VERSION "HNNBNNNYNNNNNNNNNNNNNNNNNNNNNNNNNNNNNNNNNN/4/%%%/4/'%**4NNN///"

NS_ :

BS_:

BU_: BAP_Tester BCM Gateway_Max TSGGen3_BFS TSGGen3_FS TSGGen3_HBFS TSGGen3_HFS WLC_01_CFD

BO_ 1427 BCM_Kessy_01: 8 BCM
 SG_ KY_IDGeber_1_Status : 0|3@1+ (1.0,0.0) [0.0|7] ""  Gateway_Max
 SG_ KY_IDGeber_2_Status : 3|3@1+ (1.0,0.0) [0.0|7] ""  Gateway_Max
 SG_ KY_Softtouch : 6|1@1+ (1.0,0.0) [0.0|1] ""  Gateway_Max
 SG_ KY_HD_Verriegelung_Autorisiert : 7|1@1+ (1.0,0.0) [0.0|1] ""  Gateway_Max
 SG_ KY_IDGeber_3_Status : 8|3@1+ (1.0,0.0) [0.0|7] ""  Gateway_Max
 SG_ KY_IDGeber_4_Status : 11|3@1+ (1.0,0.0) [0.0|7] ""  Gateway_Max
 SG_ ZV_Anf_Abschaltung_Zuendung : 14|1@1+ (1.0,0.0) [0.0|1] ""  Gateway_Max
 SG_ KY_FFB_in_LF_Reichw : 15|1@1+ (1.0,0.0) [0.0|1] ""  Gateway_Max
 SG_ KY_IDGeber_1_Bat : 16|2@1+ (1.0,0.0) [0.0|3] ""  Gateway_Max
 SG_ KY_IDGeber_2_Bat : 18|2@1+ (1.0,0.0) [0.0|3] ""  Gateway_Max
 SG_ KY_IDGeber_3_Bat : 20|2@1+ (1.0,0.0) [0.0|3] ""  Gateway_Max
 SG_ KY_IDGeber_4_Bat : 22|2@1+ (1.0,0.0) [0.0|3] ""  Gateway_Max
 SG_ KY_RSSI_Wert : 24|16@1+ (1.0,0.0) [0.0|65535] ""  Gateway_Max
 SG_ KY_Nr_IDGeber_Autofkt : 40|4@1+ (1.0,0.0) [0.0|15] ""  Gateway_Max
 SG_ KY_KessyEntryExit_Akt : 44|1@1+ (1.0,0.0) [0.0|1] ""  Gateway_Max
 SG_ KY_Autofunktion_Aktiv : 45|1@1+ (1.0,0.0) [0.0|1] ""  Gateway_Max
 SG_ KY_Anf_Reichwbegr : 46|1@1+ (1.0,0.0) [0.0|1] ""  Gateway_Max
 SG_ KY_Anf_Reichwbegr_Gesamt : 47|1@1+ (1.0,0.0) [0.0|1] ""  Gateway_Max
 SG_ KY_Bedienstelle : 48|6@1+ (1.0,0.0) [0.0|63] ""  Gateway_Max
 SG_ KY_Verriegeln : 54|1@1+ (1.0,0.0) [0.0|1] ""  Gateway_Max
 SG_ KY_Entriegeln : 55|1@1+ (1.0,0.0) [0.0|1] ""  Gateway_Max
 SG_ KY_ZV_CMD : 56|4@1+ (1.0,0.0) [0.0|15] ""  Gateway_Max
 SG_ KY_Schluesselnr : 60|4@1+ (1.0,0.0) [0.0|15] ""  Gateway_Max

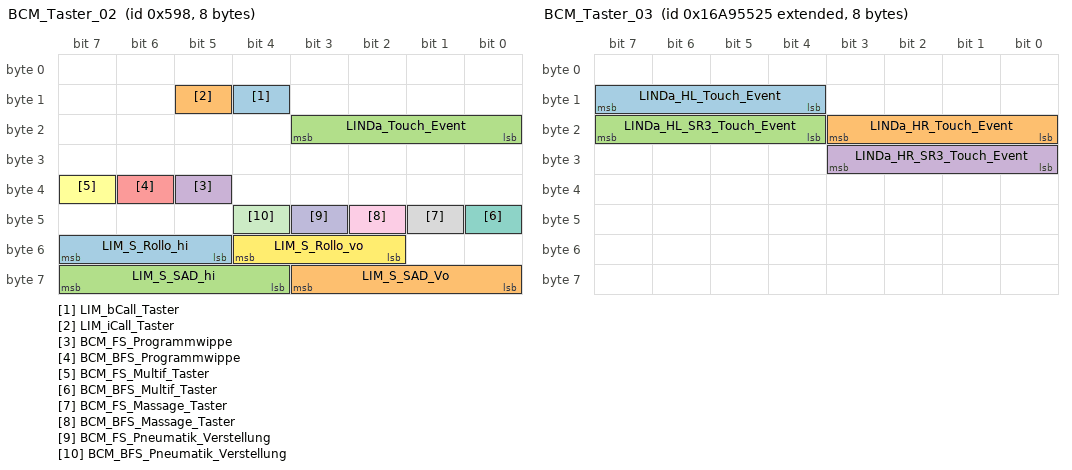
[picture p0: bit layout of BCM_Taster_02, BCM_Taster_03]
BO_ 1432 BCM_Taster_02: 8 BCM
 SG_ LIM_bCall_Taster : 12|1@1+ (1.0,0.0) [0.0|1] ""  Gateway_Max
 SG_ LIM_iCall_Taster : 13|1@1+ (1.0,0.0) [0.0|1] ""  Gateway_Max
 SG_ LINDa_Touch_Event : 16|4@1+ (1.0,0.0) [0.0|15] ""  Gateway_Max
 SG_ BCM_FS_Programmwippe : 37|1@1+ (1.0,0.0) [0.0|1] ""  Gateway_Max
 SG_ BCM_BFS_Programmwippe : 38|1@1+ (1.0,0.0) [0.0|1] ""  Gateway_Max
 SG_ BCM_FS_Multif_Taster : 39|1@1+ (1.0,0.0) [0.0|1] ""  Gateway_Max
 SG_ BCM_BFS_Multif_Taster : 40|1@1+ (1.0,0.0) [0.0|1] ""  Gateway_Max
 SG_ BCM_FS_Massage_Taster : 41|1@1+ (1.0,0.0) [0.0|1] ""  Gateway_Max
 SG_ BCM_BFS_Massage_Taster : 42|1@1+ (1.0,0.0) [0.0|1] ""  Gateway_Max
 SG_ BCM_FS_Pneumatik_Verstellung : 43|1@1+ (1.0,0.0) [0.0|1] ""  Gateway_Max
 SG_ BCM_BFS_Pneumatik_Verstellung : 44|1@1+ (1.0,0.0) [0.0|1] ""  Gateway_Max
 SG_ LIM_S_Rollo_vo : 50|3@1+ (1.0,0.0) [0.0|7] ""  Gateway_Max
 SG_ LIM_S_Rollo_hi : 53|3@1+ (1.0,0.0) [0.0|7] ""  Gateway_Max
 SG_ LIM_S_SAD_Vo : 56|4@1+ (1.0,0.0) [0.0|15] ""  Gateway_Max
 SG_ LIM_S_SAD_hi : 60|4@1+ (1.0,0.0) [0.0|15] ""  Gateway_Max

BO_ 2527679781 BCM_Taster_03: 8 BCM
 SG_ LINDa_HL_Touch_Event : 12|4@1+ (1.0,0.0) [0.0|15] ""  Gateway_Max
 SG_ LINDa_HR_Touch_Event : 16|4@1+ (1.0,0.0) [0.0|15] ""  Gateway_Max
 SG_ LINDa_HL_SR3_Touch_Event : 20|4@1+ (1.0,0.0) [0.0|15] ""  Gateway_Max
 SG_ LINDa_HR_SR3_Touch_Event : 24|4@1+ (1.0,0.0) [0.0|15] ""  Gateway_Max

BO_ 2463978855 BCM_ZDML_02: 8 BCM
 SG_ DML_HMI_FCN_CROSSINGLI_REQUEST : 12|1@1+ (1.0,0.0) [0.0|1] ""  Gateway_Max
 SG_ DML_HMI_FCN_HAZARDWARN_REQUEST : 13|1@1+ (1.0,0.0) [0.0|1] ""  Gateway_Max
 SG_ DML_HMI_FCN_LANELIGHT_REQUEST : 14|1@1+ (1.0,0.0) [0.0|1] ""  Gateway_Max
 SG_ DML_HMI_FCN_LANLEAVELI_REQUEST : 15|1@1+ (1.0,0.0) [0.0|1] ""  Gateway_Max
 SG_ DML_HMI_FCN_MALI_REQUEST : 16|1@1+ (1.0,0.0) [0.0|1] ""  Gateway_Max
 SG_ DML_HMI_FCN_ORLI_REQUEST : 17|1@1+ (1.0,0.0) [0.0|1] ""  Gateway_Max
 SG_ DML_HMI_FCN_RESALLEYHI_REQUEST : 18|1@1+ (1.0,0.0) [0.0|1] ""  Gateway_Max
 SG_ DML_HMI_FCN_ROADWORKLI_REQUEST : 19|1@1+ (1.0,0.0) [0.0|1] ""  Gateway_Max
 SG_ DML_HMI_FCN_SAFETYZONE_REQUEST : 20|1@1+ (1.0,0.0) [0.0|1] ""  Gateway_Max
 SG_ DML_HMI_FCN_TURNLIGHPR_REQUEST : 21|1@1+ (1.0,0.0) [0.0|1] ""  Gateway_Max
 SG_ DML_ConstructionZone_Enabled : 22|1@1+ (1.0,0.0) [0.0|1] ""  Gateway_Max
 SG_ DML_CrossingAssist_Enabled : 23|1@1+ (1.0,0.0) [0.0|1] ""  Gateway_Max
 SG_ DML_GhostDriverWarn_Enabled : 24|1@1+ (1.0,0.0) [0.0|1] ""  Gateway_Max
 SG_ DML_GlarefreeHB_Enabled : 25|1@1+ (1.0,0.0) [0.0|1] ""  Gateway_Max
 SG_ DML_HazardWarning_Enabled : 26|1@1+ (1.0,0.0) [0.0|1] ""  Gateway_Max
 SG_ DML_Indicator_Enabled : 27|1@1+ (1.0,0.0) [0.0|1] ""  Gateway_Max
 SG_ DML_IntelligentHB_Enabled : 28|1@1+ (1.0,0.0) [0.0|1] ""  Gateway_Max
 SG_ DML_LaneDepartureWarn_Enabled : 29|1@1+ (1.0,0.0) [0.0|1] ""  Gateway_Max
 SG_ DML_LaneLight_Enabled : 30|1@1+ (1.0,0.0) [0.0|1] ""  Gateway_Max
 SG_ DML_MarkingLight_Enabled : 31|1@1+ (1.0,0.0) [0.0|1] ""  Gateway_Max
 SG_ DML_OrientationLight_Enabled : 32|1@1+ (1.0,0.0) [0.0|1] ""  Gateway_Max
 SG_ DML_RescueLaneNotice_Enabled : 33|1@1+ (1.0,0.0) [0.0|1] ""  Gateway_Max
 SG_ DML_SafetyZone_Enabled : 34|1@1+ (1.0,0.0) [0.0|1] ""  Gateway_Max
 SG_ DML_SaftyDistance_Enabled : 35|1@1+ (1.0,0.0) [0.0|1] ""  Gateway_Max
 SG_ DML_SideAssist_Enabled : 36|1@1+ (1.0,0.0) [0.0|1] ""  Gateway_Max

BO_ 1635 BEM_02: 8 Gateway_Max
 SG_ NVEM_Abschaltstufe : 0|2@1+ (1.0,0.0) [0.0|3] ""  BCM,TSGGen3_BFS,TSGGen3_FS,TSGGen3_HBFS,TSGGen3_HFS,WLC_01_CFD
 SG_ BEM_STH_Zielzeit : 3|4@1+ (5,0) [0|60] "Unit_Minut"  BCM
 SG_ BEM_MMI_Vorwarnung : 7|1@1+ (1.0,0.0) [0.0|1] ""  BCM
 SG_ BEM_HL_Kontingentierung : 8|6@1+ (50,-1000) [-1000|1000] "Unit_Watt"  BCM
 SG_ NVEM_Freigabe_ZusBatt_Laden : 14|1@1+ (1.0,0.0) [0.0|1] ""  BCM
 SG_ NVEM_Anf_SD_schalten : 15|1@1+ (1.0,0.0) [0.0|1] ""  BCM
 SG_ BEM_Generatordiagnose : 16|2@1+ (1.0,0.0) [0.0|3] ""  BCM
 SG_ BEM_Red_Innengeblaese : 18|2@1+ (1.0,0.0) [0.0|3] ""  BCM
 SG_ BEM_STH_Einschaltverbot : 20|1@1+ (1.0,0.0) [0.0|1] ""  BCM
 SG_ BEM_HL_Regelung_Status : 21|3@1+ (1.0,0.0) [0.0|7] ""  BCM
 SG_ BEM_Ladezustand : 24|4@1+ (10,0) [0|100] "Unit_PerCent"  BCM
 SG_ BEM_Batteriediagnose : 28|3@1+ (1.0,0.0) [0.0|7] ""  BCM
 SG_ MIB_Stromsparmodus : 31|1@1+ (1.0,0.0) [0.0|1] ""  BCM
 SG_ BEM_DFM : 32|5@1+ (3.225,0.025) [0.025|100.000] ""  BCM
 SG_ BEM_REK_aktiv : 37|1@1+ (1.0,0.0) [0.0|1] ""  BCM
 SG_ BEM_EMLIN_ungueltig : 38|1@1+ (1.0,0.0) [0.0|1] ""  BCM
 SG_ BEM_Batt_Ab : 39|1@1+ (1.0,0.0) [0.0|1] ""  BCM
 SG_ BEM_UBDM : 40|8@1+ (0.05,5) [5.05|17.70] "Unit_Volt"  BCM
 SG_ BEM_UGenSoll : 48|6@1+ (0.1,10.6) [10.6|16.0] "Unit_Volt"  BCM
 SG_ BEM_Anf_KL15_schalten : 54|2@1+ (1.0,0.0) [0.0|3] ""  BCM
 SG_ NVEM_Batterie_Service : 56|2@1+ (1.0,0.0) [0.0|3] ""  BCM
 SG_ NVEM_Freigabe_OnlineUpdate : 58|1@1+ (1.0,0.0) [0.0|1] ""  BCM,TSGGen3_BFS,TSGGen3_FS,TSGGen3_HBFS,TSGGen3_HFS,WLC_01_CFD
 SG_ NVEM_Freigabe_ORU4 : 59|2@1+ (1.0,0.0) [0.0|3] ""  BCM
 SG_ NVEM_Verbraucherabsch_Anz : 61|1@1+ (1.0,0.0) [0.0|1] ""  BCM

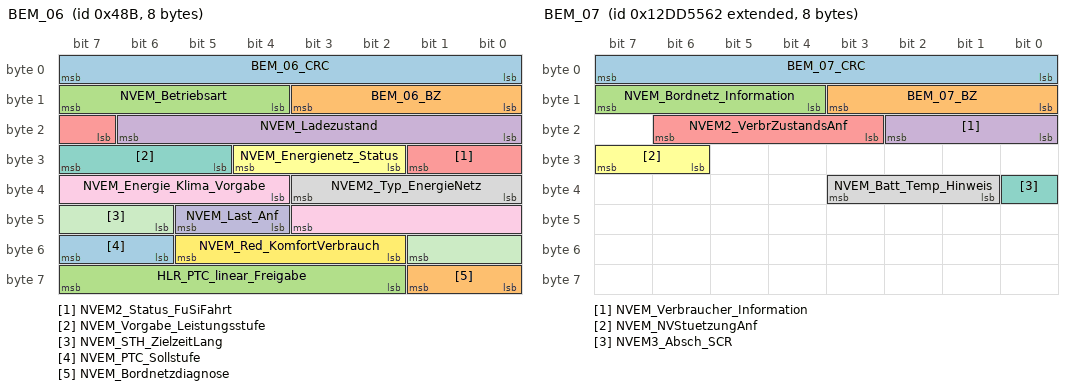
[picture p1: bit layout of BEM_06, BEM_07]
BO_ 1163 BEM_06: 8 Gateway_Max
 SG_ BEM_06_CRC : 0|8@1+ (1,0) [0|255] ""  Vector__XXX
 SG_ BEM_06_BZ : 8|4@1+ (1,0) [0|15] ""  Vector__XXX
 SG_ NVEM_Betriebsart : 12|4@1+ (1.0,0.0) [0.0|15] ""  Vector__XXX
 SG_ NVEM_Ladezustand : 16|7@1+ (1,0) [0|100] "Unit_PerCent"  Vector__XXX
 SG_ NVEM2_Status_FuSiFahrt : 23|3@1+ (1.0,0.0) [0.0|7] ""  Vector__XXX
 SG_ NVEM_Energienetz_Status : 26|3@1+ (1.0,0.0) [0.0|7] ""  Vector__XXX
 SG_ NVEM_Vorgabe_Leistungsstufe : 29|3@1+ (1.0,0.0) [0.0|7] ""  Vector__XXX
 SG_ NVEM2_Typ_EnergieNetz : 32|4@1+ (1.0,0.0) [0.0|15] ""  Vector__XXX
 SG_ NVEM_Energie_Klima_Vorgabe : 36|8@1+ (10,0) [0|2530] "Unit_WattHour"  Vector__XXX
 SG_ NVEM_Last_Anf : 44|2@1+ (1.0,0.0) [0.0|3] ""  TSGGen3_BFS,TSGGen3_FS,TSGGen3_HBFS,TSGGen3_HFS
 SG_ NVEM_STH_ZielzeitLang : 46|4@1+ (10,0) [0|120] "Unit_Minut"  Vector__XXX
 SG_ NVEM_Red_KomfortVerbrauch : 50|4@1+ (1.0,0.0) [0.0|15] ""  Vector__XXX
 SG_ NVEM_PTC_Sollstufe : 54|2@1+ (1.0,0.0) [0.0|3] ""  Vector__XXX
 SG_ NVEM_Bordnetzdiagnose : 56|2@1+ (1.0,0.0) [0.0|3] ""  Vector__XXX
 SG_ HLR_PTC_linear_Freigabe : 58|6@1+ (50,0) [0|3100] "Unit_Watt"  Vector__XXX

BO_ 2463978850 BEM_07: 8 Gateway_Max
 SG_ BEM_07_CRC : 0|8@1+ (1,0) [0|255] ""  Vector__XXX
 SG_ BEM_07_BZ : 8|4@1+ (1,0) [0|15] ""  Vector__XXX
 SG_ NVEM_Bordnetz_Information : 12|4@1+ (1.0,0.0) [0.0|15] ""  Vector__XXX
 SG_ NVEM_Verbraucher_Information : 16|3@1+ (1.0,0.0) [0.0|7] ""  Vector__XXX
 SG_ NVEM2_VerbrZustandsAnf : 19|4@1+ (1.0,0.0) [0.0|15] ""  TSGGen3_BFS,TSGGen3_FS
 SG_ NVEM_NVStuetzungAnf : 30|2@1+ (1.0,0.0) [0.0|3] ""  Vector__XXX
 SG_ NVEM3_Absch_SCR : 32|1@1+ (1.0,0.0) [0.0|1] ""  Vector__XXX
 SG_ NVEM_Batt_Temp_Hinweis : 33|3@1+ (1.0,0.0) [0.0|7] ""  Vector__XXX

BO_ 870 Blinkmodi_02: 8 BCM
 SG_ Blinkmodi_02_CRC : 0|8@1+ (1,0) [0|255] ""  Gateway_Max,TSGGen3_BFS,TSGGen3_FS
 SG_ Blinkmodi_02_BZ : 8|4@1+ (1,0) [0|15] ""  Gateway_Max,TSGGen3_BFS,TSGGen3_FS
 SG_ BM_ZV_auf : 12|1@1+ (1.0,0.0) [0.0|1] ""  Gateway_Max
 SG_ BM_ZV_zu : 13|1@1+ (1.0,0.0) [0.0|1] ""  Gateway_Max
 SG_ BM_DWA_ein : 14|1@1+ (1.0,0.0) [0.0|1] ""  Gateway_Max
 SG_ BM_DWA_Alarm : 15|1@1+ (1.0,0.0) [0.0|1] ""  Gateway_Max
 SG_ BM_Crash : 16|1@1+ (1.0,0.0) [0.0|1] ""  Gateway_Max
 SG_ BM_Panik : 17|1@1+ (1.0,0.0) [0.0|1] ""  Gateway_Max
 SG_ BM_Not_Bremsung : 18|1@1+ (1.0,0.0) [0.0|1] ""  Gateway_Max
 SG_ BM_GDO : 19|1@1+ (1.0,0.0) [0.0|1] ""  Gateway_Max
 SG_ BM_Warnblinken : 20|1@1+ (1.0,0.0) [0.0|1] ""  Gateway_Max
 SG_ BM_Taxi_Notalarm : 21|1@1+ (1.0,0.0) [0.0|1] ""  Gateway_Max
 SG_ BM_Telematik : 22|1@1+ (1.0,0.0) [0.0|1] ""  Gateway_Max
 SG_ BM_links : 23|1@1+ (1.0,0.0) [0.0|1] ""  Gateway_Max
 SG_ BM_rechts : 24|1@1+ (1.0,0.0) [0.0|1] ""  Gateway_Max
 SG_ Blinken_li_Fzg_Takt : 25|1@1+ (1.0,0.0) [0.0|1] ""  Gateway_Max,TSGGen3_BFS,TSGGen3_FS
 SG_ Blinken_re_Fzg_Takt : 26|1@1+ (1.0,0.0) [0.0|1] ""  Gateway_Max,TSGGen3_BFS,TSGGen3_FS
 SG_ Blinken_li_Kombi_Takt : 27|1@1+ (1.0,0.0) [0.0|1] ""  Gateway_Max
 SG_ Blinken_re_Kombi_Takt : 28|1@1+ (1.0,0.0) [0.0|1] ""  Gateway_Max
 SG_ BM_NBA_n_codiert_n_aktiv : 29|1@1+ (1.0,0.0) [0.0|1] ""  Gateway_Max
 SG_ BM_NBA_Status : 30|2@1+ (1.0,0.0) [0.0|3] ""  Gateway_Max
 SG_ BM_WBT_Beleuchtung : 32|1@1+ (1.0,0.0) [0.0|1] ""  Gateway_Max
 SG_ BM_HD_Oeffnung_angelernt : 33|1@1+ (1.0,0.0) [0.0|1] ""  Gateway_Max
 SG_ BM_Autobahn : 34|1@1+ (1.0,0.0) [0.0|1] ""  Gateway_Max
 SG_ BM_Rollenmodus_Blinken : 35|1@1+ (1.0,0.0) [0.0|1] ""  Gateway_Max
 SG_ BM_Recas : 36|1@1+ (1.0,0.0) [0.0|1] ""  Gateway_Max
 SG_ BM_Wischblinken : 37|1@1+ (1.0,0.0) [0.0|1] ""  Gateway_Max
 SG_ BM_Telematik_Abbruchgrund : 38|6@1+ (1.0,0.0) [0.0|63] ""  Gateway_Max
 SG_ BM_PiloPa : 44|1@1+ (1.0,0.0) [0.0|1] ""  Gateway_Max
 SG_ SAL_TA_Blinken_Status : 45|3@1+ (1.0,0.0) [0.0|7] ""  Gateway_Max
 SG_ BM_WBA_Warnblinken : 48|1@1+ (1.0,0.0) [0.0|1] ""  Gateway_Max
 SG_ SAL_RHP_Blinken_Status : 49|3@1+ (1.0,0.0) [0.0|7] ""  Gateway_Max
 SG_ SAL_RHP_Warnblinken : 52|1@1+ (1.0,0.0) [0.0|1] ""  Gateway_Max

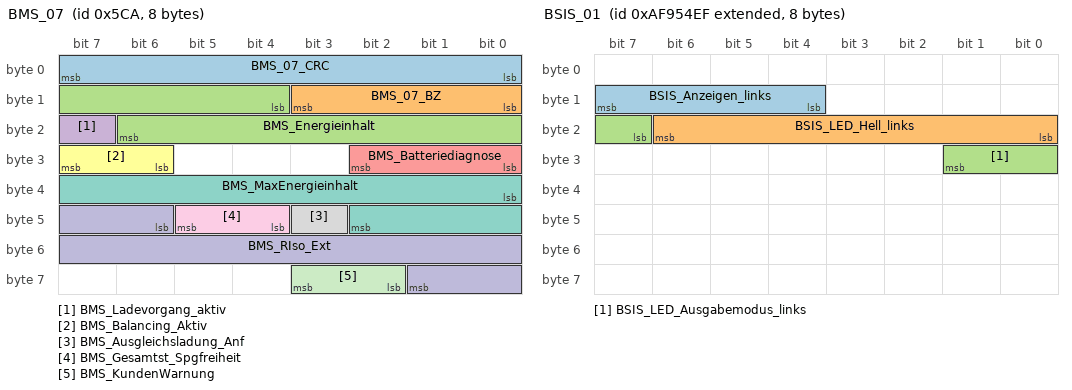
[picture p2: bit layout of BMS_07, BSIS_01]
BO_ 1482 BMS_07: 8 Gateway_Max
 SG_ BMS_07_CRC : 0|8@1+ (1,0) [0|255] ""  Vector__XXX
 SG_ BMS_07_BZ : 8|4@1+ (1,0) [0|15] ""  Vector__XXX
 SG_ BMS_Energieinhalt : 12|11@1+ (50,0) [0|102250] "Unit_WattHour"  Vector__XXX
 SG_ BMS_Ladevorgang_aktiv : 23|1@1+ (1.0,0.0) [0.0|1] ""  Vector__XXX
 SG_ BMS_Batteriediagnose : 24|3@1+ (1.0,0.0) [0.0|7] ""  Vector__XXX
 SG_ BMS_Balancing_Aktiv : 30|2@1+ (1.0,0.0) [0.0|3] ""  Vector__XXX
 SG_ BMS_MaxEnergieinhalt : 32|11@1+ (50,0) [0|102250] "Unit_WattHour"  Vector__XXX
 SG_ BMS_Ausgleichsladung_Anf : 43|1@1+ (1.0,0.0) [0.0|1] ""  Vector__XXX
 SG_ BMS_Gesamtst_Spgfreiheit : 44|2@1+ (1.0,0.0) [0.0|3] ""  Vector__XXX
 SG_ BMS_RIso_Ext : 46|12@1+ (5,0) [0|20465] "Unit_KiloOhm"  Vector__XXX
 SG_ BMS_KundenWarnung : 58|2@1+ (1.0,0.0) [0.0|3] ""  BCM

BO_ 2331596015 BSIS_01: 8 Gateway_Max
 SG_ BSIS_Anzeigen_links : 12|4@1+ (1.0,0.0) [0.0|15] ""  Vector__XXX
 SG_ BSIS_LED_Hell_links : 16|7@1+ (1,0) [0|100] "Unit_PerCent"  TSGGen3_BFS,TSGGen3_FS
 SG_ BSIS_LED_Ausgabemodus_links : 23|3@1+ (1.0,0.0) [0.0|7] ""  TSGGen3_BFS,TSGGen3_FS

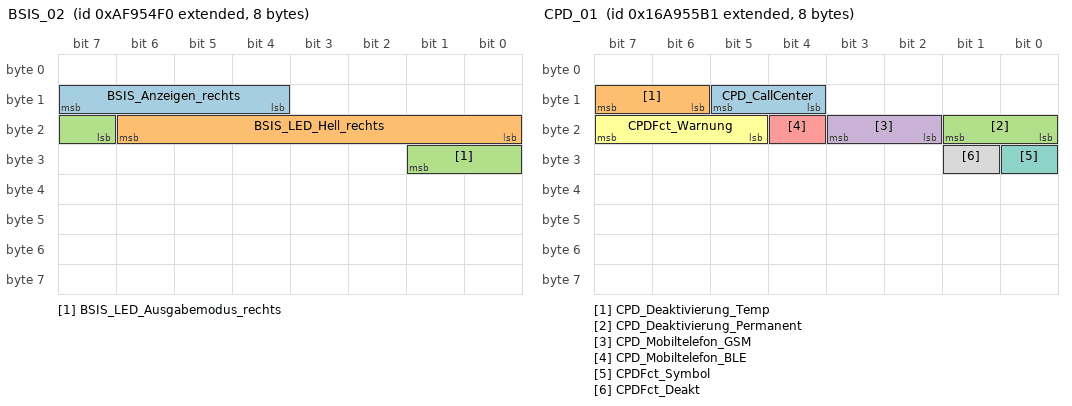
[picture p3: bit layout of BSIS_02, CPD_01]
BO_ 2331596016 BSIS_02: 8 Gateway_Max
 SG_ BSIS_Anzeigen_rechts : 12|4@1+ (1.0,0.0) [0.0|15] ""  Vector__XXX
 SG_ BSIS_LED_Hell_rechts : 16|7@1+ (1,0) [0|100] "Unit_PerCent"  TSGGen3_BFS,TSGGen3_FS
 SG_ BSIS_LED_Ausgabemodus_rechts : 23|3@1+ (1.0,0.0) [0.0|7] ""  TSGGen3_BFS,TSGGen3_FS

BO_ 2463978792 CentralLocking_01: 24 BCM
 SG_ CentralLocking_01_CRC : 0|8@1+ (1,0) [0|255] ""  Gateway_Max
 SG_ CentralLocking_01_BZ : 8|4@1+ (1,0) [0|15] ""  Gateway_Max,TSGGen3_BFS,TSGGen3_FS,TSGGen3_HBFS,TSGGen3_HFS
 SG_ ZV_auto_Ansteuerung : 23|1@1+ (1.0,0.0) [0.0|1] ""  Gateway_Max,TSGGen3_BFS,TSGGen3_FS,TSGGen3_HBFS,TSGGen3_HFS
 SG_ ZV_Bedienstelle_auf : 24|4@1+ (1.0,0.0) [0.0|15] ""  Gateway_Max,TSGGen3_BFS,TSGGen3_FS,TSGGen3_HBFS,TSGGen3_HFS
 SG_ ZV_Bedienstelle_zu : 28|4@1+ (1.0,0.0) [0.0|15] ""  Gateway_Max,TSGGen3_BFS,TSGGen3_FS,TSGGen3_HBFS,TSGGen3_HFS
 SG_ ZV_BT_entriegeln : 32|1@1+ (1.0,0.0) [0.0|1] ""  Gateway_Max,TSGGen3_BFS
 SG_ ZV_BT_verriegeln : 34|1@1+ (1.0,0.0) [0.0|1] ""  Gateway_Max,TSGGen3_BFS
 SG_ ZV_Crashfall_erkannt : 35|1@1+ (1.0,0.0) [0.0|1] ""  Gateway_Max,TSGGen3_BFS,TSGGen3_FS,TSGGen3_HBFS,TSGGen3_HFS
 SG_ ZV_FT_entriegeln : 45|1@1+ (1.0,0.0) [0.0|1] ""  Gateway_Max,TSGGen3_FS
 SG_ ZV_FT_verriegeln : 47|1@1+ (1.0,0.0) [0.0|1] ""  Gateway_Max,TSGGen3_FS
 SG_ ZV_HBFS_entriegeln : 48|1@1+ (1.0,0.0) [0.0|1] ""  Gateway_Max,TSGGen3_HBFS
 SG_ ZV_HBFS_verriegeln : 50|1@1+ (1.0,0.0) [0.0|1] ""  Gateway_Max,TSGGen3_HBFS
 SG_ ZV_HFS_entriegeln : 51|1@1+ (1.0,0.0) [0.0|1] ""  Gateway_Max,TSGGen3_HFS
 SG_ ZV_HFS_verriegeln : 53|1@1+ (1.0,0.0) [0.0|1] ""  Gateway_Max,TSGGen3_HFS
 SG_ ZV_LED_Steuerung : 58|1@1+ (1.0,0.0) [0.0|1] ""  Gateway_Max,TSGGen3_FS
 SG_ ZV_LED_Uebernahme : 59|1@1+ (1.0,0.0) [0.0|1] ""  Gateway_Max,TSGGen3_FS
 SG_ ZV_gesafet_extern_ist_02 : 60|2@1+ (1.0,0.0) [0.0|3] ""  Gateway_Max,TSGGen3_BFS,TSGGen3_FS,TSGGen3_HBFS,TSGGen3_HFS
 SG_ ZV_Schluessel_Zugang : 63|4@1+ (1.0,0.0) [0.0|15] ""  Gateway_Max,TSGGen3_BFS,TSGGen3_FS,TSGGen3_HBFS,TSGGen3_HFS
 SG_ ZV_Signatur : 67|11@1+ (1,0) [0|2047] ""  Gateway_Max,TSGGen3_BFS,TSGGen3_FS,TSGGen3_HBFS,TSGGen3_HFS
 SG_ ZV_Spg_Anklappen : 78|1@1+ (1.0,0.0) [0.0|1] ""  Gateway_Max,TSGGen3_BFS,TSGGen3_FS
 SG_ ZV_verriegelt_extern_soll_03 : 83|2@1+ (1.0,0.0) [0.0|3] ""  Gateway_Max,TSGGen3_BFS,TSGGen3_FS,TSGGen3_HBFS,TSGGen3_HFS
 SG_ ZV_zentral_entsafen : 86|1@1+ (1.0,0.0) [0.0|1] ""  Gateway_Max,TSGGen3_BFS,TSGGen3_FS,TSGGen3_HBFS,TSGGen3_HFS
 SG_ ZV_zentral_safen : 87|1@1+ (1.0,0.0) [0.0|1] ""  Gateway_Max,TSGGen3_BFS,TSGGen3_FS,TSGGen3_HBFS,TSGGen3_HFS
 SG_ ZV_zu_Zeitl_Nachverr : 90|1@1+ (1.0,0.0) [0.0|1] ""  Gateway_Max,TSGGen3_BFS,TSGGen3_FS,TSGGen3_HBFS,TSGGen3_HFS
 SG_ ZV_TAG_BT_verfahren : 91|2@1+ (1.0,0.0) [0.0|3] ""  Gateway_Max,TSGGen3_BFS
 SG_ ZV_TAG_HBFS_verfahren : 93|2@1+ (1.0,0.0) [0.0|3] ""  Gateway_Max,TSGGen3_HBFS
 SG_ ZV_TAG_FT_verfahren : 95|2@1+ (1.0,0.0) [0.0|3] ""  Gateway_Max,TSGGen3_FS
 SG_ ZV_TAG_HFS_verfahren : 97|2@1+ (1.0,0.0) [0.0|3] ""  Gateway_Max,TSGGen3_HFS
 SG_ IRUE_Taster_Fkts_LED : 99|1@1+ (1.0,0.0) [0.0|1] ""  Gateway_Max,TSGGen3_FS
 SG_ DWA_aktiv : 105|1@1+ (1.0,0.0) [0.0|1] ""  Gateway_Max
 SG_ ZV_verriegelt_intern_soll_02 : 112|2@1+ (1.0,0.0) [0.0|3] ""  Gateway_Max,TSGGen3_BFS,TSGGen3_FS,TSGGen3_HBFS,TSGGen3_HFS
 SG_ ZV_Status_eTAG_ist : 114|2@1+ (1.0,0.0) [0.0|3] ""  Gateway_Max,TSGGen3_BFS,TSGGen3_FS,TSGGen3_HBFS,TSGGen3_HFS
 SG_ ZV_Status_eTAG_soll : 116|2@1+ (1.0,0.0) [0.0|3] ""  Gateway_Max,TSGGen3_BFS,TSGGen3_FS,TSGGen3_HBFS,TSGGen3_HFS
 SG_ ZV_verriegelt_extern_ist_02 : 118|2@1+ (1.0,0.0) [0.0|3] ""  Gateway_Max,TSGGen3_BFS,TSGGen3_FS,TSGGen3_HBFS,TSGGen3_HFS
 SG_ ZV_gesafet_extern_soll_02 : 123|2@1+ (1.0,0.0) [0.0|3] ""  Gateway_Max,TSGGen3_BFS,TSGGen3_FS,TSGGen3_HBFS,TSGGen3_HFS
 SG_ ZV_verriegelt_intern_ist_02 : 125|2@1+ (1.0,0.0) [0.0|3] ""  Gateway_Max,TSGGen3_BFS,TSGGen3_FS,TSGGen3_HBFS,TSGGen3_HFS
 SG_ ZV_Frontschloss_Vorraste : 146|2@1+ (1.0,0.0) [0.0|3] ""  Gateway_Max
 SG_ SOK_CentralLocking_01_Signatur : 160|32@1+ (1,0) [0|4294967295] ""  Gateway_Max,TSGGen3_BFS,TSGGen3_FS,TSGGen3_HBFS,TSGGen3_HFS

BO_ 902 Charisma_03: 8 Gateway_Max
 SG_ CHA_Charisma_Taste2_LED : 0|2@1+ (1.0,0.0) [0.0|3] ""  Vector__XXX
 SG_ CHA_ReqPrgDispSetup : 2|4@1+ (1.0,0.0) [0.0|15] ""  Vector__XXX
 SG_ CHA_Current_Mode_FPA : 6|6@1+ (1.0,0.0) [0.0|63] ""  Vector__XXX
 SG_ CHA_Eco_Charisma_LED : 12|2@1+ (1.0,0.0) [0.0|3] ""  Vector__XXX
 SG_ CHA_Fahrer_Umschaltung : 14|1@1+ (1.0,0.0) [0.0|1] ""  BCM
 SG_ CHA_EV_LED : 15|1@1+ (1.0,0.0) [0.0|1] ""  Vector__XXX
 SG_ CHA_Ziel_FahrPr_AMB : 16|4@1+ (1.0,0.0) [0.0|15] ""  BCM
 SG_ CHA_Ziel_FahrPr_IVB : 20|4@1+ (1.0,0.0) [0.0|15] ""  Vector__XXX
 SG_ CHA_Kombi_Texte : 24|4@1+ (1.0,0.0) [0.0|15] ""  Vector__XXX
 SG_ CHA_Ziel_FahrPr_KL : 28|4@1+ (1.0,0.0) [0.0|15] ""  TSGGen3_FS
 SG_ CHA_Ziel_FahrPr_HSP : 32|4@1+ (1.0,0.0) [0.0|15] ""  Vector__XXX
 SG_ CHA_StCurProfDft : 36|2@1+ (1.0,0.0) [0.0|3] ""  Vector__XXX
 SG_ CHA_Ziel_FahrPr_RWB : 40|4@1+ (1.0,0.0) [0.0|15] ""  Vector__XXX
 SG_ CHA_Ziel_FahrPr_03_01 : 44|4@1+ (1.0,0.0) [0.0|15] ""  Vector__XXX
 SG_ CHA_Ziel_FahrPr_03_02 : 48|4@1+ (1.0,0.0) [0.0|15] ""  Vector__XXX
 SG_ CHA_Current_Mode : 52|4@1+ (1.0,0.0) [0.0|15] ""  Vector__XXX
 SG_ CHA_Charge_LED : 57|1@1+ (1.0,0.0) [0.0|1] ""  Vector__XXX
 SG_ CHA_Offroad_LED : 58|2@1+ (1.0,0.0) [0.0|3] ""  Vector__XXX
 SG_ CHA_Kombi_Texte_02 : 60|4@1+ (1.0,0.0) [0.0|15] ""  Vector__XXX

BO_ 2463978646 Charisma_11: 24 Gateway_Max
 SG_ CHA_Ziel_FahrPr_AGA : 0|4@1+ (1.0,0.0) [0.0|15] ""  Vector__XXX
 SG_ CHA_Ziel_FahrPr_ESP : 4|4@1+ (1.0,0.0) [0.0|15] ""  Vector__XXX
 SG_ CHA_Ziel_FahrPr_Freilauf : 8|4@1+ (1.0,0.0) [0.0|15] ""  Vector__XXX
 SG_ CHA_Fahrer_Umschaltung : 14|1@1+ (1.0,0.0) [0.0|1] ""  Vector__XXX
 SG_ CHA_Fahrer_Umschaltung_BMA : 15|1@1+ (1.0,0.0) [0.0|1] ""  Vector__XXX
 SG_ CHA_Ziel_FahrPr_MO : 16|4@1+ (1.0,0.0) [0.0|15] ""  Vector__XXX
 SG_ CHA_Ziel_FahrPr_GE : 20|4@1+ (1.0,0.0) [0.0|15] ""  Vector__XXX
 SG_ CHA_Ziel_FahrPr_ALR : 24|4@1+ (1.0,0.0) [0.0|15] ""  Vector__XXX
 SG_ CHA_Ziel_FahrPr_MO_BZS : 28|4@1+ (1.0,0.0) [0.0|15] ""  Vector__XXX
 SG_ CHA_Ziel_FahrPr_DR : 32|4@1+ (1.0,0.0) [0.0|15] ""  Vector__XXX
 SG_ CHA_Ziel_FahrPr_VAQ : 36|4@1+ (1.0,0.0) [0.0|15] ""  Vector__XXX
 SG_ CHA_Ziel_FahrPr_AFS : 40|4@1+ (1.0,0.0) [0.0|15] ""  BCM
 SG_ CHA_Ziel_FahrPr_PreCrash : 44|4@1+ (1.0,0.0) [0.0|15] ""  Vector__XXX
 SG_ CHA_Ziel_FahrPr_EPS : 48|4@1+ (1.0,0.0) [0.0|15] ""  Vector__XXX
 SG_ CHA_Ziel_FahrPr_ACC : 52|4@1+ (1.0,0.0) [0.0|15] ""  Vector__XXX
 SG_ CHA_Ziel_FahrPr_SAK : 56|4@1+ (1.0,0.0) [0.0|15] ""  Vector__XXX
 SG_ CHA_Ziel_FahrPr_MO_StSt : 60|4@1+ (1.0,0.0) [0.0|15] ""  Vector__XXX
 SG_ CHA_Ziel_FahrPr_EBKV : 64|4@1+ (1.0,0.0) [0.0|15] ""  Vector__XXX
 SG_ CHA_Ziel_FahrPr_IL : 68|4@1+ (1.0,0.0) [0.0|15] ""  Vector__XXX
 SG_ CHA_Current_Mode : 72|4@1+ (1.0,0.0) [0.0|15] ""  Vector__XXX
 SG_ CHA_Ziel_FahrPr_QS : 80|4@1+ (1.0,0.0) [0.0|15] ""  Vector__XXX
 SG_ CHA_Ziel_FahrPr_SCU : 84|4@1+ (1.0,0.0) [0.0|15] ""  Vector__XXX
 SG_ CHA_Ziel_FahrPr_HAL : 88|4@1+ (1.0,0.0) [0.0|15] ""  Vector__XXX
 SG_ CHA_Ziel_FahrPr_NR : 92|4@1+ (1.0,0.0) [0.0|15] ""  Vector__XXX
 SG_ CHA_Ziel_FahrPr_AV : 96|4@1+ (1.0,0.0) [0.0|15] ""  Vector__XXX
 SG_ CHA_Ziel_FahrPr_MXB : 100|4@1+ (1.0,0.0) [0.0|15] ""  Vector__XXX
 SG_ CHA_Ziel_FahrPr_AFR : 104|4@1+ (1.0,0.0) [0.0|15] ""  Vector__XXX
 SG_ CHA_Ziel_FahrPr_HDC : 108|4@1+ (1.0,0.0) [0.0|15] ""  Vector__XXX
 SG_ CHA_Ziel_FahrPr_EAR : 112|4@1+ (1.0,0.0) [0.0|15] ""  Vector__XXX
 SG_ CHA_Ziel_FahrPr_AEB : 116|4@1+ (1.0,0.0) [0.0|15] ""  Vector__XXX
 SG_ CHA_Ziel_FahrPr_FCWO : 120|4@1+ (1.0,0.0) [0.0|15] ""  Vector__XXX
 SG_ CHA_Ziel_FahrPr_FCWP : 124|4@1+ (1.0,0.0) [0.0|15] ""  Vector__XXX
 SG_ CHA_Ziel_FahrPr_eSound : 136|4@1+ (1.0,0.0) [0.0|15] ""  Vector__XXX
 SG_ CHA_Ziel_FahrPr_RHP : 140|4@1+ (1.0,0.0) [0.0|15] ""  Vector__XXX
 SG_ CHA_Ziel_FahrPr_ToS_laengs : 144|4@1+ (1.0,0.0) [0.0|15] ""  Vector__XXX
 SG_ CHA_Ziel_FahrPr_ToS_quer : 148|4@1+ (1.0,0.0) [0.0|15] ""  Vector__XXX
 SG_ CHA_Ziel_FahrPr_mFDR : 152|4@1+ (1.0,0.0) [0.0|15] ""  Vector__XXX
 SG_ CHA_Ziel_FahrPr_Reku_ZwGas : 156|4@1+ (1.0,0.0) [0.0|15] ""  Vector__XXX
 SG_ CHA_Ziel_FahrPr_MO_Freilauf : 160|4@1+ (1.0,0.0) [0.0|15] ""  Vector__XXX
 SG_ CHA_Ziel_FahrPr_BMS : 164|4@1+ (1.0,0.0) [0.0|15] ""  Vector__XXX
 SG_ CHA_Ziel_FahrPr_PDC : 172|4@1+ (1.0,0.0) [0.0|15] ""  Vector__XXX
 SG_ CHA_Ziel_FahrPr_HHC : 176|4@1+ (1.0,0.0) [0.0|15] ""  Vector__XXX
 SG_ CHA_Ziel_FahrPr_EDS : 180|4@1+ (1.0,0.0) [0.0|15] ""  Vector__XXX
 SG_ CHA_Ziel_FahrPr_PACC : 184|4@1+ (1.0,0.0) [0.0|15] ""  Vector__XXX
 SG_ CHA_Ziel_FahrPr_AGK : 188|4@1+ (1.0,0.0) [0.0|15] ""  Vector__XXX

BO_ 2527679921 CPD_01: 8 BCM
 SG_ CPD_CallCenter : 12|2@1+ (1.0,0.0) [0.0|3] ""  Gateway_Max
 SG_ CPD_Deaktivierung_Temp : 14|2@1+ (1.0,0.0) [0.0|3] ""  Gateway_Max
 SG_ CPD_Deaktivierung_Permanent : 16|2@1+ (1.0,0.0) [0.0|3] ""  Gateway_Max
 SG_ CPD_Mobiltelefon_GSM : 18|2@1+ (1.0,0.0) [0.0|3] ""  Gateway_Max
 SG_ CPD_Mobiltelefon_BLE : 20|1@1+ (1.0,0.0) [0.0|1] ""  Gateway_Max
 SG_ CPDFct_Warnung : 21|3@1+ (1.0,0.0) [0.0|7] ""  Gateway_Max
 SG_ CPDFct_Symbol : 24|1@1+ (1.0,0.0) [0.0|1] ""  Gateway_Max
 SG_ CPDFct_Deakt : 25|1@1+ (1.0,0.0) [0.0|1] ""  Gateway_Max

BO_ 2331595987 CPD_02: 12 Gateway_Max
 SG_ CPD_Sensierung_Status : 12|3@1+ (1.0,0.0) [0.0|7] ""  BCM
 SG_ CPD_Warnstufe : 15|3@1+ (1.0,0.0) [0.0|7] ""  BCM

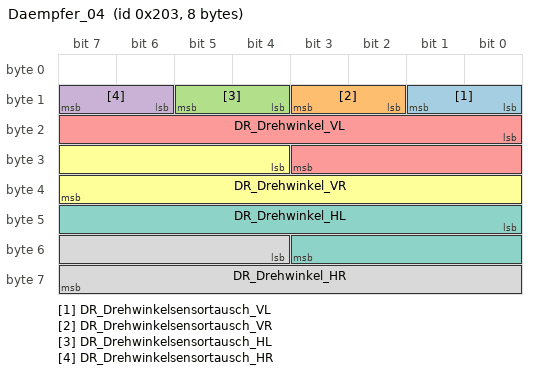
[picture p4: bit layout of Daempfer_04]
BO_ 515 Daempfer_04: 8 Gateway_Max
 SG_ DR_Drehwinkelsensortausch_VL : 8|2@1+ (1,0) [1|3] ""  BCM
 SG_ DR_Drehwinkelsensortausch_VR : 10|2@1+ (1,0) [1|3] ""  BCM
 SG_ DR_Drehwinkelsensortausch_HL : 12|2@1+ (1,0) [1|3] ""  BCM
 SG_ DR_Drehwinkelsensortausch_HR : 14|2@1+ (1,0) [1|3] ""  BCM
 SG_ DR_Drehwinkel_VL : 16|12@1+ (0.088,0) [0.000|359.920] ""  BCM
 SG_ DR_Drehwinkel_VR : 28|12@1+ (0.088,0) [0.000|359.920] ""  BCM
 SG_ DR_Drehwinkel_HL : 40|12@1+ (0.088,0) [0.000|359.920] ""  BCM
 SG_ DR_Drehwinkel_HR : 52|12@1+ (0.088,0) [0.000|359.920] ""  BCM

BO_ 2583738904 DDA_AuthTime_Req: 8 BCM
 SG_ DDA_AuthTime_Req_Data : 0|64@1+ (1.0,0.0) [0.0|18446744073709551615] ""  Gateway_Max

BO_ 2583869976 DDA_AuthTime_Resp: 8 Gateway_Max
 SG_ DDA_AuthTime_Resp_Data : 0|64@1+ (1.0,0.0) [0.0|18446744073709551615] ""  BCM

BO_ 2617103104 DEV_DDA_Req_00: 8 Vector__XXX
 SG_ DEV_DDA_Req_00_Data : 0|64@1+ (1.0,0.0) [0.0|18446744073709551615] ""  BCM

BO_ 2617103359 DEV_DDA_Resp_FF: 8 BCM
 SG_ DEV_DDA_Resp_FF_Data : 0|64@1+ (1.0,0.0) [0.0|18446744073709551615] ""  Vector__XXX

BO_ 2566843136 DEV_NFC_TGS_Resp_00: 8 BCM
 SG_ DEV_NFC_TGS_Resp_00_Data : 0|64@1+ (1.0,0.0) [0.0|18446744073709551615] ""  Vector__XXX

BO_ 2566843391 DEV_NFC_TGS_Resp_FF: 8 BCM
 SG_ DEV_NFC_TGS_Resp_FF_Data : 0|64@1+ (1.0,0.0) [0.0|18446744073709551615] ""  Vector__XXX

BO_ 2549891585 DIA_eTABSub_BFS_Req: 8 Gateway_Max
 SG_ DIA_eTABSub_BFS_Req_Data : 0|64@1+ (1.0,0.0) [0.0|18446744073709551615] ""  TSGGen3_BFS

BO_ 2621456897 DIA_eTABSub_BFS_Req_FD: 64 Gateway_Max
 SG_ DIA_eTABSub_BFS_Req_FD_Data : 0|512@1+ (1.0,0.0) [0.0|13407807929942597099574024998205846127479365820592393377723561443721764030073546976801874298166903427690031858186486050853753882811946569946433649006084095] ""  TSGGen3_BFS

BO_ 2550022657 DIA_eTABSub_BFS_Resp: 8 TSGGen3_BFS
 SG_ DIA_eTABSub_BFS_Resp_Data : 0|64@1+ (1.0,0.0) [0.0|18446744073709551615] ""  Gateway_Max

BO_ 2621587969 DIA_eTABSub_BFS_Resp_FD: 64 TSGGen3_BFS
 SG_ DIA_eTABSub_BFS_Resp_FD_Data : 0|512@1+ (1.0,0.0) [0.0|13407807929942597099574024998205846127479365820592393377723561443721764030073546976801874298166903427690031858186486050853753882811946569946433649006084095] ""  Gateway_Max

BO_ 2549891584 DIA_eTABSub_FS_Req: 8 Gateway_Max
 SG_ DIA_eTABSub_FS_Req_Data : 0|64@1+ (1.0,0.0) [0.0|18446744073709551615] ""  TSGGen3_FS

BO_ 2621456896 DIA_eTABSub_FS_Req_FD: 64 Gateway_Max
 SG_ DIA_eTABSub_FS_Req_FD_Data : 0|512@1+ (1.0,0.0) [0.0|13407807929942597099574024998205846127479365820592393377723561443721764030073546976801874298166903427690031858186486050853753882811946569946433649006084095] ""  TSGGen3_FS

BO_ 2550022656 DIA_eTABSub_FS_Resp: 8 TSGGen3_FS
 SG_ DIA_eTABSub_FS_Resp_Data : 0|64@1+ (1.0,0.0) [0.0|18446744073709551615] ""  Gateway_Max

BO_ 2621587968 DIA_eTABSub_FS_Resp_FD: 64 TSGGen3_FS
 SG_ DIA_eTABSub_FS_Resp_FD_Data : 0|512@1+ (1.0,0.0) [0.0|13407807929942597099574024998205846127479365820592393377723561443721764030073546976801874298166903427690031858186486050853753882811946569946433649006084095] ""  Gateway_Max

BO_ 2549891587 DIA_eTABSub_HBFS_Req: 8 Gateway_Max
 SG_ DIA_eTABSub_HBFS_Req_Data : 0|64@1+ (1.0,0.0) [0.0|18446744073709551615] ""  TSGGen3_HBFS

BO_ 2621456899 DIA_eTABSub_HBFS_Req_FD: 64 Gateway_Max
 SG_ DIA_eTABSub_HBFS_Req_FD_Data : 0|512@1+ (1.0,0.0) [0.0|13407807929942597099574024998205846127479365820592393377723561443721764030073546976801874298166903427690031858186486050853753882811946569946433649006084095] ""  TSGGen3_HBFS

BO_ 2550022659 DIA_eTABSub_HBFS_Resp: 8 TSGGen3_HBFS
 SG_ DIA_eTABSub_HBFS_Resp_Data : 0|64@1+ (1.0,0.0) [0.0|18446744073709551615] ""  Gateway_Max

BO_ 2621587971 DIA_eTABSub_HBFS_Resp_FD: 64 TSGGen3_HBFS
 SG_ DIA_eTABSub_HBFS_Resp_FD_Data : 0|512@1+ (1.0,0.0) [0.0|13407807929942597099574024998205846127479365820592393377723561443721764030073546976801874298166903427690031858186486050853753882811946569946433649006084095] ""  Gateway_Max

BO_ 2549891586 DIA_eTABSub_HFS_Req: 8 Gateway_Max
 SG_ DIA_eTABSub_HFS_Req_Data : 0|64@1+ (1.0,0.0) [0.0|18446744073709551615] ""  TSGGen3_HFS

BO_ 2621456898 DIA_eTABSub_HFS_Req_FD: 64 Gateway_Max
 SG_ DIA_eTABSub_HFS_Req_FD_Data : 0|512@1+ (1.0,0.0) [0.0|13407807929942597099574024998205846127479365820592393377723561443721764030073546976801874298166903427690031858186486050853753882811946569946433649006084095] ""  TSGGen3_HFS

BO_ 2550022658 DIA_eTABSub_HFS_Resp: 8 TSGGen3_HFS
 SG_ DIA_eTABSub_HFS_Resp_Data : 0|64@1+ (1.0,0.0) [0.0|18446744073709551615] ""  Gateway_Max

BO_ 2621587970 DIA_eTABSub_HFS_Resp_FD: 64 TSGGen3_HFS
 SG_ DIA_eTABSub_HFS_Resp_FD_Data : 0|512@1+ (1.0,0.0) [0.0|13407807929942597099574024998205846127479365820592393377723561443721764030073546976801874298166903427690031858186486050853753882811946569946433649006084095] ""  Gateway_Max

BO_ 2549880555 DIA_NFC_TGS_Req: 8 Gateway_Max
 SG_ DIA_NFC_TGS_Req_Data : 0|64@1+ (1.0,0.0) [0.0|18446744073709551615] ""  BCM

BO_ 2550011627 DIA_NFC_TGS_Resp: 8 BCM
 SG_ DIA_NFC_TGS_Resp_Data : 0|64@1+ (1.0,0.0) [0.0|18446744073709551615] ""  Gateway_Max

BO_ 2549880322 DIA_RLF_Req: 8 Gateway_Max
 SG_ DIA_RLF_Req_Data : 0|64@1+ (1.0,0.0) [0.0|18446744073709551615] ""  BCM

BO_ 2621445634 DIA_RLF_Req_FD: 64 Gateway_Max
 SG_ DIA_RLF_Req_FD_Data : 0|512@1+ (1.0,0.0) [0.0|13407807929942597099574024998205846127479365820592393377723561443721764030073546976801874298166903427690031858186486050853753882811946569946433649006084095] ""  BCM

BO_ 2550011394 DIA_RLF_Resp: 8 BCM
 SG_ DIA_RLF_Resp_Data : 0|64@1+ (1.0,0.0) [0.0|18446744073709551615] ""  Gateway_Max

BO_ 2621576706 DIA_RLF_Resp_FD: 64 BCM
 SG_ DIA_RLF_Resp_FD_Data : 0|512@1+ (1.0,0.0) [0.0|13407807929942597099574024998205846127479365820592393377723561443721764030073546976801874298166903427690031858186486050853753882811946569946433649006084095] ""  Gateway_Max

BO_ 2549880357 DIA_SHL_li1_Req: 8 Gateway_Max
 SG_ DIA_SHL_li1_Req_Data : 0|64@1+ (1.0,0.0) [0.0|18446744073709551615] ""  BCM

BO_ 2621445669 DIA_SHL_li1_Req_FD: 64 Gateway_Max
 SG_ DIA_SHL_li1_Req_FD_Data : 0|512@1+ (1.0,0.0) [0.0|13407807929942597099574024998205846127479365820592393377723561443721764030073546976801874298166903427690031858186486050853753882811946569946433649006084095] ""  BCM

BO_ 2550011429 DIA_SHL_li1_Resp: 8 BCM
 SG_ DIA_SHL_li1_Resp_Data : 0|64@1+ (1.0,0.0) [0.0|18446744073709551615] ""  Gateway_Max

BO_ 2621576741 DIA_SHL_li1_Resp_FD: 64 BCM
 SG_ DIA_SHL_li1_Resp_FD_Data : 0|512@1+ (1.0,0.0) [0.0|13407807929942597099574024998205846127479365820592393377723561443721764030073546976801874298166903427690031858186486050853753882811946569946433649006084095] ""  Gateway_Max

BO_ 2549880590 DIA_SHL_li2_Req: 8 Gateway_Max
 SG_ DIA_SHL_li2_Req_Data : 0|64@1+ (1.0,0.0) [0.0|18446744073709551615] ""  BCM

BO_ 2621445902 DIA_SHL_li2_Req_FD: 64 Gateway_Max
 SG_ DIA_SHL_li2_Req_FD_Data : 0|512@1+ (1.0,0.0) [0.0|13407807929942597099574024998205846127479365820592393377723561443721764030073546976801874298166903427690031858186486050853753882811946569946433649006084095] ""  BCM

BO_ 2550011662 DIA_SHL_li2_Resp: 8 BCM
 SG_ DIA_SHL_li2_Resp_Data : 0|64@1+ (1.0,0.0) [0.0|18446744073709551615] ""  Gateway_Max

BO_ 2621576974 DIA_SHL_li2_Resp_FD: 64 BCM
 SG_ DIA_SHL_li2_Resp_FD_Data : 0|512@1+ (1.0,0.0) [0.0|13407807929942597099574024998205846127479365820592393377723561443721764030073546976801874298166903427690031858186486050853753882811946569946433649006084095] ""  Gateway_Max

BO_ 2549880591 DIA_SHL_re1_Req: 8 Gateway_Max
 SG_ DIA_SHL_re1_Req_Data : 0|64@1+ (1.0,0.0) [0.0|18446744073709551615] ""  BCM

BO_ 2621445903 DIA_SHL_re1_Req_FD: 64 Gateway_Max
 SG_ DIA_SHL_re1_Req_FD_Data : 0|512@1+ (1.0,0.0) [0.0|13407807929942597099574024998205846127479365820592393377723561443721764030073546976801874298166903427690031858186486050853753882811946569946433649006084095] ""  BCM

BO_ 2550011663 DIA_SHL_re1_Resp: 8 BCM
 SG_ DIA_SHL_re1_Resp_Data : 0|64@1+ (1.0,0.0) [0.0|18446744073709551615] ""  Gateway_Max

BO_ 2621576975 DIA_SHL_re1_Resp_FD: 64 BCM
 SG_ DIA_SHL_re1_Resp_FD_Data : 0|512@1+ (1.0,0.0) [0.0|13407807929942597099574024998205846127479365820592393377723561443721764030073546976801874298166903427690031858186486050853753882811946569946433649006084095] ""  Gateway_Max

BO_ 2549880592 DIA_SHL_re2_Req: 8 Gateway_Max
 SG_ DIA_SHL_re2_Req_Data : 0|64@1+ (1.0,0.0) [0.0|18446744073709551615] ""  BCM

BO_ 2621445904 DIA_SHL_re2_Req_FD: 64 Gateway_Max
 SG_ DIA_SHL_re2_Req_FD_Data : 0|512@1+ (1.0,0.0) [0.0|13407807929942597099574024998205846127479365820592393377723561443721764030073546976801874298166903427690031858186486050853753882811946569946433649006084095] ""  BCM

BO_ 2550011664 DIA_SHL_re2_Resp: 8 BCM
 SG_ DIA_SHL_re2_Resp_Data : 0|64@1+ (1.0,0.0) [0.0|18446744073709551615] ""  Gateway_Max

BO_ 2621576976 DIA_SHL_re2_Resp_FD: 64 BCM
 SG_ DIA_SHL_re2_Resp_FD_Data : 0|512@1+ (1.0,0.0) [0.0|13407807929942597099574024998205846127479365820592393377723561443721764030073546976801874298166903427690031858186486050853753882811946569946433649006084095] ""  Gateway_Max

BO_ 2549880734 DIA_VIP_HBFS_Req: 8 Gateway_Max
 SG_ DIA_VIP_HBFS_Req_Data : 0|64@1+ (1.0,0.0) [0.0|18446744073709551615] ""  BCM

BO_ 2621446046 DIA_VIP_HBFS_Req_FD: 64 Gateway_Max
 SG_ DIA_VIP_HBFS_Req_FD_Data : 0|512@1+ (1.0,0.0) [0.0|13407807929942597099574024998205846127479365820592393377723561443721764030073546976801874298166903427690031858186486050853753882811946569946433649006084095] ""  BCM

BO_ 2550011806 DIA_VIP_HBFS_Resp: 8 BCM
 SG_ DIA_VIP_HBFS_Resp_Data : 0|64@1+ (1.0,0.0) [0.0|18446744073709551615] ""  Gateway_Max

BO_ 2621577118 DIA_VIP_HBFS_Resp_FD: 64 BCM
 SG_ DIA_VIP_HBFS_Resp_FD_Data : 0|512@1+ (1.0,0.0) [0.0|13407807929942597099574024998205846127479365820592393377723561443721764030073546976801874298166903427690031858186486050853753882811946569946433649006084095] ""  Gateway_Max

BO_ 2549880720 DIA_VIP_HFS_Req: 8 Gateway_Max
 SG_ DIA_VIP_HFS_Req_Data : 0|64@1+ (1.0,0.0) [0.0|18446744073709551615] ""  BCM

BO_ 2621446032 DIA_VIP_HFS_Req_FD: 64 Gateway_Max
 SG_ DIA_VIP_HFS_Req_FD_Data : 0|512@1+ (1.0,0.0) [0.0|13407807929942597099574024998205846127479365820592393377723561443721764030073546976801874298166903427690031858186486050853753882811946569946433649006084095] ""  BCM

BO_ 2550011792 DIA_VIP_HFS_Resp: 8 BCM
 SG_ DIA_VIP_HFS_Resp_Data : 0|64@1+ (1.0,0.0) [0.0|18446744073709551615] ""  Gateway_Max

CM_ BO_ 1635 "DLC=8 ab D4 gültig";
CM_ BO_ 870 "Nur die Kombination des statischen und toggelnden Signals ergibt den Blinktakt für die Hell & Dunkelphase";
CM_ BO_ 902 "ab MQB 7.2.1";
CM_ BO_ 2463978646 "ab MQB ohne CHK und mit geänderter Sendeart";
CM_ BO_ 2549891585 "CAN Flashen";
CM_ BO_ 2549891584 "CAN Flashen";
CM_ BO_ 2549891587 "CAN Flashen";
CM_ BO_ 2549891586 "CAN Flashen";
CM_ BO_ 2549880322 "LIN Flashen Regen-Licht-Feuchte-Sensor (DK2F)";
CM_ BO_ 2621445634 "LIN Flashen Regen-Licht-Feuchte-Sensor (DK2F)";
CM_ BO_ 2550011394 "LIN Flashen Regen-Licht-Feuchte-Sensor (DK2F)";
CM_ BO_ 2621576706 "LIN Flashen Regen-Licht-Feuchte-Sensor (DK2F)";

CM_ SG_ 1427 KY_Anf_Reichwbegr "1 = Anforderung der LF-Reichweitenbegrenzung für FFB-Komfortfunktionen";
CM_ SG_ 1427 KY_Anf_Reichwbegr_Gesamt "1 = Anforderung der LF-Reichweitenbegrenzung für FFB-Komfortfunktionen gesamtes Fahrezeug";
CM_ SG_ 1427 KY_Autofunktion_Aktiv "Empfang einer Autofunktion ID Geber Botschaft (Passiv Lock/Unlock, Gestikgesteuerte Heckklappe)";
CM_ SG_ 1427 KY_Bedienstelle "Werte entsprechen der ZV Bedienhistorie (Siehe TM ZV Bedienhistorie)";
CM_ SG_ 1427 KY_Entriegeln "letzte ZV Bedienrichtung (1 = Entriegeln) entsprechen der ZV Bedienhistorie (Siehe TM ZV Bedienhistorie)";
CM_ SG_ 1427 KY_FFB_in_LF_Reichw "1 = LF-Reichweite-Bit ist im FFB Komfort-Protokoll gesetzt.";
CM_ SG_ 1427 KY_HD_Verriegelung_Autorisiert "Autorisierung der Schließanforderung über Verriegelungsinnentaster";
CM_ SG_ 1427 KY_IDGeber_1_Bat "ID Geber 1 meldet schwache Batterie (0= Batterie I.O., 1 =Entry Exit gesperrt, 2 = Go gesperrt, 3 = tbd.)";
CM_ SG_ 1427 KY_IDGeber_1_Status "ID Geber 1 Status Authentifizierung (0 = keine Antwort, 1 = authentifiziert, 2 = UHF Antwort, aber nicht authentifiziert, 3 - 7 tbd.)";
CM_ SG_ 1427 KY_IDGeber_2_Bat "ID Geber 2 meldet schwache Batterie (0= Batterie I.O., 1 =Entry Exit gesperrt, 2 = Go gesperrt, 3 = tbd.)";
CM_ SG_ 1427 KY_IDGeber_2_Status "ID Geber 2 Status Authentifizierung (0 = keine Antwort, 1 = authentifiziert, 2 = UHF Antwort, aber nicht authentifiziert, 3 - 7 tbd.)";
CM_ SG_ 1427 KY_IDGeber_3_Bat "ID Geber 3 meldet schwache Batterie (0= Batterie I.O., 1 =Entry Exit gesperrt, 2 = Go gesperrt, 3 = tbd.)";
CM_ SG_ 1427 KY_IDGeber_3_Status "ID Geber 3 Status Authentifizierung (0 = keine Antwort, 1 = authentifiziert, 2 = UHF Antwort, aber nicht authentifiziert, 3 - 7 tbd.)";
CM_ SG_ 1427 KY_IDGeber_4_Bat "ID Geber 4 meldet schwache Batterie (0= Batterie I.O., 1 =Entry Exit gesperrt, 2 = Go gesperrt, 3 = tbd.)";
CM_ SG_ 1427 KY_IDGeber_4_Status "ID Geber 4 Status Authentifizierung (0 = keine Antwort, 1 = authentifiziert, 2 = UHF Antwort, aber nicht authentifiziert, 3 - 7 tbd.)";
CM_ SG_ 1427 KY_KessyEntryExit_Akt "Empfang einer Kessy EntryExit Botschaft (mit Authentifizierung)";
CM_ SG_ 1427 KY_Nr_IDGeber_Autofkt "Nr des ID-Gebers der den RSSI-Wert gesendet hat (Passiv Lock/Unlock, Gestikgesteuerte Heckklappe)";
CM_ SG_ 1427 KY_RSSI_Wert "RSSI Wert bei Autofunktion (Passiv Lock/Unlock, Gestikgesteuerte Heckklappe)";
CM_ SG_ 1427 KY_Schluesselnr "Zusätzliche Information zur letzen ZV-Aktion; die Bedeutung ist abhängig von der letzten Bedienstelle/Trigger (KY_Bedienstelle) und geben entweder Schlüsselnummer oder Crashstärke entsprechend der ZV Bedienhistorie wieder (siehe TM ZV Bedienhistorie)";
CM_ SG_ 1427 KY_Softtouch "1 = Softtouch ist betätigt (unbewertete Info vom HD-Taster)";
CM_ SG_ 1427 KY_Verriegeln "letzte ZV Bedienrichtung (1 =Verriegeln) entsprechen der ZV Bedienhistorie (Siehe TM ZV Bedienhistorie)";
CM_ SG_ 1427 KY_ZV_CMD "letzte ZV-Aktion; die Bedeutung der Werte ist abhängig von der letzten ZV-Bedienrichtung (KY_Verriegeln, KY_Entriegeln) und geben den Zielzustand der Schlösser entsprechend der ZV Bedienhistorie wieder (siehe TM ZV Bedienhistorie)";
CM_ SG_ 1427 ZV_Anf_Abschaltung_Zuendung "Signalisierung ZV-Verrieglungswunsch über Türschloss, Kessy oder FFB, wenn Fahrzeug durch aktiver Kl_15 nicht verriegelt wird.";

CM_ SG_ 1432 BCM_BFS_Massage_Taster "Ansteuerungs-Signalisierung der Pneumatik-Funktionen";
CM_ SG_ 1432 BCM_BFS_Multif_Taster "Ansteuerungs-Signalisierung der Pneumatik-Funktionen";
CM_ SG_ 1432 BCM_BFS_Pneumatik_Verstellung "Ansteuerungs-Signalisierung der Pneumatik-Funktionen";
CM_ SG_ 1432 BCM_BFS_Programmwippe "Ansteuerungs-Signalisierung der Pneumatik-Funktionen";
CM_ SG_ 1432 BCM_FS_Massage_Taster "Ansteuerungs-Signalisierung der Pneumatik-Funktionen";
CM_ SG_ 1432 BCM_FS_Multif_Taster "Ansteuerungs-Signalisierung der Pneumatik-Funktionen";
CM_ SG_ 1432 BCM_FS_Pneumatik_Verstellung "Ansteuerungs-Signalisierung der Pneumatik-Funktionen";
CM_ SG_ 1432 BCM_FS_Programmwippe "Ansteuerungs-Signalisierung der Pneumatik-Funktionen";
CM_ SG_ 1432 LIM_bCall_Taster "Statusinformation des Service Call Tasters im Dachmodul";
CM_ SG_ 1432 LIM_iCall_Taster "Betätigungsstatus des Info Call Tasters im Dachmodul";
CM_ SG_ 1432 LIM_S_Rollo_hi "Schalterfeld LIM für Sonnenrolle Schiebedach hinten";
CM_ SG_ 1432 LIM_S_Rollo_vo "Schalterfeld LIM fuer Sonnenrollo Schiebedach vorne bzw. schaltbares Glasdach";
CM_ SG_ 1432 LIM_S_SAD_hi "Schalterfeld LIM für SAD hinten";
CM_ SG_ 1432 LIM_S_SAD_Vo "Schalterfeld LIM für SAD vorne";
CM_ SG_ 1432 LINDa_Touch_Event "Touch_Events für Informationen einer Funktionsauslösung auf dem LINDa, welches dann für bspw. ein akustisches Signal zentral umgesetzt werden können.";

CM_ SG_ 2527679781 LINDa_HL_SR3_Touch_Event "Touch_Events für Informationen einer Funktionsauslösung auf dem LINDa (hinten links SR3) , welches dann für bspw. ein akustisches Signal zentral umgesetzt werden können.";
CM_ SG_ 2527679781 LINDa_HL_Touch_Event "Touch_Events für Informationen einer Funktionsauslösung auf dem LINDa, welches dann für bspw. ein akustisches Signal zentral umgesetzt werden können.";
CM_ SG_ 2527679781 LINDa_HR_SR3_Touch_Event "Touch_Events für Informationen einer Funktionsauslösung auf dem LINDa (hinten rechts SR3), welches dann für bspw. ein akustisches Signal zentral umgesetzt werden können.";
CM_ SG_ 2527679781 LINDa_HR_Touch_Event "Touch_Events für Informationen einer Funktionsauslösung auf dem LINDa, welches dann für bspw. ein akustisches Signal zentral umgesetzt werden können.";

CM_ SG_ 2463978855 DML_ConstructionZone_Enabled "Aktivierung/Deaktivierung der Funktion 'Bau/Engstellenassistent' im zDML";
CM_ SG_ 2463978855 DML_CrossingAssist_Enabled "Aktivierung/Deaktivierung der Funktion Kreuzungsassistent im zDML";
CM_ SG_ 2463978855 DML_GhostDriverWarn_Enabled "Aktivierung/Deaktivierung der Funktion 'Geister/Falschfahrerwarnung' im zDML";
CM_ SG_ 2463978855 DML_GlarefreeHB_Enabled "Aktivierung/Deaktivierung der Funktion 'Blendfreies Fernlicht' im zDML";
CM_ SG_ 2463978855 DML_HazardWarning_Enabled "Aktivierung/Deaktivierung der Funktion 'Gefahrenwarnung' im zDML";
CM_ SG_ 2463978855 DML_HMI_FCN_CROSSINGLI_REQUEST "Anforderung der Funktion Kreuzungsassistent vom HMI an zDML";
CM_ SG_ 2463978855 DML_HMI_FCN_HAZARDWARN_REQUEST "Anforderung der Funktion Gefahrenhinweis vom HMI an zDML";
CM_ SG_ 2463978855 DML_HMI_FCN_LANELIGHT_REQUEST "Anforderung der Funktion Spurlicht vom HMI";
CM_ SG_ 2463978855 DML_HMI_FCN_LANLEAVELI_REQUEST "Anforderung der Funktion Spurverlassenswarnung vom HMI an zDML";
CM_ SG_ 2463978855 DML_HMI_FCN_MALI_REQUEST "Anforderung der Funktion Markierungslicht vom HMI an zDML";
CM_ SG_ 2463978855 DML_HMI_FCN_ORLI_REQUEST "Anforderung der Funktion Orientierungslicht vom HMI an zDML";
CM_ SG_ 2463978855 DML_HMI_FCN_RESALLEYHI_REQUEST "Anforderung der Funktion Rettungsgassenhinweis vom HMI an zDML";
CM_ SG_ 2463978855 DML_HMI_FCN_ROADWORKLI_REQUEST "Anforderung der Funktion Bau/Engstellenlicht vom HMI an zDML";
CM_ SG_ 2463978855 DML_HMI_FCN_SAFETYZONE_REQUEST "Anforderung der Funktion Sicherheitszone vom HMI an zDML";
CM_ SG_ 2463978855 DML_HMI_FCN_TURNLIGHPR_REQUEST "Anforderung der Funktion Blinkerprojektion vom HMI an zDML";
CM_ SG_ 2463978855 DML_Indicator_Enabled "Aktivierung/Deaktivierung der Funktion 'Blinkerprojektion' im zDML";
CM_ SG_ 2463978855 DML_IntelligentHB_Enabled "Aktivierung/Deaktivierung der Funktion 'IntelligentHighBeam' im zDML";
CM_ SG_ 2463978855 DML_LaneDepartureWarn_Enabled "Aktivierung/Deaktivierung der Funktion 'Spurverlassenswarnung' im zDML";
CM_ SG_ 2463978855 DML_LaneLight_Enabled "Aktivierung/Deaktivierung der Funktion Spurlicht vom HMI";
CM_ SG_ 2463978855 DML_MarkingLight_Enabled "Aktivierung/Deaktivierung der Funktion 'Markierungslicht' im zDML";
CM_ SG_ 2463978855 DML_OrientationLight_Enabled "Aktivierung/Deaktivierung der Funktion 'Orientierungslicht' im zDML";
CM_ SG_ 2463978855 DML_RescueLaneNotice_Enabled "Aktivierung/Deaktivierung der Funktion 'Rettungsgassenhinweis' im zDML";
CM_ SG_ 2463978855 DML_SafetyZone_Enabled "Aktivierung/Deaktivierung der Funktion 'Sicherheitszone ' im zDML";
CM_ SG_ 2463978855 DML_SaftyDistance_Enabled "Aktivierung/Deaktivierung der Funktion 'Abstandswarnung' im zDML";
CM_ SG_ 2463978855 DML_SideAssist_Enabled "Aktivierung/Deaktivierung der Funktion 'SideAssist' im zDML";

CM_ SG_ 1635 BEM_Anf_KL15_schalten "Abschaltempfehlung bzw. Verhinderung der automatischen Abschaltung Kl15 durch das BCM";
CM_ SG_ 1635 BEM_Batt_Ab "Batterieverbindungskontrolle:
0x0: Batterie am Bordnetz
0x1: Batterie ab erkannt";
CM_ SG_ 1635 BEM_Batteriediagnose "Anzeige von Textwarnungen";
CM_ SG_ 1635 BEM_DFM "Generatorauslastungsgrad, vom Generator über LIN an das Gateway gesandt. Das Motorsteuergerät regelt auf dieses Signal die PTC, das Energiemanagement im BSG/BCM kalkuliert die Bordnetzauslastung";
CM_ SG_ 1635 BEM_EMLIN_ungueltig "Energie-Lin - Signale sind ungültig vom Slave Batteriedatenmodul oder Generator
0 = Signale gültig
1 = Signale ungültig";
CM_ SG_ 1635 BEM_Generatordiagnose "Ansteuerung Generatorwarnleuchte im Kombi
";
CM_ SG_ 1635 BEM_HL_Kontingentierung "Leistungskontingente für Heizsysteme";
CM_ SG_ 1635 BEM_HL_Regelung_Status "Status Regelung Heizleistung
";
CM_ SG_ 1635 BEM_Ladezustand "Ladezustand der Niedervoltbatterie
";
CM_ SG_ 1635 BEM_MMI_Vorwarnung "Anzeige Vorwarnung MMI-Abschaltung (Initialisierungswert aus EEprom)
";
CM_ SG_ 1635 BEM_Red_Innengeblaese "Reduzierung Innengebläse
";
CM_ SG_ 1635 BEM_REK_aktiv "Rekuperationsfreigabe vom Energiemanagement
0x0 = keine Rekuperationsfreigabe
0x1 = Rekuperationsfreigabe";
CM_ SG_ 1635 BEM_STH_Einschaltverbot "Einschränkung Standheizung/-lüftung durch BEM: Setzt der BEM das Bit, dann darf die Standheizung nicht mehr einschalten
(Die Standheizung muss aber nicht abschalten, sondern darf weiterbrennen)
(Initialisierungswert aus EEprom)
";
CM_ SG_ 1635 BEM_STH_Zielzeit "Maximal mögliche Zeit für den Standheizungsbetrieb, um die Startfähigkeit nicht zu gefährden";
CM_ SG_ 1635 BEM_UBDM "Batteriespannung, gemessen vom Batteriedatenmodul";
CM_ SG_ 1635 BEM_UGenSoll "Sollspannungsvorgabe an den Generator, beinhaltet temperaturoptimierte Batterieladung und Rekuperation";
CM_ SG_ 1635 MIB_Stromsparmodus "Signal beschreibt die Aktivierung für den Stromsparmodus beim MIB.
Bei AUS (= 0) gibt es keine weitere Anforderung an die MIB-Komponenten.
Bei EIN (= 1) werden alle MIB Komponenten in einen Stromsparmodus versetzt.";
CM_ SG_ 1635 NVEM_Abschaltstufe "Abschaltstufe aus dem Ruheenergiemanagement
Maßnahmen des Empfängers werden im QLAH Ruhestrommanagement definiert";
CM_ SG_ 1635 NVEM_Anf_SD_schalten "Anforderung Nachlauf für den Steckdosenbetrieb
Initialisierungswert aus EEprom";
CM_ SG_ 1635 NVEM_Batterie_Service "Anforderung einer Batterie-Service - Anzeige / Anforderung an die Werkstatt über MOD";
CM_ SG_ 1635 NVEM_Freigabe_OnlineUpdate "Freigabe für Online-Update durch Energiemanagement";
CM_ SG_ 1635 NVEM_Freigabe_ORU4 "Bestätigung oder Ablehnung eines konkreten, angefragten Online Updates durch das Energiemanagements";
CM_ SG_ 1635 NVEM_Freigabe_ZusBatt_Laden "NVEM gibt die Freigabe zum Schließen des Laderelais im Ruhebetrieb (z.B. bei Verwendung eines Ladegerätes)";
CM_ SG_ 1635 NVEM_Verbraucherabsch_Anz "Information über eine Verbraucherbschaltung durch das Energiemanagement";

CM_ SG_ 1163 BEM_06_BZ "4bit Botschaftszähler, wird mit jeder Sendebotschaft inkrementiert";
CM_ SG_ 1163 BEM_06_CRC "Für MLB:
Berechnung siehe Lastenheft 'Kommunikationsabsicherung für FlexRay und CAN'
Ab MQB und MLBevo:
Berechnung siehe Lastenheft 'End-to-End Kommunikationsabsicherung'

Endwerte siehe Begleitdokument 'S-PDU Kennungsfolgen'";
CM_ SG_ 1163 HLR_PTC_linear_Freigabe "Freigabe des EEM für den linearen PTC-Zuheizer";
CM_ SG_ 1163 NVEM2_Status_FuSiFahrt "Status sicherheitsrelevante Diagnosen NVEM";
CM_ SG_ 1163 NVEM2_Typ_EnergieNetz "Identifizierte NV-Energiearchitektur";
CM_ SG_ 1163 NVEM_Betriebsart "Betriebsart des Niedervolt - Energiemanagements";
CM_ SG_ 1163 NVEM_Bordnetzdiagnose "Wird vom NVEM im NV-Netz ein Bordnetz-Fehler erkannt, so soll dies zu einer mehrstufigen Anzeige führen.";
CM_ SG_ 1163 NVEM_Energie_Klima_Vorgabe "NVEM-Energievorgabe für Klima-Vorkonditionierung";
CM_ SG_ 1163 NVEM_Energienetz_Status "NVEM kommuniziert abgesichert den Zustand des Energienetzes.";
CM_ SG_ 1163 NVEM_Ladezustand "Ladezustand des NV-Hauptspeichers.";
CM_ SG_ 1163 NVEM_Last_Anf "Das NVEM fordert für die Batteriediagnose einen Lastimpuls vom Fahrzeug an, der durch kontrollierte Verbraucherzuschaltungen (z. B. Aktivierung Heckscheibenheizung) generiert wird";
CM_ SG_ 1163 NVEM_PTC_Sollstufe "Vorgabe des BEM an das BCM zur Aktivierung der geforderten PTC - Stufe.
Das MSG kopiert dies auf das Signal MO_PTC_Status";
CM_ SG_ 1163 NVEM_Red_KomfortVerbrauch "Master - SubMaster Kommunikation";
CM_ SG_ 1163 NVEM_STH_ZielzeitLang "Energetisch erlaubte Betriebszeit im Zielzeitkonzept für Standheizungen mit 2 Stunden Laufzeit";
CM_ SG_ 1163 NVEM_Vorgabe_Leistungsstufe "Ermittelte Leistungsstufe der Energiequelle";

CM_ SG_ 2463978850 BEM_07_BZ "4bit Botschaftszähler, wird mit jeder Sendebotschaft inkrementiert";
CM_ SG_ 2463978850 BEM_07_CRC "Für MLB:
Berechnung siehe Lastenheft 'Kommunikationsabsicherung für FlexRay und CAN'
Ab MQB und MLBevo:
Berechnung siehe Lastenheft 'End-to-End Kommunikationsabsicherung'

Endwerte siehe Begleitdokument 'S-PDU Kennungsfolgen'";
CM_ SG_ 2463978850 NVEM2_VerbrZustandsAnf "Dieses Signal soll bei FuSi-relevanten Energienotsituationen die Reaktion bei den Nichtdynamischen Verbrauchern auslösen.";
CM_ SG_ 2463978850 NVEM3_Absch_SCR "Abschaltung der SCR-Heizung durch das NVEM bei energetisch kritischen Zuständen.";
CM_ SG_ 2463978850 NVEM_Batt_Temp_Hinweis "Anforderung Kühlungsunterstützung der NV - Batterie";
CM_ SG_ 2463978850 NVEM_Bordnetz_Information "Informationsanzeigen zum 12V - Bordnetz";
CM_ SG_ 2463978850 NVEM_NVStuetzungAnf "Aktivierung / Deaktivierung Primärenergieversorger";
CM_ SG_ 2463978850 NVEM_Verbraucher_Information "Mit diesem Signal löst Das NVM eine Anzeige bzgl. einer bevorstehenden oder erfolgten Verbraucherabschaltung aus";

CM_ SG_ 870 Blinken_li_Fzg_Takt "Fzg-Takt Blinker links

";
CM_ SG_ 870 Blinken_li_Kombi_Takt "Kombi-Takt Blinker links

";
CM_ SG_ 870 Blinken_re_Fzg_Takt "Fzg-Takt Blinker rechts

";
CM_ SG_ 870 Blinken_re_Kombi_Takt "Kombi-Takt Blinker rechts

";
CM_ SG_ 870 Blinkmodi_02_BZ "4bit Botschaftszähler, wird mit jeder Sendebotschaft inkrementiert";
CM_ SG_ 870 Blinkmodi_02_CRC "Für MLB:
Berechnung siehe Lastenheft 'Kommunikationsabsicherung für FlexRay und CAN'
Ab MQB und MLBevo:
Berechnung siehe Lastenheft 'End-to-End Kommunikationsabsicherung'

Endwerte siehe Begleitdokument 'S-PDU Kennungsfolgen'";
CM_ SG_ 870 BM_Autobahn "Status Autobahnblinken
";
CM_ SG_ 870 BM_Crash "Status Crashblinken
";
CM_ SG_ 870 BM_DWA_Alarm "Status DWA-Alarmblinken
";
CM_ SG_ 870 BM_DWA_ein "Status Quittierungsblinken DWA";
CM_ SG_ 870 BM_GDO "Blinken bei UGDO anlernen

";
CM_ SG_ 870 BM_HD_Oeffnung_angelernt "HD_Rueckmeld_prog eine Blinkerquittierung wird beim BCM2 angefordert.
Wenn die Geschwindigkeit kleiner einer vorgegebenen Schwelle (default 2km/h) ist wird das Signal BM_HD_Öffnung_angelernt versendet und die Blinkerquittierung ausgelöst";
CM_ SG_ 870 BM_links "Richtungsblinken links

";
CM_ SG_ 870 BM_NBA_n_codiert_n_aktiv "Notbremsanzeige nicht codiert/nicht aktiv (Fehler)";
CM_ SG_ 870 BM_NBA_Status "Notbremsanzeige Status nicht aktiv / BRL Dunkelphase / BRL Hellphase";
CM_ SG_ 870 BM_Not_Bremsung "Das Signal BM_Not_Bremsung  zeigt an,  ob ein Warnblinken aufgrund einer vom Bremssystem signalisierten Notbremsung aktiv ist.";
CM_ SG_ 870 BM_Panik "Panikblinken
";
CM_ SG_ 870 BM_PiloPa "Quittierungsblinken bei pilotierten Parkvorgängen";
CM_ SG_ 870 BM_Recas "Blinkermodus RECAS  (RearEndCollisionAlertSignal)";
CM_ SG_ 870 BM_rechts "Richtungsblinken rechts

";
CM_ SG_ 870 BM_Rollenmodus_Blinken "Das Signal wird statisch gesetzt, wenn die Blinkerart Rollenmodus_Blinken aktiv ist.";
CM_ SG_ 870 BM_Taxi_Notalarm "Blinken bei Taxi-Not-Alarm

";
CM_ SG_ 870 BM_Telematik "Telematikblinken
";
CM_ SG_ 870 BM_Telematik_Abbruchgrund "Gibt bei erwaretem aber ausbleibendem Flankenanstieg der BM_Telematik an wieso die Ausführung verhindert wurde. Bei Flankenabfall der BM_Telematik wird angegeben wieso die Ausführung beendet wurde.

Bei nicht bereitem Sender soll 'init' gesendet werden,";
CM_ SG_ 870 BM_Warnblinken "Warnblinken

";
CM_ SG_ 870 BM_WBA_Warnblinken "Rückkanal des durch WBA (Warnen, Bremsen, Ausweichen) angeforderten Warnblinken";
CM_ SG_ 870 BM_WBT_Beleuchtung "Aktivierung Warnblinktasterfunktionsbeleuchtung
Warnblinktasterfunktionsbeleuchtung soll aktiviert werden (statisch auf 1)";
CM_ SG_ 870 BM_Wischblinken "Blinkermodus Wisch_Blinken";
CM_ SG_ 870 BM_ZV_auf "Blinken bei ZV auf

";
CM_ SG_ 870 BM_ZV_zu "Blinken bei ZV zu

";
CM_ SG_ 870 SAL_RHP_Blinken_Status "SAL Rückmeldung Rush Hour Pilot Blinker-Status an Funktion RHP";
CM_ SG_ 870 SAL_RHP_Warnblinken "Rückkanal des durch RHP angeforderten Warnblinken";
CM_ SG_ 870 SAL_TA_Blinken_Status "SAL RückmeldungTravelAssist Blinker-Status an Funktion TA (MFK)";

CM_ SG_ 1482 BMS_07_CRC "Für MLB:
'Berechnung siehe Lastenheft 'Kommunikationsabsicherung für FlexRay und CAN''

Ab MQB und MLBevo:
'Berechnung siehe Lastenheft 'End-to-End Kommunikationsabsicherung''

Endwerte siehe Begleitdokument 'S-PDU Kennungsfolgen'";
CM_ SG_ 1482 BMS_Ausgleichsladung_Anf "BMS wünscht eine Ausgleichsladung
Flag derzeit ungenutzt, da BalancingModus im Detail noch nicht geklärt.";
CM_ SG_ 1482 BMS_Balancing_Aktiv "Signal zeigt an, ob mindestens eine Zelle der HV Batterie balanciert wird";
CM_ SG_ 1482 BMS_Batteriediagnose "Anzeige von Textwarnungen";
CM_ SG_ 1482 BMS_Energieinhalt "aktuell nutzbarer Energieinhalt der HV-Batterie
(bezogen auf ein definiertes mittleres Belastungsprofil)";
CM_ SG_ 1482 BMS_Gesamtst_Spgfreiheit "0 = Funktion nicht aktiviert
1 = HV-System spannungsfrei (U_Zwkr von BMS, LE und Ladegerät < 20V, DCLadestecker nicht gesteckt und Service Disconnect entriegelt)
2 = HV-System nicht spannungsfrei (U_Zwkr von BMS, LE und Ladegerät >= 20V, Ladestecker ges";
CM_ SG_ 1482 BMS_KundenWarnung "Kundenwarnung und Ersatzreaktionen aufgrund von Batteriebrandgefahr";
CM_ SG_ 1482 BMS_Ladevorgang_aktiv "Signalisiert aktiven Ladevorgang, Ladegerät und DC/DC aktiv.
Signal bleibt nach Kl.15 ein aktiv, bis ESP_Stillstandsflag gelöscht.

Abhängigkeit zu BMS_Energieinhalt";
CM_ SG_ 1482 BMS_MaxEnergieinhalt "maximaler nutzbarer Energieinhalt der HV-Batterie (bezogen auf Last KBI_RWDS_Lastprofil bei SOC=100%)
Abhängig von KBI_RWDS_Lastprofil";
CM_ SG_ 1482 BMS_RIso_Ext "Minimum des Isolationswiderstands zwischen Batteriegehäuse und HV+ bzw. Batteriegehäuse und HV- bei geschlossenen Schützen (externe Iso Messung)";

CM_ SG_ 2331596015 BSIS_Anzeigen_links "BSIS- Texte und -Akustik zur Anzeige und Tonausgabe im Kombiinstrument";
CM_ SG_ 2331596015 BSIS_LED_Ausgabemodus_links "Ansteuerung der SWA-LED Fahrtrichtung links für die Funktion BSIS (Priorisierung BSIS/SWA)";
CM_ SG_ 2331596015 BSIS_LED_Hell_links "Helligkeitswert SWA-LED Fahrtrichtung links für die Funktion BSIS (Priorisierung BSIS/SWA)";

CM_ SG_ 2331596016 BSIS_Anzeigen_rechts "BSIS- Texte und -Akustik zur Anzeige und Tonausgabe im Kombiinstrument";
CM_ SG_ 2331596016 BSIS_LED_Ausgabemodus_rechts "Ansteuerung der SWA-LED Fahrtrichtung rechts für die Funktion BSIS (Priorisierung BSIS/SWA)";
CM_ SG_ 2331596016 BSIS_LED_Hell_rechts "Helligkeitswert SWA-LED Fahrtrichtung rechts für die Funktion BSIS (Priorisierung BSIS/SWA)";

CM_ SG_ 2463978792 CentralLocking_01_BZ "4bit Botschaftszähler, wird mit jeder Sendebotschaft inkrementiert";
CM_ SG_ 2463978792 DWA_aktiv "Status DWA  aktiv";
CM_ SG_ 2463978792 IRUE_Taster_Fkts_LED "Anforderung Funktions-LED IRUE-Taster (LED wird vom TSG angesteuert)
MQB: Bei Verbau eines einzelnen Taster zur Deaktivierung von IRUE und NGS wird dieses Signal zur Ansteuerung der Funktions-LED gesendet.";
CM_ SG_ 2463978792 SOK_CentralLocking_01_Signatur "Signatur im Rahmen des SOK Authentic-Broadcast-Protokolls.

Geschützte Funktion: ZV
Geschützte Botschaft: CentraLocking_01";
CM_ SG_ 2463978792 ZV_auto_Ansteuerung "Kennung für die automatische Ansteuerung der Zentralverriegelung (Autolock/Autounlock)";
CM_ SG_ 2463978792 ZV_Bedienstelle_auf "ZV Schliessstellen in Richtung auf";
CM_ SG_ 2463978792 ZV_Bedienstelle_zu "ZV Schliessstellen in Richtung zu";
CM_ SG_ 2463978792 ZV_BT_entriegeln "Beifahrertür entriegeln (Anforderung ZV)";
CM_ SG_ 2463978792 ZV_BT_verriegeln "Verriegelungsanforderung ZV für BT";
CM_ SG_ 2463978792 ZV_Crashfall_erkannt "ZV_Crashfall_erkannt";
CM_ SG_ 2463978792 ZV_Frontschloss_Vorraste "Sperrklinke oder Vorraste Frontchloss
Das Signal muss über eine E2E-Absicherung verfügen.";
CM_ SG_ 2463978792 ZV_FT_entriegeln "Entriegelungsanforderung ZV für FT";
CM_ SG_ 2463978792 ZV_FT_verriegeln "Verriegelungsanforderung ZV für FT";
CM_ SG_ 2463978792 ZV_gesafet_extern_ist_02 "Istzustand: Fahrzeug aussen gesafet";
CM_ SG_ 2463978792 ZV_gesafet_extern_soll_02 "Sollzustand: Fahrzeug gesafet extern";
CM_ SG_ 2463978792 ZV_HBFS_entriegeln "Entriegelungsanforderung ZV für HBFS
";
CM_ SG_ 2463978792 ZV_HBFS_verriegeln "Verriegelungsanforderung ZV für HBFS
";
CM_ SG_ 2463978792 ZV_HFS_entriegeln "Entriegelungsanforderung ZV für HFS
";
CM_ SG_ 2463978792 ZV_HFS_verriegeln "Verriegelungsanforderung ZV für HFS
";
CM_ SG_ 2463978792 ZV_LED_Steuerung "Ansteuerung der LED's in den Tueren; BAF gilt nicht für dieses Bit";
CM_ SG_ 2463978792 ZV_LED_Uebernahme "Uebernahme der LED Steuerung durch das TSG FT";
CM_ SG_ 2463978792 ZV_Schluessel_Zugang "aktuelle Funkschlüsselnummer";
CM_ SG_ 2463978792 ZV_Signatur "Signatur der ZV";
CM_ SG_ 2463978792 ZV_Spg_Anklappen "Anforderung über ZV: Spiegel sind anzuklappen";
CM_ SG_ 2463978792 ZV_Status_eTAG_ist "Istzustand: Türaussengriff eingefahren oder ausgefahren (Zielzustand)";
CM_ SG_ 2463978792 ZV_Status_eTAG_soll "Sollzustand: Türaussengriff eingefahren oder ausgefahren (Zielzustand)";
CM_ SG_ 2463978792 ZV_TAG_BT_verfahren "Türaussengriff BT Trigger zum Aus- und Einfahren";
CM_ SG_ 2463978792 ZV_TAG_FT_verfahren "Türaussengriff FT Trigger zum Aus- und Einfahren";
CM_ SG_ 2463978792 ZV_TAG_HBFS_verfahren "Türaussengriff HBFS Trigger zum Aus- und Einfahren";
CM_ SG_ 2463978792 ZV_TAG_HFS_verfahren "Türaussengriff HFS Trigger zum Aus- und Einfahren";
CM_ SG_ 2463978792 ZV_verriegelt_extern_ist_02 "Istzustand: Verriegelung Fahrzeug aussen";
CM_ SG_ 2463978792 ZV_verriegelt_extern_soll_03 "Sollzustand: Verriegelung Fahrzeug aussen";
CM_ SG_ 2463978792 ZV_verriegelt_intern_ist_02 "Istzustand: Verriegelung Fahrzeug innen";
CM_ SG_ 2463978792 ZV_verriegelt_intern_soll_02 "Sollzustand: Verriegelung Fahrzeug innen";
CM_ SG_ 2463978792 ZV_zentral_entsafen "Zentral entsafen";
CM_ SG_ 2463978792 ZV_zentral_safen "Zentral safen";
CM_ SG_ 2463978792 ZV_zu_Zeitl_Nachverr "ZV Schliessstelle";

CM_ SG_ 902 CHA_Charge_LED "Ansteuerung der LED am Charge-Taster durch Charisma im PHEV";
CM_ SG_ 902 CHA_Charisma_Taste2_LED "Ansteuerung der 2. Charisma-Taste-LED";
CM_ SG_ 902 CHA_Current_Mode "Aktuell eingestelltes Charisma Fahrprogramm";
CM_ SG_ 902 CHA_Current_Mode_FPA "Aktuell eingestelltes Charisma Fahrprogramm";
CM_ SG_ 902 CHA_Eco_Charisma_LED "Ansteuerung der Funktions-LED der ECO alias Bluekey Taste bzw. Charisma-Taste.
Der Master der Fahrmodus-Funktion soll die Funktionsleuchte ansteuern, in der MQB Architektur ist der Master im Gateway untergebracht.";
CM_ SG_ 902 CHA_EV_LED "Ansteuerung der LED am EV-Taster durch Charisma im PHEV";
CM_ SG_ 902 CHA_Fahrer_Umschaltung "Die manuelle Umschaltung durch den Fahrer soll signalisiert werden, um zu automatischen Umschaltungen (z.B. Retries) differenzieren zu können.";
CM_ SG_ 902 CHA_Kombi_Texte "Anzeige des aktuellen Charisma-Fahrprofiles im Kombi.
Die Texte werden HUT-Spezifisch in einem Schnittstellen-LAH definiert.";
CM_ SG_ 902 CHA_Kombi_Texte_02 "Anzeige von Hinweistexten bzgl. Charismaumschaltungen im Kombi.
Die Texte werden HUT-Spezifisch in einem Schnittstellen-LAH definiert.";
CM_ SG_ 902 CHA_Offroad_LED "Ansteuerung der Offroad-LED";
CM_ SG_ 902 CHA_ReqPrgDispSetup "Requested Charisma-programm to Kombi to change display setup.";
CM_ SG_ 902 CHA_StCurProfDft "Signal indicates if the current Charisma-profile";
CM_ SG_ 902 CHA_Ziel_FahrPr_03_01 "reserviert für Anforderung Ziel-Fahrprogramm";
CM_ SG_ 902 CHA_Ziel_FahrPr_03_02 "reserviert für Anforderung Ziel-Fahrprogramm";
CM_ SG_ 902 CHA_Ziel_FahrPr_AMB "Anforderung Ziel-Fahrprogramm Ambientelichtmodul";
CM_ SG_ 902 CHA_Ziel_FahrPr_HSP "Anforderung Ziel-Fahrprogramm Heckspoiler";
CM_ SG_ 902 CHA_Ziel_FahrPr_IVB "Anforderung Ziel-Fahrprogramm IVB";
CM_ SG_ 902 CHA_Ziel_FahrPr_KL "Anforderung Ziel-Fahrprogramm Klima";
CM_ SG_ 902 CHA_Ziel_FahrPr_RWB "Anforderung Zielfahrprogramm Reichweitenberechnung (RWB)";

CM_ SG_ 2463978646 CHA_Current_Mode "Aktuell eingestelltes Charisma Fahrprogramm";
CM_ SG_ 2463978646 CHA_Fahrer_Umschaltung "Die manuelle Umschaltung durch den Fahrer soll signalisiert werden, um zu automatischen Umschaltungen (z.B. Retries) differenzieren zu können.";
CM_ SG_ 2463978646 CHA_Fahrer_Umschaltung_BMA "Die manuelle Umschaltung der Betriebsmodusauswahl durch den Fahrer soll signalisiert werden, um zu automatischen Umschaltungen (z.B. Retries) differenzieren zu können.";
CM_ SG_ 2463978646 CHA_Ziel_FahrPr_ACC "MQB
Anforderung Ziel-Fahrprogramm ACC";
CM_ SG_ 2463978646 CHA_Ziel_FahrPr_AEB "Anforderung Ziel-Fahrprogramm AEB (Autonomous Emergency Braking)";
CM_ SG_ 2463978646 CHA_Ziel_FahrPr_AFR "Anforderung Ziel-Fahrprogramm Aktive Fahrwerk Regelung (eAWS und eABC)";
CM_ SG_ 2463978646 CHA_Ziel_FahrPr_AFS "Anforderung Ziel-Fahrprogramm AFS";
CM_ SG_ 2463978646 CHA_Ziel_FahrPr_AGA "Anforderung Ziel-Fahrprogramm AGA/SAK2 (Aussensound)";
CM_ SG_ 2463978646 CHA_Ziel_FahrPr_AGK "Signal zur Ansteuerung des Teilnehmers Abgasklappen durch den Charisma-Koordinator über das Motor-SG";
CM_ SG_ 2463978646 CHA_Ziel_FahrPr_ALR "Anforderung Ziel-Fahrprogramm Allrad";
CM_ SG_ 2463978646 CHA_Ziel_FahrPr_AV "Anforderung Ziel-Fahrprogramm AreaView2";
CM_ SG_ 2463978646 CHA_Ziel_FahrPr_BMS "Anforderung Ziel-Fahrprogramm BMS (nähere Spezifikation siehe Charisma-LH PAG)";
CM_ SG_ 2463978646 CHA_Ziel_FahrPr_DR "Anforderung Ziel-Fahrprogramm Dämpfer";
CM_ SG_ 2463978646 CHA_Ziel_FahrPr_EAR "Anforderung Zielfahrprogramm EAR (EFP Allrad Regelsysteme)";
CM_ SG_ 2463978646 CHA_Ziel_FahrPr_EBKV "Signal zur Ansteuerung des EBKV durch den Charisma-Koordinator";
CM_ SG_ 2463978646 CHA_Ziel_FahrPr_EDS "Anforderung Ziel-Fahrprogramm Elektronische Differentialsperre";
CM_ SG_ 2463978646 CHA_Ziel_FahrPr_EPS "Anforderung Ziel-Fahrprogramm Elektrische Lenkhilfe";
CM_ SG_ 2463978646 CHA_Ziel_FahrPr_eSound "Anforderung Ziel-Fahrprogramm eSound";
CM_ SG_ 2463978646 CHA_Ziel_FahrPr_ESP "Anforderung Ziel-Fahrprogramm ESP";
CM_ SG_ 2463978646 CHA_Ziel_FahrPr_FCWO "Anforderung Ziel-Fahrprogramm FCWO (Objektwarnung)";
CM_ SG_ 2463978646 CHA_Ziel_FahrPr_FCWP "Anforderung Ziel-Fahrprogramm FCWP (Personenwarnung)";
CM_ SG_ 2463978646 CHA_Ziel_FahrPr_Freilauf "Anforderung Ziel-Fahrprogramm Funktion Freilauf";
CM_ SG_ 2463978646 CHA_Ziel_FahrPr_GE "Anforderung Ziel-Fahrprogramm Getriebe";
CM_ SG_ 2463978646 CHA_Ziel_FahrPr_HAL "Anforderung Zielfahrprogramm Hinterachslenkung (HAL)";
CM_ SG_ 2463978646 CHA_Ziel_FahrPr_HDC "Anforderung Ziel-Fahrprogramm Hill Descent Control";
CM_ SG_ 2463978646 CHA_Ziel_FahrPr_HHC "Anforderung Ziel-Fahrprogramm Hill Hold Control";
CM_ SG_ 2463978646 CHA_Ziel_FahrPr_IL "Anforderung Ziel-Fahrprogramm Integrallenkung";
CM_ SG_ 2463978646 CHA_Ziel_FahrPr_mFDR "Signal zur Ansteuerung des mFDR durch den Charisma-Koordinator";
CM_ SG_ 2463978646 CHA_Ziel_FahrPr_MO "Anforderung Ziel-Fahrprogramm Motor";
CM_ SG_ 2463978646 CHA_Ziel_FahrPr_MO_BZS "Anforderung Zielfahrprogramm Motor-Betriebszusände";
CM_ SG_ 2463978646 CHA_Ziel_FahrPr_MO_Freilauf "Anforderung Ziel-Fahrprogramm Funktion Freilauf Motor aus";
CM_ SG_ 2463978646 CHA_Ziel_FahrPr_MO_StSt "Anforderung Ziel-Fahrprogramm Funktion Motor Start-Stopp";
CM_ SG_ 2463978646 CHA_Ziel_FahrPr_MXB "Anforderung Ziel-Fahrprogramm MXB";
CM_ SG_ 2463978646 CHA_Ziel_FahrPr_NR "Anforderung Ziel-Fahrprogramm Niveaureglierung";
CM_ SG_ 2463978646 CHA_Ziel_FahrPr_PACC "Anforderung Ziel-Fahrprogramm InnoDrive (PACCh)";
CM_ SG_ 2463978646 CHA_Ziel_FahrPr_PDC "Signal zur Ansteuerung des PDC/PLA durch den Charisma-Koordinator";
CM_ SG_ 2463978646 CHA_Ziel_FahrPr_PreCrash "Anforderung Ziel-Fahrprogramm PreCrash";
CM_ SG_ 2463978646 CHA_Ziel_FahrPr_QS "Anforderung Ziel-Fahrprogramm geregelte Hinterachsquersperre";
CM_ SG_ 2463978646 CHA_Ziel_FahrPr_Reku_ZwGas "Anforderung Ziel-Fahrprogramm für Rekuperation oder Zwischengas";
CM_ SG_ 2463978646 CHA_Ziel_FahrPr_RHP "MQB
Anforderung Ziel-Fahrprogramm RHP";
CM_ SG_ 2463978646 CHA_Ziel_FahrPr_SAK "Anforderung Ziel-Fahrprogramm Soundaktuator";
CM_ SG_ 2463978646 CHA_Ziel_FahrPr_SCU "Anforderung Ziel-Fahrprogramm SCU";
CM_ SG_ 2463978646 CHA_Ziel_FahrPr_ToS_laengs "Signal zur Ansteuerung des Torque Splitter längs durch den Charisma-Koordinator";
CM_ SG_ 2463978646 CHA_Ziel_FahrPr_ToS_quer "Signal zur Ansteuerung des Torque Splitter quer durch den Charisma-Koordinator";
CM_ SG_ 2463978646 CHA_Ziel_FahrPr_VAQ "Anforderung Ziel-Fahrprogramm VAQ";

CM_ SG_ 2527679921 CPD_CallCenter "Trigger an Call Center";
CM_ SG_ 2527679921 CPD_Deaktivierung_Permanent "Status der permanenten Deaktivierung der CPD-Warnung zur Anzeige (z.B. in der App)";
CM_ SG_ 2527679921 CPD_Deaktivierung_Temp "Status der temporären Deaktivierung der CPD-Funktin zur Anzeige  in der App";
CM_ SG_ 2527679921 CPD_Mobiltelefon_BLE "Triggersignal CPD zu Car2Phone-App per Bluetooth";
CM_ SG_ 2527679921 CPD_Mobiltelefon_GSM "Trigger an Mobiltelefon über Mobilfunknetz";
CM_ SG_ 2527679921 CPDFct_Deakt "Anzeige Kombi bei KL15:AUS (Kombi) und Infotainment (während Fahrt) ob Fkt CPD 2.1 temporär oder dauerhaft deaktiviert wurde";
CM_ SG_ 2527679921 CPDFct_Symbol "Status der CPD Kontrollleuchte Fkt CPD 2.1";
CM_ SG_ 2527679921 CPDFct_Warnung "Anzeige Kombi bei KL15:AUS im Warnfall Fkt CPD 2.1";

CM_ SG_ 2331595987 CPD_Sensierung_Status "CPD Sensierung Status";
CM_ SG_ 2331595987 CPD_Warnstufe "Warnstufe der CPD-Sensierung";

CM_ SG_ 515 DR_Drehwinkel_HL "Drehwinkelsensor zur Berechnung von Dämpferweg und  für LWR";
CM_ SG_ 515 DR_Drehwinkel_HR "Drehwinkelsensor zur Berechnung von Dämpferweg und  für LWR";
CM_ SG_ 515 DR_Drehwinkel_VL "Drehwinkelsensor zur Berechnung von Dämpferweg und  für LWR";
CM_ SG_ 515 DR_Drehwinkel_VR "Drehwinkelsensor zur Berechnung von Dämpferweg und  für LWR";
CM_ SG_ 515 DR_Drehwinkelsensortausch_HL "Zähler der bei jedem erkannten Drehwinkelsensortausch inkrementiert wird. Systeme die den Drehwinkelwert empfangen können notwendigen Inbetriebnahmefunktionen starten";
CM_ SG_ 515 DR_Drehwinkelsensortausch_HR "Zähler der bei jedem erkannten Drehwinkelsensortausch inkrementiert wird. Systeme die den Drehwinkelwert empfangen können notwendigen Inbetriebnahmefunktionen starten";
CM_ SG_ 515 DR_Drehwinkelsensortausch_VL "Zähler der bei jedem erkannten Drehwinkelsensortausch inkrementiert wird. Systeme die den Drehwinkelwert empfangen können notwendigen Inbetriebnahmefunktionen starten";
CM_ SG_ 515 DR_Drehwinkelsensortausch_VR "Zähler der bei jedem erkannten Drehwinkelsensortausch inkrementiert wird. Systeme die den Drehwinkelwert empfangen können notwendigen Inbetriebnahmefunktionen starten";

CM_ SG_ 2583738904 DDA_AuthTime_Req_Data "AuthTime - Authentische Zeit
ISO-TP Datenkanal - NA2FID
Request Knoten 0xBA DDA (Transceiver Modul)

DDA an Funktion Authentische Zeit (Request)";

CM_ SG_ 2583869976 DDA_AuthTime_Resp_Data "AuthTime - Authentische Zeit
ISO-TP Datenkanal - NA2FID
Response Funktion 0x18 AuthTime

Funktion Authentische Zeit an DDA (Transceiver Modul) (Response)";

CM_ SG_ 2549891585 DIA_eTABSub_BFS_Req_Data "Diagnose Request Flashen eTABSub_BFS";

CM_ SG_ 2621456897 DIA_eTABSub_BFS_Req_FD_Data "Diagnose Request Flashen eTABSub_BFS";

CM_ SG_ 2550022657 DIA_eTABSub_BFS_Resp_Data "Diagnose Response Flashen eTABSub_BFS";

CM_ SG_ 2621587969 DIA_eTABSub_BFS_Resp_FD_Data "Diagnose Response Flashen eTABSub_BFS";

CM_ SG_ 2549891584 DIA_eTABSub_FS_Req_Data "Diagnose Request Flashen eTABSub_FS";

CM_ SG_ 2621456896 DIA_eTABSub_FS_Req_FD_Data "Diagnose Request Flashen eTABSub_FS";

CM_ SG_ 2550022656 DIA_eTABSub_FS_Resp_Data "Diagnose Response Flashen eTABSub_FS";

CM_ SG_ 2621587968 DIA_eTABSub_FS_Resp_FD_Data "Diagnose Request Flashen eTABSub_FS";

CM_ SG_ 2549891587 DIA_eTABSub_HBFS_Req_Data "Diagnose Request Flashen eTABSub_HBFS";

CM_ SG_ 2621456899 DIA_eTABSub_HBFS_Req_FD_Data "Diagnose Request Flashen eTABSub_HBFS";

CM_ SG_ 2550022659 DIA_eTABSub_HBFS_Resp_Data "Diagnose Response Flashen eTABSub_HBFS";

CM_ SG_ 2621587971 DIA_eTABSub_HBFS_Resp_FD_Data "Diagnose Request Flashen eTABSub_HBFS";

CM_ SG_ 2549891586 DIA_eTABSub_HFS_Req_Data "Diagnose Request Flashen eTABSub_HFS";

CM_ SG_ 2621456898 DIA_eTABSub_HFS_Req_FD_Data "Diagnose Request Flashen eTABSub_HFS";

CM_ SG_ 2550022658 DIA_eTABSub_HFS_Resp_Data "Diagnose Response Flashen eTABSub_HFS";

CM_ SG_ 2621587970 DIA_eTABSub_HFS_Resp_FD_Data "Diagnose Request Flashen eTABSub_HFS";

CM_ SG_ 2549880555 DIA_NFC_TGS_Req_Data "Flashen Steuergerät im Türgriff";

CM_ SG_ 2550011627 DIA_NFC_TGS_Resp_Data "Flashen Steuergerät im Türgriff";

CM_ SG_ 2549880322 DIA_RLF_Req_Data "LIN Flashen Regen-Licht-Feuchte-Sensor (DK2F)";

CM_ SG_ 2621445634 DIA_RLF_Req_FD_Data "LIN Flashen Regen-Licht-Feuchte-Sensor (DK2F)";

CM_ SG_ 2550011394 DIA_RLF_Resp_Data "LIN Flashen Regen-Licht-Feuchte-Sensor (DK2F)";

CM_ SG_ 2621576706 DIA_RLF_Resp_FD_Data "LIN Flashen Regen-Licht-Feuchte-Sensor (DK2F)";

CM_ SG_ 2549880357 DIA_SHL_li1_Req_Data "SHL_li1 DK2F";

CM_ SG_ 2621445669 DIA_SHL_li1_Req_FD_Data "Diagnose Request FD SHL_li1";

CM_ SG_ 2550011429 DIA_SHL_li1_Resp_Data "SHL_li1 DK2F";

CM_ SG_ 2621576741 DIA_SHL_li1_Resp_FD_Data "Diagnose Response FD SHL_li1";

CM_ SG_ 2549880590 DIA_SHL_li2_Req_Data "SHL_li2 DK2F";

CM_ SG_ 2621445902 DIA_SHL_li2_Req_FD_Data "Diagnose Request FD SHL_li2";

CM_ SG_ 2550011662 DIA_SHL_li2_Resp_Data "SHL_li2 DK2F";

CM_ SG_ 2621576974 DIA_SHL_li2_Resp_FD_Data "Diagnose Response FD SHL_li2";

CM_ SG_ 2549880591 DIA_SHL_re1_Req_Data "SHL_re1 DK2F";

CM_ SG_ 2621445903 DIA_SHL_re1_Req_FD_Data "Diagnose Request FD SHL_re1";

CM_ SG_ 2550011663 DIA_SHL_re1_Resp_Data "SHL_re1 DK2F";

CM_ SG_ 2621576975 DIA_SHL_re1_Resp_FD_Data "Diagnose Response FD SHL_re1";

CM_ SG_ 2549880592 DIA_SHL_re2_Req_Data "SHL_re2 DK2F";

CM_ SG_ 2621445904 DIA_SHL_re2_Req_FD_Data "Diagnose Request FD SHL_re2";

CM_ SG_ 2550011664 DIA_SHL_re2_Resp_Data "SHL_re2 DK2F";

CM_ SG_ 2621576976 DIA_SHL_re2_Resp_FD_Data "Diagnose Response FD SHL_re2";

CM_ SG_ 2549880734 DIA_VIP_HBFS_Req_Data "Diagnose Request VIP_HBFS";

CM_ SG_ 2621446046 DIA_VIP_HBFS_Req_FD_Data "Diagnose Request FD VIP_HBFS";

CM_ SG_ 2550011806 DIA_VIP_HBFS_Resp_Data "Diagnose Response VIP_HBFS";

CM_ SG_ 2621577118 DIA_VIP_HBFS_Resp_FD_Data "Diagnose Response FD VIP_HBFS";

CM_ SG_ 2549880720 DIA_VIP_HFS_Req_Data "Diagnose Request VIP_HFS";

CM_ SG_ 2621446032 DIA_VIP_HFS_Req_FD_Data "Diagnose Request FD VIP_HFS";

CM_ SG_ 2550011792 DIA_VIP_HFS_Resp_Data "Diagnose Response VIP_HFS";
BA_DEF_REL_ BU_SG_REL_  "GenSigTimeoutTime" INT 0 65535;
BA_DEF_ BO_  "DiagRequest" ENUM "No", "Yes";
BA_DEF_ BO_  "DiagResponse" ENUM "No", "Yes";
BA_DEF_ BO_  "DiagState" ENUM "No", "Yes";
BA_DEF_ BO_  "GenMsgChkConstant" HEX 0 4095;
BA_DEF_ BO_  "GenMsgCycleTime" INT 0 65535;
BA_DEF_ BO_  "GenMsgCycleTimeFast" INT 0 65535;
BA_DEF_ BO_  "GenMsgDelayTime" INT 0 100000;
BA_DEF_ BO_  "GenMsgILSupport" ENUM "No", "Yes";
BA_DEF_ BO_  "GenMsgNrOfRepetition" INT 0 100;
BA_DEF_ BO_  "GenMsgPDUConstants" STRING;
BA_DEF_ BO_  "GenMsgSendType" ENUM "Cyclic", "not_used", "not_used", "not_used", "not_used", "not_used", "not_used", "IfActive", "NoMsgSendType";
BA_DEF_ BO_  "GenMsgStartDelayTime" INT 0 100000;
BA_DEF_ BO_  "NmMessage" ENUM "No", "Yes";
BA_DEF_ BO_  "NmhMessage" ENUM "No", "Yes";
BA_DEF_ BO_  "MsgType" ENUM "Application", "NM ", "NMH", "TP2.0", "ISO-TP ", "BAP", "EID", "KS", "XCP_PRE_CONFIGURED", "XCP_RUNTIME_CONFIGURED";
BA_DEF_ BO_  "VAGTP20_API" HEX 0 255;
BA_DEF_ BO_  "VAGTP20_DynConnection" ENUM "No", "Yes";
BA_DEF_ BO_  "VAGTP20_DynSetup" ENUM "No", "Yes";
BA_DEF_ BO_  "VAGTP20_StatConnection" ENUM "No", "Yes";
BA_DEF_ BO_  "CANFD_BRS" ENUM "0", "1";
BA_DEF_ BO_  "VFrameFormat" ENUM "StandardCAN", "ExtendedCAN", "reserved", "reserved", "reserved", "reserved", "reserved", "reserved", "reserved", "reserved", "reserved", "reserved", "reserved", "reserved", "StandardCAN_FD", "ExtendedCAN_FD";
BA_DEF_ SG_  "GenSigActiveRepetitions" INT -2147483648 2147483647;
BA_DEF_ SG_  "GenSigInactiveValue" INT -2147483648 2147483647;
BA_DEF_ SG_  "GenSigSendType" ENUM "Cyclic", "OnWrite", "OnWriteWithRepetition", "OnChange", "OnChangeWithRepetition", "IfActive", "IfActiveWithRepetition", "NoSigSendType", "OnChangeAndIfActive", "OnChangeAndIfActiveWithRepetition";
BA_DEF_ SG_  "GenSigStartValue" INT -2147483648 2147483647;
BA_DEF_ SG_  "NWM-WakeupAllowed" ENUM "No", "Yes";
BA_DEF_ SG_  "GenSigFuncType" ENUM "NoFunction", "MsgCounter", "CRC-8", "XOR", "XOR-2", "DatedBit", "SW-Kl15", "CHK", "Constant", "Protocol", "CRC-8-SAE_J1850", "CRC-32", "DataLength", "DataID", "MsgCounter16", "SOK-Signatur", "Cluster";
BA_DEF_ SG_  "GenSigSwitchedByIgnition" ENUM "No", "Yes";
BA_DEF_ SG_  "Fehlerwert" HEX 0 2147483647;
BA_DEF_ SG_  "GenSigMissingSourceValue" HEX 0 2147483647;
BA_DEF_DEF_REL_  "GenSigTimeoutTime" 0;
BA_DEF_DEF_  "DiagRequest" "No";
BA_DEF_DEF_  "DiagResponse" "No";
BA_DEF_DEF_  "DiagState" "No";
BA_DEF_DEF_  "GenMsgChkConstant" 0;
BA_DEF_DEF_  "GenMsgCycleTime" 0;
BA_DEF_DEF_  "GenMsgCycleTimeFast" 0;
BA_DEF_DEF_  "GenMsgDelayTime" 0;
BA_DEF_DEF_  "GenMsgILSupport" "No";
BA_DEF_DEF_  "GenMsgNrOfRepetition" 0;
BA_DEF_DEF_  "GenMsgPDUConstants" "";
BA_DEF_DEF_  "GenMsgSendType" "NoMsgSendType";
BA_DEF_DEF_  "GenMsgStartDelayTime" 0;
BA_DEF_DEF_  "NmMessage" "No";
BA_DEF_DEF_  "NmhMessage" "No";
BA_DEF_DEF_  "MsgType" "Application";
BA_DEF_DEF_  "VAGTP20_API" 0;
BA_DEF_DEF_  "VAGTP20_DynConnection" "No";
BA_DEF_DEF_  "VAGTP20_DynSetup" "No";
BA_DEF_DEF_  "VAGTP20_StatConnection" "No";
BA_DEF_DEF_  "CANFD_BRS" "1";
BA_DEF_DEF_  "VFrameFormat" "StandardCAN";
BA_DEF_DEF_  "GenSigActiveRepetitions" 0;
BA_DEF_DEF_  "GenSigInactiveValue" 0;
BA_DEF_DEF_  "GenSigSendType" "NoSigSendType";
BA_DEF_DEF_  "GenSigStartValue" 0;
BA_DEF_DEF_  "NWM-WakeupAllowed" "No";
BA_DEF_DEF_  "GenSigFuncType" "NoFunction";
BA_DEF_DEF_  "GenSigSwitchedByIgnition" "Yes";
BA_DEF_DEF_  "Fehlerwert" 0;
BA_DEF_DEF_  "GenSigMissingSourceValue" 0;
BA_ "GenMsgCycleTimeFast" BO_ 1427 200;
BA_ "GenMsgDelayTime" BO_ 1427 20;
BA_ "GenMsgILSupport" BO_ 1427 1;
BA_ "GenMsgSendType" BO_ 1427 7;
BA_ "CANFD_BRS" BO_ 1427 0;
BA_ "VFrameFormat" BO_ 1427 14;
BA_ "GenMsgCycleTime" BO_ 1432 1000;
BA_ "GenMsgCycleTimeFast" BO_ 1432 100;
BA_ "GenMsgDelayTime" BO_ 1432 20;
BA_ "GenMsgILSupport" BO_ 1432 1;
BA_ "GenMsgNrOfRepetition" BO_ 1432 5;
BA_ "GenMsgSendType" BO_ 1432 0;
BA_ "CANFD_BRS" BO_ 1432 0;
BA_ "VFrameFormat" BO_ 1432 14;
BA_ "GenMsgCycleTime" BO_ 2527679781 1000;
BA_ "GenMsgDelayTime" BO_ 2527679781 20;
BA_ "GenMsgILSupport" BO_ 2527679781 1;
BA_ "GenMsgSendType" BO_ 2527679781 0;
BA_ "CANFD_BRS" BO_ 2527679781 0;
BA_ "VFrameFormat" BO_ 2527679781 15;
BA_ "GenMsgCycleTime" BO_ 2463978855 200;
BA_ "GenMsgDelayTime" BO_ 2463978855 20;
BA_ "GenMsgILSupport" BO_ 2463978855 1;
BA_ "GenMsgSendType" BO_ 2463978855 0;
BA_ "CANFD_BRS" BO_ 2463978855 0;
BA_ "VFrameFormat" BO_ 2463978855 15;
BA_ "GenMsgCycleTime" BO_ 1635 100;
BA_ "GenMsgILSupport" BO_ 1635 1;
BA_ "GenMsgSendType" BO_ 1635 0;
BA_ "CANFD_BRS" BO_ 1635 0;
BA_ "VFrameFormat" BO_ 1635 14;
BA_ "GenMsgCycleTime" BO_ 1163 100;
BA_ "GenMsgILSupport" BO_ 1163 1;
BA_ "GenMsgPDUConstants" BO_ 1163 "0x54,0xaf,0x8a,0xfb,0x0d,0x87,0x6a,0x0f,0x47,0x78,0x31,0x4f,0x35,0x28,0x82,0x6d";
BA_ "GenMsgSendType" BO_ 1163 0;
BA_ "CANFD_BRS" BO_ 1163 0;
BA_ "VFrameFormat" BO_ 1163 14;
BA_ "GenMsgCycleTime" BO_ 2463978850 100;
BA_ "GenMsgILSupport" BO_ 2463978850 1;
BA_ "GenMsgPDUConstants" BO_ 2463978850 "0xaa,0xa9,0xe6,0xc5,0xc4,0x2b,0x0b,0x8e,0xfb,0x15,0xa4,0x64,0x1e,0x20,0x50,0x95";
BA_ "GenMsgSendType" BO_ 2463978850 0;
BA_ "CANFD_BRS" BO_ 2463978850 0;
BA_ "VFrameFormat" BO_ 2463978850 15;
BA_ "GenMsgCycleTime" BO_ 870 1000;
BA_ "GenMsgCycleTimeFast" BO_ 870 50;
BA_ "GenMsgDelayTime" BO_ 870 10;
BA_ "GenMsgILSupport" BO_ 870 1;
BA_ "GenMsgNrOfRepetition" BO_ 870 5;
BA_ "GenMsgPDUConstants" BO_ 870 "0xa9,0xbd,0xfb,0x3c,0x95,0x0f,0x75,0x3a,0x4f,0x19,0x59,0x6d,0xb2,0xe9,0xd1,0x97";
BA_ "GenMsgSendType" BO_ 870 0;
BA_ "CANFD_BRS" BO_ 870 0;
BA_ "VFrameFormat" BO_ 870 14;
BA_ "GenMsgChkConstant" BO_ 1482 67;
BA_ "GenMsgCycleTime" BO_ 1482 500;
BA_ "GenMsgDelayTime" BO_ 1482 50;
BA_ "GenMsgILSupport" BO_ 1482 1;
BA_ "GenMsgPDUConstants" BO_ 1482 "0x43,0x43,0x43,0x43,0x43,0x43,0x43,0x43,0x43,0x43,0x43,0x43,0x43,0x43,0x43,0x43";
BA_ "GenMsgSendType" BO_ 1482 0;
BA_ "CANFD_BRS" BO_ 1482 0;
BA_ "VFrameFormat" BO_ 1482 14;
BA_ "GenMsgCycleTime" BO_ 2331596015 500;
BA_ "GenMsgCycleTimeFast" BO_ 2331596015 50;
BA_ "GenMsgDelayTime" BO_ 2331596015 50;
BA_ "GenMsgILSupport" BO_ 2331596015 1;
BA_ "GenMsgNrOfRepetition" BO_ 2331596015 5;
BA_ "GenMsgSendType" BO_ 2331596015 0;
BA_ "CANFD_BRS" BO_ 2331596015 0;
BA_ "VFrameFormat" BO_ 2331596015 15;
BA_ "GenMsgCycleTime" BO_ 2331596016 500;
BA_ "GenMsgCycleTimeFast" BO_ 2331596016 50;
BA_ "GenMsgDelayTime" BO_ 2331596016 50;
BA_ "GenMsgILSupport" BO_ 2331596016 1;
BA_ "GenMsgNrOfRepetition" BO_ 2331596016 5;
BA_ "GenMsgSendType" BO_ 2331596016 0;
BA_ "CANFD_BRS" BO_ 2331596016 0;
BA_ "VFrameFormat" BO_ 2331596016 15;
BA_ "GenMsgCycleTime" BO_ 2463978792 200;
BA_ "GenMsgCycleTimeFast" BO_ 2463978792 20;
BA_ "GenMsgDelayTime" BO_ 2463978792 20;
BA_ "GenMsgILSupport" BO_ 2463978792 1;
BA_ "GenMsgNrOfRepetition" BO_ 2463978792 50;
BA_ "GenMsgPDUConstants" BO_ 2463978792 "0xa0,0x7c,0x1f,0xf6,0x43,0x2e,0xc0,0x74,0xb8,0xc3,0x9f,0x26,0x68,0x61,0xfb,0x70";
BA_ "GenMsgSendType" BO_ 2463978792 0;
BA_ "CANFD_BRS" BO_ 2463978792 0;
BA_ "VFrameFormat" BO_ 2463978792 15;
BA_ "GenMsgCycleTime" BO_ 902 1000;
BA_ "GenMsgDelayTime" BO_ 902 50;
BA_ "GenMsgILSupport" BO_ 902 1;
BA_ "GenMsgSendType" BO_ 902 0;
BA_ "CANFD_BRS" BO_ 902 0;
BA_ "VFrameFormat" BO_ 902 14;
BA_ "GenMsgCycleTime" BO_ 2463978646 1000;
BA_ "GenMsgDelayTime" BO_ 2463978646 50;
BA_ "GenMsgILSupport" BO_ 2463978646 1;
BA_ "GenMsgSendType" BO_ 2463978646 0;
BA_ "CANFD_BRS" BO_ 2463978646 0;
BA_ "VFrameFormat" BO_ 2463978646 15;
BA_ "GenMsgCycleTime" BO_ 2527679921 200;
BA_ "GenMsgDelayTime" BO_ 2527679921 10;
BA_ "GenMsgILSupport" BO_ 2527679921 1;
BA_ "GenMsgSendType" BO_ 2527679921 0;
BA_ "CANFD_BRS" BO_ 2527679921 0;
BA_ "VFrameFormat" BO_ 2527679921 15;
BA_ "GenMsgCycleTime" BO_ 2331595987 200;
BA_ "GenMsgDelayTime" BO_ 2331595987 10;
BA_ "GenMsgILSupport" BO_ 2331595987 1;
BA_ "GenMsgSendType" BO_ 2331595987 0;
BA_ "CANFD_BRS" BO_ 2331595987 0;
BA_ "VFrameFormat" BO_ 2331595987 15;
BA_ "GenMsgCycleTime" BO_ 515 20;
BA_ "GenMsgILSupport" BO_ 515 1;
BA_ "GenMsgSendType" BO_ 515 0;
BA_ "CANFD_BRS" BO_ 515 0;
BA_ "VFrameFormat" BO_ 515 14;
BA_ "MsgType" BO_ 2583738904 4;
BA_ "CANFD_BRS" BO_ 2583738904 0;
BA_ "VFrameFormat" BO_ 2583738904 15;
BA_ "MsgType" BO_ 2583869976 4;
BA_ "CANFD_BRS" BO_ 2583869976 0;
BA_ "VFrameFormat" BO_ 2583869976 15;
BA_ "MsgType" BO_ 2617103104 6;
BA_ "CANFD_BRS" BO_ 2617103104 0;
BA_ "VFrameFormat" BO_ 2617103104 15;
BA_ "MsgType" BO_ 2617103359 6;
BA_ "CANFD_BRS" BO_ 2617103359 0;
BA_ "VFrameFormat" BO_ 2617103359 15;
BA_ "MsgType" BO_ 2566843136 6;
BA_ "CANFD_BRS" BO_ 2566843136 0;
BA_ "VFrameFormat" BO_ 2566843136 15;
BA_ "MsgType" BO_ 2566843391 6;
BA_ "CANFD_BRS" BO_ 2566843391 0;
BA_ "VFrameFormat" BO_ 2566843391 15;
BA_ "DiagRequest" BO_ 2549891585 1;
BA_ "MsgType" BO_ 2549891585 4;
BA_ "CANFD_BRS" BO_ 2549891585 0;
BA_ "VFrameFormat" BO_ 2549891585 15;
BA_ "DiagRequest" BO_ 2621456897 1;
BA_ "MsgType" BO_ 2621456897 4;
BA_ "CANFD_BRS" BO_ 2621456897 0;
BA_ "VFrameFormat" BO_ 2621456897 15;
BA_ "DiagResponse" BO_ 2550022657 1;
BA_ "MsgType" BO_ 2550022657 4;
BA_ "CANFD_BRS" BO_ 2550022657 0;
BA_ "VFrameFormat" BO_ 2550022657 15;
BA_ "DiagResponse" BO_ 2621587969 1;
BA_ "MsgType" BO_ 2621587969 4;
BA_ "CANFD_BRS" BO_ 2621587969 0;
BA_ "VFrameFormat" BO_ 2621587969 15;
BA_ "DiagRequest" BO_ 2549891584 1;
BA_ "MsgType" BO_ 2549891584 4;
BA_ "CANFD_BRS" BO_ 2549891584 0;
BA_ "VFrameFormat" BO_ 2549891584 15;
BA_ "DiagRequest" BO_ 2621456896 1;
BA_ "MsgType" BO_ 2621456896 4;
BA_ "CANFD_BRS" BO_ 2621456896 0;
BA_ "VFrameFormat" BO_ 2621456896 15;
BA_ "DiagResponse" BO_ 2550022656 1;
BA_ "MsgType" BO_ 2550022656 4;
BA_ "CANFD_BRS" BO_ 2550022656 0;
BA_ "VFrameFormat" BO_ 2550022656 15;
BA_ "DiagResponse" BO_ 2621587968 1;
BA_ "MsgType" BO_ 2621587968 4;
BA_ "CANFD_BRS" BO_ 2621587968 0;
BA_ "VFrameFormat" BO_ 2621587968 15;
BA_ "DiagRequest" BO_ 2549891587 1;
BA_ "MsgType" BO_ 2549891587 4;
BA_ "CANFD_BRS" BO_ 2549891587 0;
BA_ "VFrameFormat" BO_ 2549891587 15;
BA_ "DiagRequest" BO_ 2621456899 1;
BA_ "MsgType" BO_ 2621456899 4;
BA_ "CANFD_BRS" BO_ 2621456899 0;
BA_ "VFrameFormat" BO_ 2621456899 15;
BA_ "DiagResponse" BO_ 2550022659 1;
BA_ "MsgType" BO_ 2550022659 4;
BA_ "CANFD_BRS" BO_ 2550022659 0;
BA_ "VFrameFormat" BO_ 2550022659 15;
BA_ "DiagResponse" BO_ 2621587971 1;
BA_ "MsgType" BO_ 2621587971 4;
BA_ "CANFD_BRS" BO_ 2621587971 0;
BA_ "VFrameFormat" BO_ 2621587971 15;
BA_ "DiagRequest" BO_ 2549891586 1;
BA_ "MsgType" BO_ 2549891586 4;
BA_ "CANFD_BRS" BO_ 2549891586 0;
BA_ "VFrameFormat" BO_ 2549891586 15;
BA_ "DiagRequest" BO_ 2621456898 1;
BA_ "MsgType" BO_ 2621456898 4;
BA_ "CANFD_BRS" BO_ 2621456898 0;
BA_ "VFrameFormat" BO_ 2621456898 15;
BA_ "DiagResponse" BO_ 2550022658 1;
BA_ "MsgType" BO_ 2550022658 4;
BA_ "CANFD_BRS" BO_ 2550022658 0;
BA_ "VFrameFormat" BO_ 2550022658 15;
BA_ "DiagResponse" BO_ 2621587970 1;
BA_ "MsgType" BO_ 2621587970 4;
BA_ "CANFD_BRS" BO_ 2621587970 0;
BA_ "VFrameFormat" BO_ 2621587970 15;
BA_ "DiagRequest" BO_ 2549880555 1;
BA_ "MsgType" BO_ 2549880555 4;
BA_ "CANFD_BRS" BO_ 2549880555 0;
BA_ "VFrameFormat" BO_ 2549880555 15;
BA_ "DiagResponse" BO_ 2550011627 1;
BA_ "MsgType" BO_ 2550011627 4;
BA_ "CANFD_BRS" BO_ 2550011627 0;
BA_ "VFrameFormat" BO_ 2550011627 15;
BA_ "DiagRequest" BO_ 2549880322 1;
BA_ "MsgType" BO_ 2549880322 4;
BA_ "CANFD_BRS" BO_ 2549880322 0;
BA_ "VFrameFormat" BO_ 2549880322 15;
BA_ "DiagRequest" BO_ 2621445634 1;
BA_ "MsgType" BO_ 2621445634 4;
BA_ "CANFD_BRS" BO_ 2621445634 0;
BA_ "VFrameFormat" BO_ 2621445634 15;
BA_ "DiagResponse" BO_ 2550011394 1;
BA_ "MsgType" BO_ 2550011394 4;
BA_ "CANFD_BRS" BO_ 2550011394 0;
BA_ "VFrameFormat" BO_ 2550011394 15;
BA_ "DiagResponse" BO_ 2621576706 1;
BA_ "MsgType" BO_ 2621576706 4;
BA_ "CANFD_BRS" BO_ 2621576706 0;
BA_ "VFrameFormat" BO_ 2621576706 15;
BA_ "DiagRequest" BO_ 2549880357 1;
BA_ "MsgType" BO_ 2549880357 4;
BA_ "CANFD_BRS" BO_ 2549880357 0;
BA_ "VFrameFormat" BO_ 2549880357 15;
BA_ "DiagRequest" BO_ 2621445669 1;
BA_ "MsgType" BO_ 2621445669 4;
BA_ "CANFD_BRS" BO_ 2621445669 0;
BA_ "VFrameFormat" BO_ 2621445669 15;
BA_ "DiagResponse" BO_ 2550011429 1;
BA_ "MsgType" BO_ 2550011429 4;
BA_ "CANFD_BRS" BO_ 2550011429 0;
BA_ "VFrameFormat" BO_ 2550011429 15;
BA_ "DiagResponse" BO_ 2621576741 1;
BA_ "MsgType" BO_ 2621576741 4;
BA_ "CANFD_BRS" BO_ 2621576741 0;
BA_ "VFrameFormat" BO_ 2621576741 15;
BA_ "DiagRequest" BO_ 2549880590 1;
BA_ "MsgType" BO_ 2549880590 4;
BA_ "CANFD_BRS" BO_ 2549880590 0;
BA_ "VFrameFormat" BO_ 2549880590 15;
BA_ "DiagRequest" BO_ 2621445902 1;
BA_ "MsgType" BO_ 2621445902 4;
BA_ "CANFD_BRS" BO_ 2621445902 0;
BA_ "VFrameFormat" BO_ 2621445902 15;
BA_ "DiagResponse" BO_ 2550011662 1;
BA_ "MsgType" BO_ 2550011662 4;
BA_ "CANFD_BRS" BO_ 2550011662 0;
BA_ "VFrameFormat" BO_ 2550011662 15;
BA_ "DiagResponse" BO_ 2621576974 1;
BA_ "MsgType" BO_ 2621576974 4;
BA_ "CANFD_BRS" BO_ 2621576974 0;
BA_ "VFrameFormat" BO_ 2621576974 15;
BA_ "DiagRequest" BO_ 2549880591 1;
BA_ "MsgType" BO_ 2549880591 4;
BA_ "CANFD_BRS" BO_ 2549880591 0;
BA_ "VFrameFormat" BO_ 2549880591 15;
BA_ "DiagRequest" BO_ 2621445903 1;
BA_ "MsgType" BO_ 2621445903 4;
BA_ "CANFD_BRS" BO_ 2621445903 0;
BA_ "VFrameFormat" BO_ 2621445903 15;
BA_ "DiagResponse" BO_ 2550011663 1;
BA_ "MsgType" BO_ 2550011663 4;
BA_ "CANFD_BRS" BO_ 2550011663 0;
BA_ "VFrameFormat" BO_ 2550011663 15;
BA_ "DiagResponse" BO_ 2621576975 1;
BA_ "MsgType" BO_ 2621576975 4;
BA_ "CANFD_BRS" BO_ 2621576975 0;
BA_ "VFrameFormat" BO_ 2621576975 15;
BA_ "DiagRequest" BO_ 2549880592 1;
BA_ "MsgType" BO_ 2549880592 4;
BA_ "CANFD_BRS" BO_ 2549880592 0;
BA_ "VFrameFormat" BO_ 2549880592 15;
BA_ "DiagRequest" BO_ 2621445904 1;
BA_ "MsgType" BO_ 2621445904 4;
BA_ "CANFD_BRS" BO_ 2621445904 0;
BA_ "VFrameFormat" BO_ 2621445904 15;
BA_ "DiagResponse" BO_ 2550011664 1;
BA_ "MsgType" BO_ 2550011664 4;
BA_ "CANFD_BRS" BO_ 2550011664 0;
BA_ "VFrameFormat" BO_ 2550011664 15;
BA_ "DiagResponse" BO_ 2621576976 1;
BA_ "MsgType" BO_ 2621576976 4;
BA_ "CANFD_BRS" BO_ 2621576976 0;
BA_ "VFrameFormat" BO_ 2621576976 15;
BA_ "DiagRequest" BO_ 2549880734 1;
BA_ "MsgType" BO_ 2549880734 4;
BA_ "CANFD_BRS" BO_ 2549880734 0;
BA_ "VFrameFormat" BO_ 2549880734 15;
BA_ "DiagRequest" BO_ 2621446046 1;
BA_ "MsgType" BO_ 2621446046 4;
BA_ "CANFD_BRS" BO_ 2621446046 0;
BA_ "VFrameFormat" BO_ 2621446046 15;
BA_ "DiagResponse" BO_ 2550011806 1;
BA_ "MsgType" BO_ 2550011806 4;
BA_ "CANFD_BRS" BO_ 2550011806 0;
BA_ "VFrameFormat" BO_ 2550011806 15;
BA_ "DiagResponse" BO_ 2621577118 1;
BA_ "MsgType" BO_ 2621577118 4;
BA_ "CANFD_BRS" BO_ 2621577118 0;
BA_ "VFrameFormat" BO_ 2621577118 15;
BA_ "DiagRequest" BO_ 2549880720 1;
BA_ "MsgType" BO_ 2549880720 4;
BA_ "CANFD_BRS" BO_ 2549880720 0;
BA_ "VFrameFormat" BO_ 2549880720 15;
BA_ "DiagRequest" BO_ 2621446032 1;
BA_ "MsgType" BO_ 2621446032 4;
BA_ "CANFD_BRS" BO_ 2621446032 0;
BA_ "VFrameFormat" BO_ 2621446032 15;
BA_ "DiagResponse" BO_ 2550011792 1;
BA_ "MsgType" BO_ 2550011792 4;
BA_ "CANFD_BRS" BO_ 2550011792 0;
BA_ "VFrameFormat" BO_ 2550011792 15;
BA_ "GenSigSendType" SG_ 1427 KY_Anf_Reichwbegr 3;
BA_ "GenSigSwitchedByIgnition" SG_ 1427 KY_Anf_Reichwbegr 0;
BA_ "GenSigSendType" SG_ 1427 KY_Anf_Reichwbegr_Gesamt 3;
BA_ "GenSigSwitchedByIgnition" SG_ 1427 KY_Anf_Reichwbegr_Gesamt 0;
BA_ "GenSigSendType" SG_ 1427 KY_Autofunktion_Aktiv 3;
BA_ "GenSigSwitchedByIgnition" SG_ 1427 KY_Autofunktion_Aktiv 0;
BA_ "GenSigSendType" SG_ 1427 KY_Bedienstelle 3;
BA_ "GenSigSwitchedByIgnition" SG_ 1427 KY_Bedienstelle 0;
BA_ "GenSigSendType" SG_ 1427 KY_Entriegeln 3;
BA_ "GenSigSwitchedByIgnition" SG_ 1427 KY_Entriegeln 0;
BA_ "GenSigSendType" SG_ 1427 KY_FFB_in_LF_Reichw 3;
BA_ "GenSigSwitchedByIgnition" SG_ 1427 KY_FFB_in_LF_Reichw 0;
BA_ "GenSigSendType" SG_ 1427 KY_HD_Verriegelung_Autorisiert 1;
BA_ "GenSigSwitchedByIgnition" SG_ 1427 KY_HD_Verriegelung_Autorisiert 0;
BA_ "GenSigSendType" SG_ 1427 KY_IDGeber_1_Bat 3;
BA_ "GenSigSwitchedByIgnition" SG_ 1427 KY_IDGeber_1_Bat 0;
BA_ "GenSigSendType" SG_ 1427 KY_IDGeber_1_Status 3;
BA_ "GenSigSwitchedByIgnition" SG_ 1427 KY_IDGeber_1_Status 0;
BA_ "GenSigSendType" SG_ 1427 KY_IDGeber_2_Bat 3;
BA_ "GenSigSwitchedByIgnition" SG_ 1427 KY_IDGeber_2_Bat 0;
BA_ "GenSigSendType" SG_ 1427 KY_IDGeber_2_Status 3;
BA_ "GenSigSwitchedByIgnition" SG_ 1427 KY_IDGeber_2_Status 0;
BA_ "GenSigSendType" SG_ 1427 KY_IDGeber_3_Bat 3;
BA_ "GenSigSwitchedByIgnition" SG_ 1427 KY_IDGeber_3_Bat 0;
BA_ "GenSigSendType" SG_ 1427 KY_IDGeber_3_Status 3;
BA_ "GenSigSwitchedByIgnition" SG_ 1427 KY_IDGeber_3_Status 0;
BA_ "GenSigSendType" SG_ 1427 KY_IDGeber_4_Bat 3;
BA_ "GenSigSwitchedByIgnition" SG_ 1427 KY_IDGeber_4_Bat 0;
BA_ "GenSigSendType" SG_ 1427 KY_IDGeber_4_Status 3;
BA_ "GenSigSwitchedByIgnition" SG_ 1427 KY_IDGeber_4_Status 0;
BA_ "GenSigSendType" SG_ 1427 KY_KessyEntryExit_Akt 3;
BA_ "GenSigSwitchedByIgnition" SG_ 1427 KY_KessyEntryExit_Akt 0;
BA_ "GenSigSendType" SG_ 1427 KY_Nr_IDGeber_Autofkt 3;
BA_ "GenSigSwitchedByIgnition" SG_ 1427 KY_Nr_IDGeber_Autofkt 0;
BA_ "GenSigSendType" SG_ 1427 KY_RSSI_Wert 3;
BA_ "GenSigSwitchedByIgnition" SG_ 1427 KY_RSSI_Wert 0;
BA_ "GenSigSendType" SG_ 1427 KY_Schluesselnr 3;
BA_ "GenSigSwitchedByIgnition" SG_ 1427 KY_Schluesselnr 0;
BA_ "GenSigSendType" SG_ 1427 KY_Softtouch 3;
BA_ "GenSigSwitchedByIgnition" SG_ 1427 KY_Softtouch 0;
BA_ "GenSigSendType" SG_ 1427 KY_Verriegeln 3;
BA_ "GenSigSwitchedByIgnition" SG_ 1427 KY_Verriegeln 0;
BA_ "GenSigSendType" SG_ 1427 KY_ZV_CMD 3;
BA_ "GenSigSwitchedByIgnition" SG_ 1427 KY_ZV_CMD 0;
BA_ "GenSigSendType" SG_ 1427 ZV_Anf_Abschaltung_Zuendung 3;
BA_ "GenSigSwitchedByIgnition" SG_ 1427 ZV_Anf_Abschaltung_Zuendung 0;
BA_ "GenSigSendType" SG_ 1432 BCM_BFS_Massage_Taster 3;
BA_ "GenSigSwitchedByIgnition" SG_ 1432 BCM_BFS_Massage_Taster 0;
BA_ "GenSigSendType" SG_ 1432 BCM_BFS_Multif_Taster 3;
BA_ "GenSigSwitchedByIgnition" SG_ 1432 BCM_BFS_Multif_Taster 0;
BA_ "GenSigSendType" SG_ 1432 BCM_BFS_Pneumatik_Verstellung 3;
BA_ "GenSigSwitchedByIgnition" SG_ 1432 BCM_BFS_Pneumatik_Verstellung 0;
BA_ "GenSigSendType" SG_ 1432 BCM_BFS_Programmwippe 3;
BA_ "GenSigSwitchedByIgnition" SG_ 1432 BCM_BFS_Programmwippe 0;
BA_ "GenSigSendType" SG_ 1432 BCM_FS_Massage_Taster 3;
BA_ "GenSigSwitchedByIgnition" SG_ 1432 BCM_FS_Massage_Taster 0;
BA_ "GenSigSendType" SG_ 1432 BCM_FS_Multif_Taster 3;
BA_ "GenSigSwitchedByIgnition" SG_ 1432 BCM_FS_Multif_Taster 0;
BA_ "GenSigSendType" SG_ 1432 BCM_FS_Pneumatik_Verstellung 3;
BA_ "GenSigSwitchedByIgnition" SG_ 1432 BCM_FS_Pneumatik_Verstellung 0;
BA_ "GenSigSendType" SG_ 1432 BCM_FS_Programmwippe 3;
BA_ "GenSigSwitchedByIgnition" SG_ 1432 BCM_FS_Programmwippe 0;
BA_ "GenSigSendType" SG_ 1432 LIM_bCall_Taster 4;
BA_ "GenSigSwitchedByIgnition" SG_ 1432 LIM_bCall_Taster 0;
BA_ "GenSigSendType" SG_ 1432 LIM_iCall_Taster 4;
BA_ "GenSigSwitchedByIgnition" SG_ 1432 LIM_iCall_Taster 0;
BA_ "GenSigActiveRepetitions" SG_ 1432 LIM_S_Rollo_hi 5;
BA_ "GenSigSendType" SG_ 1432 LIM_S_Rollo_hi 4;
BA_ "GenSigSwitchedByIgnition" SG_ 1432 LIM_S_Rollo_hi 0;
BA_ "GenSigActiveRepetitions" SG_ 1432 LIM_S_Rollo_vo 5;
BA_ "GenSigSendType" SG_ 1432 LIM_S_Rollo_vo 4;
BA_ "GenSigSwitchedByIgnition" SG_ 1432 LIM_S_Rollo_vo 0;
BA_ "GenSigActiveRepetitions" SG_ 1432 LIM_S_SAD_hi 5;
BA_ "GenSigSendType" SG_ 1432 LIM_S_SAD_hi 4;
BA_ "GenSigSwitchedByIgnition" SG_ 1432 LIM_S_SAD_hi 0;
BA_ "GenSigActiveRepetitions" SG_ 1432 LIM_S_SAD_Vo 5;
BA_ "GenSigSendType" SG_ 1432 LIM_S_SAD_Vo 4;
BA_ "GenSigSwitchedByIgnition" SG_ 1432 LIM_S_SAD_Vo 0;
BA_ "GenSigSendType" SG_ 1432 LINDa_Touch_Event 3;
BA_ "GenSigSwitchedByIgnition" SG_ 1432 LINDa_Touch_Event 0;
BA_ "Fehlerwert" SG_ 1432 LINDa_Touch_Event 15;
BA_ "GenSigSendType" SG_ 2527679781 LINDa_HL_SR3_Touch_Event 3;
BA_ "GenSigSwitchedByIgnition" SG_ 2527679781 LINDa_HL_SR3_Touch_Event 0;
BA_ "Fehlerwert" SG_ 2527679781 LINDa_HL_SR3_Touch_Event 15;
BA_ "GenSigSendType" SG_ 2527679781 LINDa_HL_Touch_Event 3;
BA_ "GenSigSwitchedByIgnition" SG_ 2527679781 LINDa_HL_Touch_Event 0;
BA_ "Fehlerwert" SG_ 2527679781 LINDa_HL_Touch_Event 15;
BA_ "GenSigSendType" SG_ 2527679781 LINDa_HR_SR3_Touch_Event 3;
BA_ "GenSigSwitchedByIgnition" SG_ 2527679781 LINDa_HR_SR3_Touch_Event 0;
BA_ "Fehlerwert" SG_ 2527679781 LINDa_HR_SR3_Touch_Event 15;
BA_ "GenSigSendType" SG_ 2527679781 LINDa_HR_Touch_Event 3;
BA_ "GenSigSwitchedByIgnition" SG_ 2527679781 LINDa_HR_Touch_Event 0;
BA_ "Fehlerwert" SG_ 2527679781 LINDa_HR_Touch_Event 15;
BA_ "GenSigSendType" SG_ 2463978855 DML_ConstructionZone_Enabled 3;
BA_ "GenSigSwitchedByIgnition" SG_ 2463978855 DML_ConstructionZone_Enabled 0;
BA_ "GenSigSendType" SG_ 2463978855 DML_CrossingAssist_Enabled 3;
BA_ "GenSigSwitchedByIgnition" SG_ 2463978855 DML_CrossingAssist_Enabled 0;
BA_ "GenSigSendType" SG_ 2463978855 DML_GhostDriverWarn_Enabled 3;
BA_ "GenSigSwitchedByIgnition" SG_ 2463978855 DML_GhostDriverWarn_Enabled 0;
BA_ "GenSigSendType" SG_ 2463978855 DML_GlarefreeHB_Enabled 3;
BA_ "GenSigSwitchedByIgnition" SG_ 2463978855 DML_GlarefreeHB_Enabled 0;
BA_ "GenSigSendType" SG_ 2463978855 DML_HazardWarning_Enabled 3;
BA_ "GenSigSwitchedByIgnition" SG_ 2463978855 DML_HazardWarning_Enabled 0;
BA_ "GenSigSendType" SG_ 2463978855 DML_HMI_FCN_CROSSINGLI_REQUEST 3;
BA_ "GenSigSendType" SG_ 2463978855 DML_HMI_FCN_HAZARDWARN_REQUEST 3;
BA_ "GenSigSendType" SG_ 2463978855 DML_HMI_FCN_LANELIGHT_REQUEST 3;
BA_ "GenSigSendType" SG_ 2463978855 DML_HMI_FCN_LANLEAVELI_REQUEST 3;
BA_ "GenSigSendType" SG_ 2463978855 DML_HMI_FCN_MALI_REQUEST 3;
BA_ "GenSigSendType" SG_ 2463978855 DML_HMI_FCN_ORLI_REQUEST 3;
BA_ "GenSigSendType" SG_ 2463978855 DML_HMI_FCN_RESALLEYHI_REQUEST 3;
BA_ "GenSigSendType" SG_ 2463978855 DML_HMI_FCN_ROADWORKLI_REQUEST 3;
BA_ "GenSigSendType" SG_ 2463978855 DML_HMI_FCN_SAFETYZONE_REQUEST 3;
BA_ "GenSigSendType" SG_ 2463978855 DML_HMI_FCN_TURNLIGHPR_REQUEST 3;
BA_ "GenSigSendType" SG_ 2463978855 DML_Indicator_Enabled 3;
BA_ "GenSigSwitchedByIgnition" SG_ 2463978855 DML_Indicator_Enabled 0;
BA_ "GenSigSendType" SG_ 2463978855 DML_IntelligentHB_Enabled 3;
BA_ "GenSigSwitchedByIgnition" SG_ 2463978855 DML_IntelligentHB_Enabled 0;
BA_ "GenSigSendType" SG_ 2463978855 DML_LaneDepartureWarn_Enabled 3;
BA_ "GenSigSwitchedByIgnition" SG_ 2463978855 DML_LaneDepartureWarn_Enabled 0;
BA_ "GenSigSendType" SG_ 2463978855 DML_LaneLight_Enabled 3;
BA_ "GenSigSwitchedByIgnition" SG_ 2463978855 DML_LaneLight_Enabled 0;
BA_ "GenSigSendType" SG_ 2463978855 DML_MarkingLight_Enabled 3;
BA_ "GenSigSwitchedByIgnition" SG_ 2463978855 DML_MarkingLight_Enabled 0;
BA_ "GenSigSendType" SG_ 2463978855 DML_OrientationLight_Enabled 3;
BA_ "GenSigSwitchedByIgnition" SG_ 2463978855 DML_OrientationLight_Enabled 0;
BA_ "GenSigSendType" SG_ 2463978855 DML_RescueLaneNotice_Enabled 3;
BA_ "GenSigSwitchedByIgnition" SG_ 2463978855 DML_RescueLaneNotice_Enabled 0;
BA_ "GenSigSendType" SG_ 2463978855 DML_SafetyZone_Enabled 3;
BA_ "GenSigSwitchedByIgnition" SG_ 2463978855 DML_SafetyZone_Enabled 0;
BA_ "GenSigSendType" SG_ 2463978855 DML_SaftyDistance_Enabled 3;
BA_ "GenSigSwitchedByIgnition" SG_ 2463978855 DML_SaftyDistance_Enabled 0;
BA_ "GenSigSendType" SG_ 2463978855 DML_SideAssist_Enabled 3;
BA_ "GenSigSwitchedByIgnition" SG_ 2463978855 DML_SideAssist_Enabled 0;
BA_ "GenSigSendType" SG_ 1635 BEM_Anf_KL15_schalten 0;
BA_ "GenSigSwitchedByIgnition" SG_ 1635 BEM_Anf_KL15_schalten 0;
BA_ "GenSigSendType" SG_ 1635 BEM_Batt_Ab 0;
BA_ "GenSigSwitchedByIgnition" SG_ 1635 BEM_Batt_Ab 0;
BA_ "GenSigSendType" SG_ 1635 BEM_Batteriediagnose 0;
BA_ "GenSigSwitchedByIgnition" SG_ 1635 BEM_Batteriediagnose 0;
BA_ "Fehlerwert" SG_ 1635 BEM_Batteriediagnose 7;
BA_ "GenSigSendType" SG_ 1635 BEM_DFM 0;
BA_ "GenSigSwitchedByIgnition" SG_ 1635 BEM_DFM 0;
BA_ "GenSigSendType" SG_ 1635 BEM_EMLIN_ungueltig 0;
BA_ "GenSigSwitchedByIgnition" SG_ 1635 BEM_EMLIN_ungueltig 0;
BA_ "GenSigSendType" SG_ 1635 BEM_Generatordiagnose 0;
BA_ "GenSigSwitchedByIgnition" SG_ 1635 BEM_Generatordiagnose 0;
BA_ "GenSigSendType" SG_ 1635 BEM_HL_Kontingentierung 0;
BA_ "GenSigSwitchedByIgnition" SG_ 1635 BEM_HL_Kontingentierung 0;
BA_ "GenSigSendType" SG_ 1635 BEM_HL_Regelung_Status 0;
BA_ "GenSigSwitchedByIgnition" SG_ 1635 BEM_HL_Regelung_Status 0;
BA_ "GenSigSendType" SG_ 1635 BEM_Ladezustand 0;
BA_ "GenSigStartValue" SG_ 1635 BEM_Ladezustand 14;
BA_ "GenSigSwitchedByIgnition" SG_ 1635 BEM_Ladezustand 0;
BA_ "Fehlerwert" SG_ 1635 BEM_Ladezustand 15;
BA_ "GenSigSendType" SG_ 1635 BEM_MMI_Vorwarnung 0;
BA_ "GenSigSwitchedByIgnition" SG_ 1635 BEM_MMI_Vorwarnung 0;
BA_ "GenSigSendType" SG_ 1635 BEM_Red_Innengeblaese 0;
BA_ "GenSigSwitchedByIgnition" SG_ 1635 BEM_Red_Innengeblaese 0;
BA_ "GenSigSendType" SG_ 1635 BEM_REK_aktiv 0;
BA_ "GenSigSwitchedByIgnition" SG_ 1635 BEM_REK_aktiv 0;
BA_ "GenSigSendType" SG_ 1635 BEM_STH_Einschaltverbot 0;
BA_ "GenSigSwitchedByIgnition" SG_ 1635 BEM_STH_Einschaltverbot 0;
BA_ "GenSigSendType" SG_ 1635 BEM_STH_Zielzeit 0;
BA_ "GenSigStartValue" SG_ 1635 BEM_STH_Zielzeit 14;
BA_ "GenSigSwitchedByIgnition" SG_ 1635 BEM_STH_Zielzeit 0;
BA_ "Fehlerwert" SG_ 1635 BEM_STH_Zielzeit 15;
BA_ "GenSigSendType" SG_ 1635 BEM_UBDM 0;
BA_ "GenSigSwitchedByIgnition" SG_ 1635 BEM_UBDM 0;
BA_ "Fehlerwert" SG_ 1635 BEM_UBDM 255;
BA_ "GenSigSendType" SG_ 1635 BEM_UGenSoll 0;
BA_ "GenSigSwitchedByIgnition" SG_ 1635 BEM_UGenSoll 0;
BA_ "GenSigSendType" SG_ 1635 MIB_Stromsparmodus 0;
BA_ "GenSigSwitchedByIgnition" SG_ 1635 MIB_Stromsparmodus 0;
BA_ "GenSigSendType" SG_ 1635 NVEM_Abschaltstufe 0;
BA_ "GenSigSwitchedByIgnition" SG_ 1635 NVEM_Abschaltstufe 0;
BA_ "GenSigSendType" SG_ 1635 NVEM_Anf_SD_schalten 0;
BA_ "GenSigSwitchedByIgnition" SG_ 1635 NVEM_Anf_SD_schalten 0;
BA_ "GenSigSendType" SG_ 1635 NVEM_Batterie_Service 0;
BA_ "GenSigSwitchedByIgnition" SG_ 1635 NVEM_Batterie_Service 0;
BA_ "GenSigSendType" SG_ 1635 NVEM_Freigabe_OnlineUpdate 0;
BA_ "GenSigSwitchedByIgnition" SG_ 1635 NVEM_Freigabe_OnlineUpdate 0;
BA_ "GenSigSendType" SG_ 1635 NVEM_Freigabe_ORU4 0;
BA_ "GenSigSwitchedByIgnition" SG_ 1635 NVEM_Freigabe_ORU4 0;
BA_ "GenSigSendType" SG_ 1635 NVEM_Freigabe_ZusBatt_Laden 0;
BA_ "GenSigSwitchedByIgnition" SG_ 1635 NVEM_Freigabe_ZusBatt_Laden 0;
BA_ "GenSigSendType" SG_ 1635 NVEM_Verbraucherabsch_Anz 0;
BA_ "GenSigSwitchedByIgnition" SG_ 1635 NVEM_Verbraucherabsch_Anz 0;
BA_ "GenSigSendType" SG_ 1163 BEM_06_BZ 0;
BA_ "GenSigFuncType" SG_ 1163 BEM_06_BZ 1;
BA_ "GenSigSwitchedByIgnition" SG_ 1163 BEM_06_BZ 0;
BA_ "GenSigSendType" SG_ 1163 BEM_06_CRC 0;
BA_ "GenSigFuncType" SG_ 1163 BEM_06_CRC 2;
BA_ "GenSigSwitchedByIgnition" SG_ 1163 BEM_06_CRC 0;
BA_ "GenSigSendType" SG_ 1163 HLR_PTC_linear_Freigabe 0;
BA_ "GenSigSwitchedByIgnition" SG_ 1163 HLR_PTC_linear_Freigabe 0;
BA_ "Fehlerwert" SG_ 1163 HLR_PTC_linear_Freigabe 63;
BA_ "GenSigSendType" SG_ 1163 NVEM2_Status_FuSiFahrt 0;
BA_ "GenSigSwitchedByIgnition" SG_ 1163 NVEM2_Status_FuSiFahrt 0;
BA_ "Fehlerwert" SG_ 1163 NVEM2_Status_FuSiFahrt 7;
BA_ "GenSigSendType" SG_ 1163 NVEM2_Typ_EnergieNetz 0;
BA_ "GenSigStartValue" SG_ 1163 NVEM2_Typ_EnergieNetz 15;
BA_ "GenSigSwitchedByIgnition" SG_ 1163 NVEM2_Typ_EnergieNetz 0;
BA_ "Fehlerwert" SG_ 1163 NVEM2_Typ_EnergieNetz 14;
BA_ "GenSigSendType" SG_ 1163 NVEM_Betriebsart 0;
BA_ "GenSigSwitchedByIgnition" SG_ 1163 NVEM_Betriebsart 0;
BA_ "Fehlerwert" SG_ 1163 NVEM_Betriebsart 15;
BA_ "GenSigSendType" SG_ 1163 NVEM_Bordnetzdiagnose 0;
BA_ "GenSigSwitchedByIgnition" SG_ 1163 NVEM_Bordnetzdiagnose 0;
BA_ "GenSigSendType" SG_ 1163 NVEM_Energie_Klima_Vorgabe 0;
BA_ "GenSigStartValue" SG_ 1163 NVEM_Energie_Klima_Vorgabe 254;
BA_ "GenSigSwitchedByIgnition" SG_ 1163 NVEM_Energie_Klima_Vorgabe 0;
BA_ "Fehlerwert" SG_ 1163 NVEM_Energie_Klima_Vorgabe 255;
BA_ "GenSigSendType" SG_ 1163 NVEM_Energienetz_Status 0;
BA_ "GenSigStartValue" SG_ 1163 NVEM_Energienetz_Status 6;
BA_ "GenSigSwitchedByIgnition" SG_ 1163 NVEM_Energienetz_Status 0;
BA_ "Fehlerwert" SG_ 1163 NVEM_Energienetz_Status 7;
BA_ "GenSigSendType" SG_ 1163 NVEM_Ladezustand 0;
BA_ "GenSigStartValue" SG_ 1163 NVEM_Ladezustand 126;
BA_ "GenSigSwitchedByIgnition" SG_ 1163 NVEM_Ladezustand 0;
BA_ "Fehlerwert" SG_ 1163 NVEM_Ladezustand 127;
BA_ "GenSigSendType" SG_ 1163 NVEM_Last_Anf 0;
BA_ "GenSigSwitchedByIgnition" SG_ 1163 NVEM_Last_Anf 0;
BA_ "GenSigSendType" SG_ 1163 NVEM_PTC_Sollstufe 0;
BA_ "GenSigSwitchedByIgnition" SG_ 1163 NVEM_PTC_Sollstufe 0;
BA_ "GenSigSendType" SG_ 1163 NVEM_Red_KomfortVerbrauch 0;
BA_ "GenSigSwitchedByIgnition" SG_ 1163 NVEM_Red_KomfortVerbrauch 0;
BA_ "Fehlerwert" SG_ 1163 NVEM_Red_KomfortVerbrauch 15;
BA_ "GenSigSendType" SG_ 1163 NVEM_STH_ZielzeitLang 0;
BA_ "GenSigStartValue" SG_ 1163 NVEM_STH_ZielzeitLang 14;
BA_ "GenSigSwitchedByIgnition" SG_ 1163 NVEM_STH_ZielzeitLang 0;
BA_ "Fehlerwert" SG_ 1163 NVEM_STH_ZielzeitLang 15;
BA_ "GenSigSendType" SG_ 1163 NVEM_Vorgabe_Leistungsstufe 0;
BA_ "GenSigSwitchedByIgnition" SG_ 1163 NVEM_Vorgabe_Leistungsstufe 0;
BA_ "Fehlerwert" SG_ 1163 NVEM_Vorgabe_Leistungsstufe 7;
BA_ "GenSigSendType" SG_ 2463978850 BEM_07_BZ 0;
BA_ "GenSigFuncType" SG_ 2463978850 BEM_07_BZ 1;
BA_ "GenSigSwitchedByIgnition" SG_ 2463978850 BEM_07_BZ 0;
BA_ "GenSigSendType" SG_ 2463978850 BEM_07_CRC 0;
BA_ "GenSigFuncType" SG_ 2463978850 BEM_07_CRC 2;
BA_ "GenSigSwitchedByIgnition" SG_ 2463978850 BEM_07_CRC 0;
BA_ "GenSigSendType" SG_ 2463978850 NVEM2_VerbrZustandsAnf 0;
BA_ "GenSigStartValue" SG_ 2463978850 NVEM2_VerbrZustandsAnf 14;
BA_ "GenSigSwitchedByIgnition" SG_ 2463978850 NVEM2_VerbrZustandsAnf 0;
BA_ "Fehlerwert" SG_ 2463978850 NVEM2_VerbrZustandsAnf 15;
BA_ "GenSigSendType" SG_ 2463978850 NVEM3_Absch_SCR 0;
BA_ "GenSigSwitchedByIgnition" SG_ 2463978850 NVEM3_Absch_SCR 0;
BA_ "GenSigSendType" SG_ 2463978850 NVEM_Batt_Temp_Hinweis 0;
BA_ "GenSigSwitchedByIgnition" SG_ 2463978850 NVEM_Batt_Temp_Hinweis 0;
BA_ "GenSigSendType" SG_ 2463978850 NVEM_Bordnetz_Information 0;
BA_ "GenSigStartValue" SG_ 2463978850 NVEM_Bordnetz_Information 14;
BA_ "GenSigSwitchedByIgnition" SG_ 2463978850 NVEM_Bordnetz_Information 0;
BA_ "Fehlerwert" SG_ 2463978850 NVEM_Bordnetz_Information 15;
BA_ "GenSigSendType" SG_ 2463978850 NVEM_NVStuetzungAnf 0;
BA_ "GenSigSwitchedByIgnition" SG_ 2463978850 NVEM_NVStuetzungAnf 0;
BA_ "Fehlerwert" SG_ 2463978850 NVEM_NVStuetzungAnf 3;
BA_ "GenSigSendType" SG_ 2463978850 NVEM_Verbraucher_Information 0;
BA_ "GenSigStartValue" SG_ 2463978850 NVEM_Verbraucher_Information 6;
BA_ "GenSigSwitchedByIgnition" SG_ 2463978850 NVEM_Verbraucher_Information 0;
BA_ "Fehlerwert" SG_ 2463978850 NVEM_Verbraucher_Information 7;
BA_ "GenSigSendType" SG_ 870 Blinken_li_Fzg_Takt 4;
BA_ "GenSigSwitchedByIgnition" SG_ 870 Blinken_li_Fzg_Takt 0;
BA_ "GenSigSendType" SG_ 870 Blinken_li_Kombi_Takt 4;
BA_ "GenSigSwitchedByIgnition" SG_ 870 Blinken_li_Kombi_Takt 0;
BA_ "GenSigSendType" SG_ 870 Blinken_re_Fzg_Takt 4;
BA_ "GenSigSwitchedByIgnition" SG_ 870 Blinken_re_Fzg_Takt 0;
BA_ "GenSigSendType" SG_ 870 Blinken_re_Kombi_Takt 4;
BA_ "GenSigSwitchedByIgnition" SG_ 870 Blinken_re_Kombi_Takt 0;
BA_ "GenSigSendType" SG_ 870 Blinkmodi_02_BZ 0;
BA_ "GenSigFuncType" SG_ 870 Blinkmodi_02_BZ 1;
BA_ "GenSigSwitchedByIgnition" SG_ 870 Blinkmodi_02_BZ 0;
BA_ "GenSigSendType" SG_ 870 Blinkmodi_02_CRC 0;
BA_ "GenSigFuncType" SG_ 870 Blinkmodi_02_CRC 2;
BA_ "GenSigSwitchedByIgnition" SG_ 870 Blinkmodi_02_CRC 0;
BA_ "GenSigSendType" SG_ 870 BM_Autobahn 4;
BA_ "GenSigSwitchedByIgnition" SG_ 870 BM_Autobahn 0;
BA_ "GenSigSendType" SG_ 870 BM_Crash 4;
BA_ "GenSigSwitchedByIgnition" SG_ 870 BM_Crash 0;
BA_ "GenSigSendType" SG_ 870 BM_DWA_Alarm 4;
BA_ "GenSigSwitchedByIgnition" SG_ 870 BM_DWA_Alarm 0;
BA_ "GenSigSendType" SG_ 870 BM_DWA_ein 4;
BA_ "GenSigSwitchedByIgnition" SG_ 870 BM_DWA_ein 0;
BA_ "GenSigSendType" SG_ 870 BM_GDO 4;
BA_ "GenSigSwitchedByIgnition" SG_ 870 BM_GDO 0;
BA_ "GenSigSendType" SG_ 870 BM_HD_Oeffnung_angelernt 3;
BA_ "GenSigSwitchedByIgnition" SG_ 870 BM_HD_Oeffnung_angelernt 0;
BA_ "GenSigSendType" SG_ 870 BM_links 4;
BA_ "GenSigSwitchedByIgnition" SG_ 870 BM_links 0;
BA_ "GenSigSendType" SG_ 870 BM_NBA_n_codiert_n_aktiv 3;
BA_ "GenSigStartValue" SG_ 870 BM_NBA_n_codiert_n_aktiv 1;
BA_ "GenSigSwitchedByIgnition" SG_ 870 BM_NBA_n_codiert_n_aktiv 0;
BA_ "GenSigSendType" SG_ 870 BM_NBA_Status 4;
BA_ "GenSigSwitchedByIgnition" SG_ 870 BM_NBA_Status 0;
BA_ "GenSigSendType" SG_ 870 BM_Not_Bremsung 4;
BA_ "GenSigSwitchedByIgnition" SG_ 870 BM_Not_Bremsung 0;
BA_ "GenSigSendType" SG_ 870 BM_Panik 4;
BA_ "GenSigSwitchedByIgnition" SG_ 870 BM_Panik 0;
BA_ "GenSigSendType" SG_ 870 BM_PiloPa 4;
BA_ "GenSigSwitchedByIgnition" SG_ 870 BM_PiloPa 0;
BA_ "GenSigSendType" SG_ 870 BM_Recas 5;
BA_ "GenSigSwitchedByIgnition" SG_ 870 BM_Recas 0;
BA_ "GenSigSendType" SG_ 870 BM_rechts 4;
BA_ "GenSigSwitchedByIgnition" SG_ 870 BM_rechts 0;
BA_ "GenSigSendType" SG_ 870 BM_Rollenmodus_Blinken 5;
BA_ "GenSigSwitchedByIgnition" SG_ 870 BM_Rollenmodus_Blinken 0;
BA_ "GenSigSendType" SG_ 870 BM_Taxi_Notalarm 4;
BA_ "GenSigSwitchedByIgnition" SG_ 870 BM_Taxi_Notalarm 0;
BA_ "GenSigSendType" SG_ 870 BM_Telematik 4;
BA_ "GenSigSwitchedByIgnition" SG_ 870 BM_Telematik 0;
BA_ "GenSigSendType" SG_ 870 BM_Telematik_Abbruchgrund 4;
BA_ "GenSigSwitchedByIgnition" SG_ 870 BM_Telematik_Abbruchgrund 0;
BA_ "GenSigSendType" SG_ 870 BM_Warnblinken 4;
BA_ "GenSigSwitchedByIgnition" SG_ 870 BM_Warnblinken 0;
BA_ "GenSigSendType" SG_ 870 BM_WBA_Warnblinken 4;
BA_ "GenSigSwitchedByIgnition" SG_ 870 BM_WBA_Warnblinken 0;
BA_ "GenSigSendType" SG_ 870 BM_WBT_Beleuchtung 3;
BA_ "GenSigSwitchedByIgnition" SG_ 870 BM_WBT_Beleuchtung 0;
BA_ "GenSigSendType" SG_ 870 BM_Wischblinken 4;
BA_ "GenSigSwitchedByIgnition" SG_ 870 BM_Wischblinken 0;
BA_ "GenSigSendType" SG_ 870 BM_ZV_auf 4;
BA_ "GenSigSwitchedByIgnition" SG_ 870 BM_ZV_auf 0;
BA_ "GenSigSendType" SG_ 870 BM_ZV_zu 4;
BA_ "GenSigSwitchedByIgnition" SG_ 870 BM_ZV_zu 0;
BA_ "GenSigSendType" SG_ 870 SAL_RHP_Blinken_Status 3;
BA_ "GenSigSwitchedByIgnition" SG_ 870 SAL_RHP_Blinken_Status 0;
BA_ "GenSigSendType" SG_ 870 SAL_RHP_Warnblinken 3;
BA_ "GenSigSwitchedByIgnition" SG_ 870 SAL_RHP_Warnblinken 0;
BA_ "GenSigSendType" SG_ 870 SAL_TA_Blinken_Status 4;
BA_ "GenSigSwitchedByIgnition" SG_ 870 SAL_TA_Blinken_Status 0;
BA_ "GenSigSendType" SG_ 1482 BMS_07_BZ 0;
BA_ "GenSigFuncType" SG_ 1482 BMS_07_BZ 1;
BA_ "GenSigSwitchedByIgnition" SG_ 1482 BMS_07_BZ 0;
BA_ "GenSigSendType" SG_ 1482 BMS_07_CRC 0;
BA_ "GenSigFuncType" SG_ 1482 BMS_07_CRC 2;
BA_ "GenSigSwitchedByIgnition" SG_ 1482 BMS_07_CRC 0;
BA_ "GenSigSendType" SG_ 1482 BMS_Ausgleichsladung_Anf 0;
BA_ "GenSigSwitchedByIgnition" SG_ 1482 BMS_Ausgleichsladung_Anf 0;
BA_ "GenSigSendType" SG_ 1482 BMS_Balancing_Aktiv 0;
BA_ "GenSigSwitchedByIgnition" SG_ 1482 BMS_Balancing_Aktiv 0;
BA_ "GenSigSendType" SG_ 1482 BMS_Batteriediagnose 3;
BA_ "GenSigStartValue" SG_ 1482 BMS_Batteriediagnose 1;
BA_ "GenSigSwitchedByIgnition" SG_ 1482 BMS_Batteriediagnose 0;
BA_ "Fehlerwert" SG_ 1482 BMS_Batteriediagnose 7;
BA_ "GenSigSendType" SG_ 1482 BMS_Energieinhalt 0;
BA_ "GenSigStartValue" SG_ 1482 BMS_Energieinhalt 2046;
BA_ "GenSigSwitchedByIgnition" SG_ 1482 BMS_Energieinhalt 0;
BA_ "Fehlerwert" SG_ 1482 BMS_Energieinhalt 2047;
BA_ "GenSigSendType" SG_ 1482 BMS_Gesamtst_Spgfreiheit 3;
BA_ "GenSigSwitchedByIgnition" SG_ 1482 BMS_Gesamtst_Spgfreiheit 0;
BA_ "GenSigSendType" SG_ 1482 BMS_KundenWarnung 3;
BA_ "GenSigSwitchedByIgnition" SG_ 1482 BMS_KundenWarnung 0;
BA_ "GenSigSendType" SG_ 1482 BMS_Ladevorgang_aktiv 0;
BA_ "GenSigSwitchedByIgnition" SG_ 1482 BMS_Ladevorgang_aktiv 0;
BA_ "GenSigSendType" SG_ 1482 BMS_MaxEnergieinhalt 0;
BA_ "GenSigStartValue" SG_ 1482 BMS_MaxEnergieinhalt 2046;
BA_ "GenSigSwitchedByIgnition" SG_ 1482 BMS_MaxEnergieinhalt 0;
BA_ "Fehlerwert" SG_ 1482 BMS_MaxEnergieinhalt 2047;
BA_ "GenSigSendType" SG_ 1482 BMS_RIso_Ext 0;
BA_ "GenSigStartValue" SG_ 1482 BMS_RIso_Ext 4094;
BA_ "GenSigSwitchedByIgnition" SG_ 1482 BMS_RIso_Ext 0;
BA_ "Fehlerwert" SG_ 1482 BMS_RIso_Ext 4095;
BA_ "GenSigSendType" SG_ 2331596015 BSIS_Anzeigen_links 3;
BA_ "GenSigSendType" SG_ 2331596015 BSIS_LED_Ausgabemodus_links 4;
BA_ "GenSigSendType" SG_ 2331596015 BSIS_LED_Hell_links 0;
BA_ "GenSigStartValue" SG_ 2331596015 BSIS_LED_Hell_links 126;
BA_ "Fehlerwert" SG_ 2331596015 BSIS_LED_Hell_links 127;
BA_ "GenSigSendType" SG_ 2331596016 BSIS_Anzeigen_rechts 3;
BA_ "GenSigSendType" SG_ 2331596016 BSIS_LED_Ausgabemodus_rechts 4;
BA_ "GenSigSendType" SG_ 2331596016 BSIS_LED_Hell_rechts 0;
BA_ "GenSigStartValue" SG_ 2331596016 BSIS_LED_Hell_rechts 126;
BA_ "Fehlerwert" SG_ 2331596016 BSIS_LED_Hell_rechts 127;
BA_ "GenSigSendType" SG_ 2463978792 CentralLocking_01_BZ 0;
BA_ "GenSigFuncType" SG_ 2463978792 CentralLocking_01_BZ 1;
BA_ "GenSigSwitchedByIgnition" SG_ 2463978792 CentralLocking_01_BZ 0;
BA_ "GenSigSendType" SG_ 2463978792 CentralLocking_01_CRC 0;
BA_ "GenSigFuncType" SG_ 2463978792 CentralLocking_01_CRC 2;
BA_ "GenSigSwitchedByIgnition" SG_ 2463978792 CentralLocking_01_CRC 0;
BA_ "GenSigSendType" SG_ 2463978792 DWA_aktiv 3;
BA_ "GenSigSwitchedByIgnition" SG_ 2463978792 DWA_aktiv 0;
BA_ "GenSigSendType" SG_ 2463978792 IRUE_Taster_Fkts_LED 3;
BA_ "GenSigSwitchedByIgnition" SG_ 2463978792 IRUE_Taster_Fkts_LED 0;
BA_ "GenSigSendType" SG_ 2463978792 SOK_CentralLocking_01_Signatur 0;
BA_ "GenSigFuncType" SG_ 2463978792 SOK_CentralLocking_01_Signatur 15;
BA_ "GenSigSwitchedByIgnition" SG_ 2463978792 SOK_CentralLocking_01_Signatur 0;
BA_ "GenSigSendType" SG_ 2463978792 ZV_auto_Ansteuerung 9;
BA_ "GenSigSwitchedByIgnition" SG_ 2463978792 ZV_auto_Ansteuerung 0;
BA_ "GenSigSendType" SG_ 2463978792 ZV_Bedienstelle_auf 9;
BA_ "GenSigSwitchedByIgnition" SG_ 2463978792 ZV_Bedienstelle_auf 0;
BA_ "GenSigSendType" SG_ 2463978792 ZV_Bedienstelle_zu 9;
BA_ "GenSigSwitchedByIgnition" SG_ 2463978792 ZV_Bedienstelle_zu 0;
BA_ "GenSigSendType" SG_ 2463978792 ZV_BT_entriegeln 9;
BA_ "GenSigSwitchedByIgnition" SG_ 2463978792 ZV_BT_entriegeln 0;
BA_ "GenSigSendType" SG_ 2463978792 ZV_BT_verriegeln 9;
BA_ "GenSigSwitchedByIgnition" SG_ 2463978792 ZV_BT_verriegeln 0;
BA_ "GenSigSendType" SG_ 2463978792 ZV_Crashfall_erkannt 9;
BA_ "GenSigSwitchedByIgnition" SG_ 2463978792 ZV_Crashfall_erkannt 0;
BA_ "GenSigSendType" SG_ 2463978792 ZV_Frontschloss_Vorraste 4;
BA_ "GenSigStartValue" SG_ 2463978792 ZV_Frontschloss_Vorraste 2;
BA_ "GenSigSwitchedByIgnition" SG_ 2463978792 ZV_Frontschloss_Vorraste 0;
BA_ "Fehlerwert" SG_ 2463978792 ZV_Frontschloss_Vorraste 3;
BA_ "GenSigSendType" SG_ 2463978792 ZV_FT_entriegeln 9;
BA_ "GenSigSwitchedByIgnition" SG_ 2463978792 ZV_FT_entriegeln 0;
BA_ "GenSigSendType" SG_ 2463978792 ZV_FT_verriegeln 9;
BA_ "GenSigSwitchedByIgnition" SG_ 2463978792 ZV_FT_verriegeln 0;
BA_ "GenSigSendType" SG_ 2463978792 ZV_gesafet_extern_ist_02 4;
BA_ "GenSigStartValue" SG_ 2463978792 ZV_gesafet_extern_ist_02 2;
BA_ "GenSigSwitchedByIgnition" SG_ 2463978792 ZV_gesafet_extern_ist_02 0;
BA_ "Fehlerwert" SG_ 2463978792 ZV_gesafet_extern_ist_02 3;
BA_ "GenSigSendType" SG_ 2463978792 ZV_gesafet_extern_soll_02 4;
BA_ "GenSigStartValue" SG_ 2463978792 ZV_gesafet_extern_soll_02 2;
BA_ "GenSigSwitchedByIgnition" SG_ 2463978792 ZV_gesafet_extern_soll_02 0;
BA_ "Fehlerwert" SG_ 2463978792 ZV_gesafet_extern_soll_02 3;
BA_ "GenSigSendType" SG_ 2463978792 ZV_HBFS_entriegeln 9;
BA_ "GenSigSwitchedByIgnition" SG_ 2463978792 ZV_HBFS_entriegeln 0;
BA_ "GenSigSendType" SG_ 2463978792 ZV_HBFS_verriegeln 9;
BA_ "GenSigSwitchedByIgnition" SG_ 2463978792 ZV_HBFS_verriegeln 0;
BA_ "GenSigSendType" SG_ 2463978792 ZV_HFS_entriegeln 9;
BA_ "GenSigSwitchedByIgnition" SG_ 2463978792 ZV_HFS_entriegeln 0;
BA_ "GenSigSendType" SG_ 2463978792 ZV_HFS_verriegeln 9;
BA_ "GenSigSwitchedByIgnition" SG_ 2463978792 ZV_HFS_verriegeln 0;
BA_ "GenSigSendType" SG_ 2463978792 ZV_LED_Steuerung 9;
BA_ "GenSigSwitchedByIgnition" SG_ 2463978792 ZV_LED_Steuerung 0;
BA_ "GenSigSendType" SG_ 2463978792 ZV_LED_Uebernahme 9;
BA_ "GenSigSwitchedByIgnition" SG_ 2463978792 ZV_LED_Uebernahme 0;
BA_ "GenSigSendType" SG_ 2463978792 ZV_Schluessel_Zugang 4;
BA_ "GenSigSwitchedByIgnition" SG_ 2463978792 ZV_Schluessel_Zugang 0;
BA_ "GenSigSendType" SG_ 2463978792 ZV_Signatur 9;
BA_ "GenSigSwitchedByIgnition" SG_ 2463978792 ZV_Signatur 0;
BA_ "GenSigSendType" SG_ 2463978792 ZV_Spg_Anklappen 9;
BA_ "GenSigSwitchedByIgnition" SG_ 2463978792 ZV_Spg_Anklappen 0;
BA_ "GenSigSendType" SG_ 2463978792 ZV_Status_eTAG_ist 3;
BA_ "GenSigSwitchedByIgnition" SG_ 2463978792 ZV_Status_eTAG_ist 0;
BA_ "GenSigSendType" SG_ 2463978792 ZV_Status_eTAG_soll 3;
BA_ "GenSigSwitchedByIgnition" SG_ 2463978792 ZV_Status_eTAG_soll 0;
BA_ "GenSigSendType" SG_ 2463978792 ZV_TAG_BT_verfahren 9;
BA_ "GenSigSwitchedByIgnition" SG_ 2463978792 ZV_TAG_BT_verfahren 0;
BA_ "GenSigSendType" SG_ 2463978792 ZV_TAG_FT_verfahren 9;
BA_ "GenSigSwitchedByIgnition" SG_ 2463978792 ZV_TAG_FT_verfahren 0;
BA_ "Fehlerwert" SG_ 2463978792 ZV_TAG_FT_verfahren 3;
BA_ "GenSigSendType" SG_ 2463978792 ZV_TAG_HBFS_verfahren 9;
BA_ "GenSigSwitchedByIgnition" SG_ 2463978792 ZV_TAG_HBFS_verfahren 0;
BA_ "GenSigSendType" SG_ 2463978792 ZV_TAG_HFS_verfahren 9;
BA_ "GenSigSwitchedByIgnition" SG_ 2463978792 ZV_TAG_HFS_verfahren 0;
BA_ "GenSigSendType" SG_ 2463978792 ZV_verriegelt_extern_ist_02 3;
BA_ "GenSigStartValue" SG_ 2463978792 ZV_verriegelt_extern_ist_02 2;
BA_ "GenSigSwitchedByIgnition" SG_ 2463978792 ZV_verriegelt_extern_ist_02 0;
BA_ "Fehlerwert" SG_ 2463978792 ZV_verriegelt_extern_ist_02 3;
BA_ "GenSigSendType" SG_ 2463978792 ZV_verriegelt_extern_soll_03 4;
BA_ "GenSigStartValue" SG_ 2463978792 ZV_verriegelt_extern_soll_03 2;
BA_ "GenSigSwitchedByIgnition" SG_ 2463978792 ZV_verriegelt_extern_soll_03 0;
BA_ "Fehlerwert" SG_ 2463978792 ZV_verriegelt_extern_soll_03 3;
BA_ "GenSigSendType" SG_ 2463978792 ZV_verriegelt_intern_ist_02 4;
BA_ "GenSigStartValue" SG_ 2463978792 ZV_verriegelt_intern_ist_02 2;
BA_ "GenSigSwitchedByIgnition" SG_ 2463978792 ZV_verriegelt_intern_ist_02 0;
BA_ "Fehlerwert" SG_ 2463978792 ZV_verriegelt_intern_ist_02 3;
BA_ "GenSigSendType" SG_ 2463978792 ZV_verriegelt_intern_soll_02 4;
BA_ "GenSigStartValue" SG_ 2463978792 ZV_verriegelt_intern_soll_02 2;
BA_ "GenSigSwitchedByIgnition" SG_ 2463978792 ZV_verriegelt_intern_soll_02 0;
BA_ "Fehlerwert" SG_ 2463978792 ZV_verriegelt_intern_soll_02 3;
BA_ "GenSigSendType" SG_ 2463978792 ZV_zentral_entsafen 9;
BA_ "GenSigSwitchedByIgnition" SG_ 2463978792 ZV_zentral_entsafen 0;
BA_ "GenSigSendType" SG_ 2463978792 ZV_zentral_safen 9;
BA_ "GenSigSwitchedByIgnition" SG_ 2463978792 ZV_zentral_safen 0;
BA_ "GenSigSendType" SG_ 2463978792 ZV_zu_Zeitl_Nachverr 9;
BA_ "GenSigSwitchedByIgnition" SG_ 2463978792 ZV_zu_Zeitl_Nachverr 0;
BA_ "GenSigSendType" SG_ 902 CHA_Charge_LED 3;
BA_ "GenSigSwitchedByIgnition" SG_ 902 CHA_Charge_LED 0;
BA_ "GenSigSendType" SG_ 902 CHA_Charisma_Taste2_LED 3;
BA_ "GenSigSwitchedByIgnition" SG_ 902 CHA_Charisma_Taste2_LED 0;
BA_ "Fehlerwert" SG_ 902 CHA_Charisma_Taste2_LED 3;
BA_ "GenSigSendType" SG_ 902 CHA_Current_Mode 3;
BA_ "GenSigSwitchedByIgnition" SG_ 902 CHA_Current_Mode 0;
BA_ "GenSigSendType" SG_ 902 CHA_Current_Mode_FPA 3;
BA_ "GenSigSwitchedByIgnition" SG_ 902 CHA_Current_Mode_FPA 0;
BA_ "GenSigSendType" SG_ 902 CHA_Eco_Charisma_LED 3;
BA_ "GenSigSwitchedByIgnition" SG_ 902 CHA_Eco_Charisma_LED 0;
BA_ "GenSigSendType" SG_ 902 CHA_EV_LED 3;
BA_ "GenSigSwitchedByIgnition" SG_ 902 CHA_EV_LED 0;
BA_ "GenSigSendType" SG_ 902 CHA_Fahrer_Umschaltung 3;
BA_ "GenSigSwitchedByIgnition" SG_ 902 CHA_Fahrer_Umschaltung 0;
BA_ "GenSigSendType" SG_ 902 CHA_Kombi_Texte 3;
BA_ "GenSigSwitchedByIgnition" SG_ 902 CHA_Kombi_Texte 0;
BA_ "GenSigSendType" SG_ 902 CHA_Kombi_Texte_02 3;
BA_ "GenSigSwitchedByIgnition" SG_ 902 CHA_Kombi_Texte_02 0;
BA_ "GenSigSendType" SG_ 902 CHA_Offroad_LED 3;
BA_ "GenSigSwitchedByIgnition" SG_ 902 CHA_Offroad_LED 0;
BA_ "Fehlerwert" SG_ 902 CHA_Offroad_LED 3;
BA_ "GenSigSendType" SG_ 902 CHA_ReqPrgDispSetup 3;
BA_ "GenSigSwitchedByIgnition" SG_ 902 CHA_ReqPrgDispSetup 0;
BA_ "GenSigSendType" SG_ 902 CHA_StCurProfDft 3;
BA_ "GenSigSwitchedByIgnition" SG_ 902 CHA_StCurProfDft 0;
BA_ "GenSigSendType" SG_ 902 CHA_Ziel_FahrPr_03_01 3;
BA_ "GenSigSwitchedByIgnition" SG_ 902 CHA_Ziel_FahrPr_03_01 0;
BA_ "GenSigSendType" SG_ 902 CHA_Ziel_FahrPr_03_02 3;
BA_ "GenSigSwitchedByIgnition" SG_ 902 CHA_Ziel_FahrPr_03_02 0;
BA_ "GenSigSendType" SG_ 902 CHA_Ziel_FahrPr_AMB 3;
BA_ "GenSigSwitchedByIgnition" SG_ 902 CHA_Ziel_FahrPr_AMB 0;
BA_ "GenSigSendType" SG_ 902 CHA_Ziel_FahrPr_HSP 3;
BA_ "GenSigSwitchedByIgnition" SG_ 902 CHA_Ziel_FahrPr_HSP 0;
BA_ "GenSigSendType" SG_ 902 CHA_Ziel_FahrPr_IVB 3;
BA_ "GenSigSwitchedByIgnition" SG_ 902 CHA_Ziel_FahrPr_IVB 0;
BA_ "GenSigSendType" SG_ 902 CHA_Ziel_FahrPr_KL 3;
BA_ "GenSigSwitchedByIgnition" SG_ 902 CHA_Ziel_FahrPr_KL 0;
BA_ "GenSigSendType" SG_ 902 CHA_Ziel_FahrPr_RWB 3;
BA_ "GenSigSwitchedByIgnition" SG_ 902 CHA_Ziel_FahrPr_RWB 0;
BA_ "GenSigSendType" SG_ 2463978646 CHA_Current_Mode 3;
BA_ "GenSigSwitchedByIgnition" SG_ 2463978646 CHA_Current_Mode 0;
BA_ "GenSigSendType" SG_ 2463978646 CHA_Fahrer_Umschaltung 3;
BA_ "GenSigSwitchedByIgnition" SG_ 2463978646 CHA_Fahrer_Umschaltung 0;
BA_ "GenSigSendType" SG_ 2463978646 CHA_Fahrer_Umschaltung_BMA 3;
BA_ "GenSigSwitchedByIgnition" SG_ 2463978646 CHA_Fahrer_Umschaltung_BMA 0;
BA_ "GenSigSendType" SG_ 2463978646 CHA_Ziel_FahrPr_ACC 3;
BA_ "GenSigSwitchedByIgnition" SG_ 2463978646 CHA_Ziel_FahrPr_ACC 0;
BA_ "GenSigSendType" SG_ 2463978646 CHA_Ziel_FahrPr_AEB 3;
BA_ "GenSigSwitchedByIgnition" SG_ 2463978646 CHA_Ziel_FahrPr_AEB 0;
BA_ "GenSigSendType" SG_ 2463978646 CHA_Ziel_FahrPr_AFR 3;
BA_ "GenSigSwitchedByIgnition" SG_ 2463978646 CHA_Ziel_FahrPr_AFR 0;
BA_ "GenSigSendType" SG_ 2463978646 CHA_Ziel_FahrPr_AFS 3;
BA_ "GenSigSwitchedByIgnition" SG_ 2463978646 CHA_Ziel_FahrPr_AFS 0;
BA_ "GenSigSendType" SG_ 2463978646 CHA_Ziel_FahrPr_AGA 3;
BA_ "GenSigSwitchedByIgnition" SG_ 2463978646 CHA_Ziel_FahrPr_AGA 0;
BA_ "GenSigSendType" SG_ 2463978646 CHA_Ziel_FahrPr_AGK 3;
BA_ "GenSigSwitchedByIgnition" SG_ 2463978646 CHA_Ziel_FahrPr_AGK 0;
BA_ "GenSigSendType" SG_ 2463978646 CHA_Ziel_FahrPr_ALR 3;
BA_ "GenSigSwitchedByIgnition" SG_ 2463978646 CHA_Ziel_FahrPr_ALR 0;
BA_ "GenSigSendType" SG_ 2463978646 CHA_Ziel_FahrPr_AV 3;
BA_ "GenSigSwitchedByIgnition" SG_ 2463978646 CHA_Ziel_FahrPr_AV 0;
BA_ "GenSigSendType" SG_ 2463978646 CHA_Ziel_FahrPr_BMS 3;
BA_ "GenSigSwitchedByIgnition" SG_ 2463978646 CHA_Ziel_FahrPr_BMS 0;
BA_ "GenSigSendType" SG_ 2463978646 CHA_Ziel_FahrPr_DR 3;
BA_ "GenSigSwitchedByIgnition" SG_ 2463978646 CHA_Ziel_FahrPr_DR 0;
BA_ "GenSigSendType" SG_ 2463978646 CHA_Ziel_FahrPr_EAR 3;
BA_ "GenSigSwitchedByIgnition" SG_ 2463978646 CHA_Ziel_FahrPr_EAR 0;
BA_ "GenSigSendType" SG_ 2463978646 CHA_Ziel_FahrPr_EBKV 3;
BA_ "GenSigSwitchedByIgnition" SG_ 2463978646 CHA_Ziel_FahrPr_EBKV 0;
BA_ "GenSigSendType" SG_ 2463978646 CHA_Ziel_FahrPr_EDS 3;
BA_ "GenSigSwitchedByIgnition" SG_ 2463978646 CHA_Ziel_FahrPr_EDS 0;
BA_ "GenSigSendType" SG_ 2463978646 CHA_Ziel_FahrPr_EPS 3;
BA_ "GenSigSwitchedByIgnition" SG_ 2463978646 CHA_Ziel_FahrPr_EPS 0;
BA_ "GenSigSendType" SG_ 2463978646 CHA_Ziel_FahrPr_eSound 3;
BA_ "GenSigSwitchedByIgnition" SG_ 2463978646 CHA_Ziel_FahrPr_eSound 0;
BA_ "GenSigSendType" SG_ 2463978646 CHA_Ziel_FahrPr_ESP 3;
BA_ "GenSigSwitchedByIgnition" SG_ 2463978646 CHA_Ziel_FahrPr_ESP 0;
BA_ "GenSigSendType" SG_ 2463978646 CHA_Ziel_FahrPr_FCWO 3;
BA_ "GenSigSwitchedByIgnition" SG_ 2463978646 CHA_Ziel_FahrPr_FCWO 0;
BA_ "GenSigSendType" SG_ 2463978646 CHA_Ziel_FahrPr_FCWP 3;
BA_ "GenSigSwitchedByIgnition" SG_ 2463978646 CHA_Ziel_FahrPr_FCWP 0;
BA_ "GenSigSendType" SG_ 2463978646 CHA_Ziel_FahrPr_Freilauf 3;
BA_ "GenSigSwitchedByIgnition" SG_ 2463978646 CHA_Ziel_FahrPr_Freilauf 0;
BA_ "GenSigSendType" SG_ 2463978646 CHA_Ziel_FahrPr_GE 3;
BA_ "GenSigSwitchedByIgnition" SG_ 2463978646 CHA_Ziel_FahrPr_GE 0;
BA_ "GenSigSendType" SG_ 2463978646 CHA_Ziel_FahrPr_HAL 3;
BA_ "GenSigSwitchedByIgnition" SG_ 2463978646 CHA_Ziel_FahrPr_HAL 0;
BA_ "GenSigSendType" SG_ 2463978646 CHA_Ziel_FahrPr_HDC 3;
BA_ "GenSigSwitchedByIgnition" SG_ 2463978646 CHA_Ziel_FahrPr_HDC 0;
BA_ "GenSigSendType" SG_ 2463978646 CHA_Ziel_FahrPr_HHC 3;
BA_ "GenSigSwitchedByIgnition" SG_ 2463978646 CHA_Ziel_FahrPr_HHC 0;
BA_ "GenSigSendType" SG_ 2463978646 CHA_Ziel_FahrPr_IL 3;
BA_ "GenSigSwitchedByIgnition" SG_ 2463978646 CHA_Ziel_FahrPr_IL 0;
BA_ "GenSigSendType" SG_ 2463978646 CHA_Ziel_FahrPr_mFDR 3;
BA_ "GenSigSwitchedByIgnition" SG_ 2463978646 CHA_Ziel_FahrPr_mFDR 0;
BA_ "GenSigSendType" SG_ 2463978646 CHA_Ziel_FahrPr_MO 3;
BA_ "GenSigSwitchedByIgnition" SG_ 2463978646 CHA_Ziel_FahrPr_MO 0;
BA_ "GenSigSendType" SG_ 2463978646 CHA_Ziel_FahrPr_MO_BZS 3;
BA_ "GenSigSwitchedByIgnition" SG_ 2463978646 CHA_Ziel_FahrPr_MO_BZS 0;
BA_ "GenSigSendType" SG_ 2463978646 CHA_Ziel_FahrPr_MO_Freilauf 3;
BA_ "GenSigSwitchedByIgnition" SG_ 2463978646 CHA_Ziel_FahrPr_MO_Freilauf 0;
BA_ "GenSigSendType" SG_ 2463978646 CHA_Ziel_FahrPr_MO_StSt 3;
BA_ "GenSigSwitchedByIgnition" SG_ 2463978646 CHA_Ziel_FahrPr_MO_StSt 0;
BA_ "GenSigSendType" SG_ 2463978646 CHA_Ziel_FahrPr_MXB 3;
BA_ "GenSigSwitchedByIgnition" SG_ 2463978646 CHA_Ziel_FahrPr_MXB 0;
BA_ "GenSigSendType" SG_ 2463978646 CHA_Ziel_FahrPr_NR 3;
BA_ "GenSigSwitchedByIgnition" SG_ 2463978646 CHA_Ziel_FahrPr_NR 0;
BA_ "GenSigSendType" SG_ 2463978646 CHA_Ziel_FahrPr_PACC 3;
BA_ "GenSigSwitchedByIgnition" SG_ 2463978646 CHA_Ziel_FahrPr_PACC 0;
BA_ "GenSigSendType" SG_ 2463978646 CHA_Ziel_FahrPr_PDC 3;
BA_ "GenSigSwitchedByIgnition" SG_ 2463978646 CHA_Ziel_FahrPr_PDC 0;
BA_ "GenSigSendType" SG_ 2463978646 CHA_Ziel_FahrPr_PreCrash 3;
BA_ "GenSigSwitchedByIgnition" SG_ 2463978646 CHA_Ziel_FahrPr_PreCrash 0;
BA_ "GenSigSendType" SG_ 2463978646 CHA_Ziel_FahrPr_QS 3;
BA_ "GenSigSwitchedByIgnition" SG_ 2463978646 CHA_Ziel_FahrPr_QS 0;
BA_ "GenSigSendType" SG_ 2463978646 CHA_Ziel_FahrPr_Reku_ZwGas 3;
BA_ "GenSigSwitchedByIgnition" SG_ 2463978646 CHA_Ziel_FahrPr_Reku_ZwGas 0;
BA_ "GenSigSendType" SG_ 2463978646 CHA_Ziel_FahrPr_RHP 3;
BA_ "GenSigSwitchedByIgnition" SG_ 2463978646 CHA_Ziel_FahrPr_RHP 0;
BA_ "GenSigSendType" SG_ 2463978646 CHA_Ziel_FahrPr_SAK 3;
BA_ "GenSigSwitchedByIgnition" SG_ 2463978646 CHA_Ziel_FahrPr_SAK 0;
BA_ "GenSigSendType" SG_ 2463978646 CHA_Ziel_FahrPr_SCU 3;
BA_ "GenSigSwitchedByIgnition" SG_ 2463978646 CHA_Ziel_FahrPr_SCU 0;
BA_ "GenSigSendType" SG_ 2463978646 CHA_Ziel_FahrPr_ToS_laengs 3;
BA_ "GenSigSwitchedByIgnition" SG_ 2463978646 CHA_Ziel_FahrPr_ToS_laengs 0;
BA_ "GenSigSendType" SG_ 2463978646 CHA_Ziel_FahrPr_ToS_quer 3;
BA_ "GenSigSwitchedByIgnition" SG_ 2463978646 CHA_Ziel_FahrPr_ToS_quer 0;
BA_ "GenSigSendType" SG_ 2463978646 CHA_Ziel_FahrPr_VAQ 3;
BA_ "GenSigSwitchedByIgnition" SG_ 2463978646 CHA_Ziel_FahrPr_VAQ 0;
BA_ "GenSigSendType" SG_ 2527679921 CPD_CallCenter 3;
BA_ "GenSigSwitchedByIgnition" SG_ 2527679921 CPD_CallCenter 0;
BA_ "GenSigSendType" SG_ 2527679921 CPD_Deaktivierung_Permanent 3;
BA_ "GenSigSwitchedByIgnition" SG_ 2527679921 CPD_Deaktivierung_Permanent 0;
BA_ "GenSigSendType" SG_ 2527679921 CPD_Deaktivierung_Temp 3;
BA_ "GenSigSwitchedByIgnition" SG_ 2527679921 CPD_Deaktivierung_Temp 0;
BA_ "GenSigSendType" SG_ 2527679921 CPD_Mobiltelefon_BLE 3;
BA_ "GenSigSwitchedByIgnition" SG_ 2527679921 CPD_Mobiltelefon_BLE 0;
BA_ "GenSigSendType" SG_ 2527679921 CPD_Mobiltelefon_GSM 3;
BA_ "GenSigSwitchedByIgnition" SG_ 2527679921 CPD_Mobiltelefon_GSM 0;
BA_ "GenSigSendType" SG_ 2527679921 CPDFct_Deakt 3;
BA_ "GenSigSwitchedByIgnition" SG_ 2527679921 CPDFct_Deakt 0;
BA_ "GenSigSendType" SG_ 2527679921 CPDFct_Symbol 0;
BA_ "GenSigSwitchedByIgnition" SG_ 2527679921 CPDFct_Symbol 0;
BA_ "GenSigSendType" SG_ 2527679921 CPDFct_Warnung 0;
BA_ "GenSigSwitchedByIgnition" SG_ 2527679921 CPDFct_Warnung 0;
BA_ "GenSigSendType" SG_ 2331595987 CPD_Sensierung_Status 3;
BA_ "GenSigSwitchedByIgnition" SG_ 2331595987 CPD_Sensierung_Status 0;
BA_ "Fehlerwert" SG_ 2331595987 CPD_Sensierung_Status 7;
BA_ "GenSigSendType" SG_ 2331595987 CPD_Warnstufe 3;
BA_ "GenSigSwitchedByIgnition" SG_ 2331595987 CPD_Warnstufe 0;
BA_ "GenSigSendType" SG_ 515 DR_Drehwinkel_HL 0;
BA_ "GenSigStartValue" SG_ 515 DR_Drehwinkel_HL 4094;
BA_ "GenSigSwitchedByIgnition" SG_ 515 DR_Drehwinkel_HL 0;
BA_ "Fehlerwert" SG_ 515 DR_Drehwinkel_HL 4095;
BA_ "GenSigSendType" SG_ 515 DR_Drehwinkel_HR 0;
BA_ "GenSigStartValue" SG_ 515 DR_Drehwinkel_HR 4094;
BA_ "GenSigSwitchedByIgnition" SG_ 515 DR_Drehwinkel_HR 0;
BA_ "Fehlerwert" SG_ 515 DR_Drehwinkel_HR 4095;
BA_ "GenSigSendType" SG_ 515 DR_Drehwinkel_VL 0;
BA_ "GenSigStartValue" SG_ 515 DR_Drehwinkel_VL 4094;
BA_ "GenSigSwitchedByIgnition" SG_ 515 DR_Drehwinkel_VL 0;
BA_ "Fehlerwert" SG_ 515 DR_Drehwinkel_VL 4095;
BA_ "GenSigSendType" SG_ 515 DR_Drehwinkel_VR 0;
BA_ "GenSigStartValue" SG_ 515 DR_Drehwinkel_VR 4094;
BA_ "GenSigSwitchedByIgnition" SG_ 515 DR_Drehwinkel_VR 0;
BA_ "Fehlerwert" SG_ 515 DR_Drehwinkel_VR 4095;
BA_ "GenSigSendType" SG_ 515 DR_Drehwinkelsensortausch_HL 0;
BA_ "GenSigSwitchedByIgnition" SG_ 515 DR_Drehwinkelsensortausch_HL 0;
BA_ "GenSigSendType" SG_ 515 DR_Drehwinkelsensortausch_HR 0;
BA_ "GenSigSwitchedByIgnition" SG_ 515 DR_Drehwinkelsensortausch_HR 0;
BA_ "GenSigSendType" SG_ 515 DR_Drehwinkelsensortausch_VL 0;
BA_ "GenSigSwitchedByIgnition" SG_ 515 DR_Drehwinkelsensortausch_VL 0;
BA_ "GenSigSendType" SG_ 515 DR_Drehwinkelsensortausch_VR 0;
BA_ "GenSigSwitchedByIgnition" SG_ 515 DR_Drehwinkelsensortausch_VR 0;
BA_ "GenSigSendType" SG_ 2583738904 DDA_AuthTime_Req_Data 3;
BA_ "GenSigFuncType" SG_ 2583738904 DDA_AuthTime_Req_Data 9;
BA_ "GenSigSwitchedByIgnition" SG_ 2583738904 DDA_AuthTime_Req_Data 0;
BA_ "GenSigSendType" SG_ 2583869976 DDA_AuthTime_Resp_Data 3;
BA_ "GenSigFuncType" SG_ 2583869976 DDA_AuthTime_Resp_Data 9;
BA_ "GenSigSwitchedByIgnition" SG_ 2583869976 DDA_AuthTime_Resp_Data 0;
BA_ "GenSigSwitchedByIgnition" SG_ 2617103104 DEV_DDA_Req_00_Data 0;
BA_ "GenSigSwitchedByIgnition" SG_ 2617103359 DEV_DDA_Resp_FF_Data 0;
BA_ "GenSigSwitchedByIgnition" SG_ 2566843136 DEV_NFC_TGS_Resp_00_Data 0;
BA_ "GenSigSwitchedByIgnition" SG_ 2566843391 DEV_NFC_TGS_Resp_FF_Data 0;
BA_ "GenSigSendType" SG_ 2549891585 DIA_eTABSub_BFS_Req_Data 3;
BA_ "GenSigFuncType" SG_ 2549891585 DIA_eTABSub_BFS_Req_Data 9;
BA_ "GenSigSwitchedByIgnition" SG_ 2549891585 DIA_eTABSub_BFS_Req_Data 0;
BA_ "GenSigSendType" SG_ 2621456897 DIA_eTABSub_BFS_Req_FD_Data 3;
BA_ "GenSigFuncType" SG_ 2621456897 DIA_eTABSub_BFS_Req_FD_Data 9;
BA_ "GenSigSwitchedByIgnition" SG_ 2621456897 DIA_eTABSub_BFS_Req_FD_Data 0;
BA_ "GenSigSendType" SG_ 2550022657 DIA_eTABSub_BFS_Resp_Data 3;
BA_ "GenSigFuncType" SG_ 2550022657 DIA_eTABSub_BFS_Resp_Data 9;
BA_ "GenSigSwitchedByIgnition" SG_ 2550022657 DIA_eTABSub_BFS_Resp_Data 0;
BA_ "GenSigSendType" SG_ 2621587969 DIA_eTABSub_BFS_Resp_FD_Data 3;
BA_ "GenSigFuncType" SG_ 2621587969 DIA_eTABSub_BFS_Resp_FD_Data 9;
BA_ "GenSigSwitchedByIgnition" SG_ 2621587969 DIA_eTABSub_BFS_Resp_FD_Data 0;
BA_ "GenSigSendType" SG_ 2549891584 DIA_eTABSub_FS_Req_Data 3;
BA_ "GenSigFuncType" SG_ 2549891584 DIA_eTABSub_FS_Req_Data 9;
BA_ "GenSigSwitchedByIgnition" SG_ 2549891584 DIA_eTABSub_FS_Req_Data 0;
BA_ "GenSigSendType" SG_ 2621456896 DIA_eTABSub_FS_Req_FD_Data 3;
BA_ "GenSigFuncType" SG_ 2621456896 DIA_eTABSub_FS_Req_FD_Data 9;
BA_ "GenSigSwitchedByIgnition" SG_ 2621456896 DIA_eTABSub_FS_Req_FD_Data 0;
BA_ "GenSigSendType" SG_ 2550022656 DIA_eTABSub_FS_Resp_Data 3;
BA_ "GenSigFuncType" SG_ 2550022656 DIA_eTABSub_FS_Resp_Data 9;
BA_ "GenSigSwitchedByIgnition" SG_ 2550022656 DIA_eTABSub_FS_Resp_Data 0;
BA_ "GenSigSendType" SG_ 2621587968 DIA_eTABSub_FS_Resp_FD_Data 3;
BA_ "GenSigFuncType" SG_ 2621587968 DIA_eTABSub_FS_Resp_FD_Data 9;
BA_ "GenSigSwitchedByIgnition" SG_ 2621587968 DIA_eTABSub_FS_Resp_FD_Data 0;
BA_ "GenSigSendType" SG_ 2549891587 DIA_eTABSub_HBFS_Req_Data 3;
BA_ "GenSigFuncType" SG_ 2549891587 DIA_eTABSub_HBFS_Req_Data 9;
BA_ "GenSigSwitchedByIgnition" SG_ 2549891587 DIA_eTABSub_HBFS_Req_Data 0;
BA_ "GenSigSendType" SG_ 2621456899 DIA_eTABSub_HBFS_Req_FD_Data 3;
BA_ "GenSigFuncType" SG_ 2621456899 DIA_eTABSub_HBFS_Req_FD_Data 9;
BA_ "GenSigSwitchedByIgnition" SG_ 2621456899 DIA_eTABSub_HBFS_Req_FD_Data 0;
BA_ "GenSigSendType" SG_ 2550022659 DIA_eTABSub_HBFS_Resp_Data 3;
BA_ "GenSigFuncType" SG_ 2550022659 DIA_eTABSub_HBFS_Resp_Data 9;
BA_ "GenSigSwitchedByIgnition" SG_ 2550022659 DIA_eTABSub_HBFS_Resp_Data 0;
BA_ "GenSigSendType" SG_ 2621587971 DIA_eTABSub_HBFS_Resp_FD_Data 3;
BA_ "GenSigFuncType" SG_ 2621587971 DIA_eTABSub_HBFS_Resp_FD_Data 9;
BA_ "GenSigSwitchedByIgnition" SG_ 2621587971 DIA_eTABSub_HBFS_Resp_FD_Data 0;
BA_ "GenSigSendType" SG_ 2549891586 DIA_eTABSub_HFS_Req_Data 3;
BA_ "GenSigFuncType" SG_ 2549891586 DIA_eTABSub_HFS_Req_Data 9;
BA_ "GenSigSwitchedByIgnition" SG_ 2549891586 DIA_eTABSub_HFS_Req_Data 0;
BA_ "GenSigSendType" SG_ 2621456898 DIA_eTABSub_HFS_Req_FD_Data 3;
BA_ "GenSigFuncType" SG_ 2621456898 DIA_eTABSub_HFS_Req_FD_Data 9;
BA_ "GenSigSwitchedByIgnition" SG_ 2621456898 DIA_eTABSub_HFS_Req_FD_Data 0;
BA_ "GenSigSendType" SG_ 2550022658 DIA_eTABSub_HFS_Resp_Data 3;
BA_ "GenSigFuncType" SG_ 2550022658 DIA_eTABSub_HFS_Resp_Data 9;
BA_ "GenSigSwitchedByIgnition" SG_ 2550022658 DIA_eTABSub_HFS_Resp_Data 0;
BA_ "GenSigSendType" SG_ 2621587970 DIA_eTABSub_HFS_Resp_FD_Data 3;
BA_ "GenSigFuncType" SG_ 2621587970 DIA_eTABSub_HFS_Resp_FD_Data 9;
BA_ "GenSigSwitchedByIgnition" SG_ 2621587970 DIA_eTABSub_HFS_Resp_FD_Data 0;
BA_ "GenSigSendType" SG_ 2549880555 DIA_NFC_TGS_Req_Data 3;
BA_ "GenSigFuncType" SG_ 2549880555 DIA_NFC_TGS_Req_Data 9;
BA_ "GenSigSwitchedByIgnition" SG_ 2549880555 DIA_NFC_TGS_Req_Data 0;
BA_ "GenSigSendType" SG_ 2550011627 DIA_NFC_TGS_Resp_Data 3;
BA_ "GenSigFuncType" SG_ 2550011627 DIA_NFC_TGS_Resp_Data 9;
BA_ "GenSigSwitchedByIgnition" SG_ 2550011627 DIA_NFC_TGS_Resp_Data 0;
BA_ "GenSigSendType" SG_ 2549880322 DIA_RLF_Req_Data 3;
BA_ "GenSigFuncType" SG_ 2549880322 DIA_RLF_Req_Data 9;
BA_ "GenSigSwitchedByIgnition" SG_ 2549880322 DIA_RLF_Req_Data 0;
BA_ "GenSigSendType" SG_ 2621445634 DIA_RLF_Req_FD_Data 3;
BA_ "GenSigFuncType" SG_ 2621445634 DIA_RLF_Req_FD_Data 9;
BA_ "GenSigSwitchedByIgnition" SG_ 2621445634 DIA_RLF_Req_FD_Data 0;
BA_ "GenSigSendType" SG_ 2550011394 DIA_RLF_Resp_Data 3;
BA_ "GenSigFuncType" SG_ 2550011394 DIA_RLF_Resp_Data 9;
BA_ "GenSigSwitchedByIgnition" SG_ 2550011394 DIA_RLF_Resp_Data 0;
BA_ "GenSigSendType" SG_ 2621576706 DIA_RLF_Resp_FD_Data 3;
BA_ "GenSigFuncType" SG_ 2621576706 DIA_RLF_Resp_FD_Data 9;
BA_ "GenSigSwitchedByIgnition" SG_ 2621576706 DIA_RLF_Resp_FD_Data 0;
BA_ "GenSigSendType" SG_ 2549880357 DIA_SHL_li1_Req_Data 3;
BA_ "GenSigFuncType" SG_ 2549880357 DIA_SHL_li1_Req_Data 9;
BA_ "GenSigSendType" SG_ 2621445669 DIA_SHL_li1_Req_FD_Data 3;
BA_ "GenSigFuncType" SG_ 2621445669 DIA_SHL_li1_Req_FD_Data 9;
BA_ "GenSigSwitchedByIgnition" SG_ 2621445669 DIA_SHL_li1_Req_FD_Data 0;
BA_ "GenSigSendType" SG_ 2550011429 DIA_SHL_li1_Resp_Data 3;
BA_ "GenSigFuncType" SG_ 2550011429 DIA_SHL_li1_Resp_Data 9;
BA_ "GenSigSendType" SG_ 2621576741 DIA_SHL_li1_Resp_FD_Data 3;
BA_ "GenSigFuncType" SG_ 2621576741 DIA_SHL_li1_Resp_FD_Data 9;
BA_ "GenSigSwitchedByIgnition" SG_ 2621576741 DIA_SHL_li1_Resp_FD_Data 0;
BA_ "GenSigSendType" SG_ 2549880590 DIA_SHL_li2_Req_Data 3;
BA_ "GenSigFuncType" SG_ 2549880590 DIA_SHL_li2_Req_Data 9;
BA_ "GenSigSendType" SG_ 2621445902 DIA_SHL_li2_Req_FD_Data 3;
BA_ "GenSigFuncType" SG_ 2621445902 DIA_SHL_li2_Req_FD_Data 9;
BA_ "GenSigSwitchedByIgnition" SG_ 2621445902 DIA_SHL_li2_Req_FD_Data 0;
BA_ "GenSigSendType" SG_ 2550011662 DIA_SHL_li2_Resp_Data 3;
BA_ "GenSigFuncType" SG_ 2550011662 DIA_SHL_li2_Resp_Data 9;
BA_ "GenSigSendType" SG_ 2621576974 DIA_SHL_li2_Resp_FD_Data 3;
BA_ "GenSigFuncType" SG_ 2621576974 DIA_SHL_li2_Resp_FD_Data 9;
BA_ "GenSigSwitchedByIgnition" SG_ 2621576974 DIA_SHL_li2_Resp_FD_Data 0;
BA_ "GenSigSendType" SG_ 2549880591 DIA_SHL_re1_Req_Data 3;
BA_ "GenSigFuncType" SG_ 2549880591 DIA_SHL_re1_Req_Data 9;
BA_ "GenSigSendType" SG_ 2621445903 DIA_SHL_re1_Req_FD_Data 3;
BA_ "GenSigFuncType" SG_ 2621445903 DIA_SHL_re1_Req_FD_Data 9;
BA_ "GenSigSwitchedByIgnition" SG_ 2621445903 DIA_SHL_re1_Req_FD_Data 0;
BA_ "GenSigSendType" SG_ 2550011663 DIA_SHL_re1_Resp_Data 3;
BA_ "GenSigFuncType" SG_ 2550011663 DIA_SHL_re1_Resp_Data 9;
BA_ "GenSigSendType" SG_ 2621576975 DIA_SHL_re1_Resp_FD_Data 3;
BA_ "GenSigFuncType" SG_ 2621576975 DIA_SHL_re1_Resp_FD_Data 9;
BA_ "GenSigSwitchedByIgnition" SG_ 2621576975 DIA_SHL_re1_Resp_FD_Data 0;
BA_ "GenSigSendType" SG_ 2549880592 DIA_SHL_re2_Req_Data 3;
BA_ "GenSigFuncType" SG_ 2549880592 DIA_SHL_re2_Req_Data 9;
BA_ "GenSigSendType" SG_ 2621445904 DIA_SHL_re2_Req_FD_Data 3;
BA_ "GenSigFuncType" SG_ 2621445904 DIA_SHL_re2_Req_FD_Data 9;
BA_ "GenSigSwitchedByIgnition" SG_ 2621445904 DIA_SHL_re2_Req_FD_Data 0;
BA_ "GenSigSendType" SG_ 2550011664 DIA_SHL_re2_Resp_Data 3;
BA_ "GenSigFuncType" SG_ 2550011664 DIA_SHL_re2_Resp_Data 9;
BA_ "GenSigSendType" SG_ 2621576976 DIA_SHL_re2_Resp_FD_Data 3;
BA_ "GenSigFuncType" SG_ 2621576976 DIA_SHL_re2_Resp_FD_Data 9;
BA_ "GenSigSwitchedByIgnition" SG_ 2621576976 DIA_SHL_re2_Resp_FD_Data 0;
BA_ "GenSigSendType" SG_ 2549880734 DIA_VIP_HBFS_Req_Data 3;
BA_ "GenSigFuncType" SG_ 2549880734 DIA_VIP_HBFS_Req_Data 9;
BA_ "GenSigSwitchedByIgnition" SG_ 2549880734 DIA_VIP_HBFS_Req_Data 0;
BA_ "GenSigSendType" SG_ 2621446046 DIA_VIP_HBFS_Req_FD_Data 3;
BA_ "GenSigFuncType" SG_ 2621446046 DIA_VIP_HBFS_Req_FD_Data 9;
BA_ "GenSigSwitchedByIgnition" SG_ 2621446046 DIA_VIP_HBFS_Req_FD_Data 0;
BA_ "GenSigSendType" SG_ 2550011806 DIA_VIP_HBFS_Resp_Data 3;
BA_ "GenSigFuncType" SG_ 2550011806 DIA_VIP_HBFS_Resp_Data 9;
BA_ "GenSigSwitchedByIgnition" SG_ 2550011806 DIA_VIP_HBFS_Resp_Data 0;
BA_ "GenSigSendType" SG_ 2621577118 DIA_VIP_HBFS_Resp_FD_Data 3;
BA_ "GenSigFuncType" SG_ 2621577118 DIA_VIP_HBFS_Resp_FD_Data 9;
BA_ "GenSigSwitchedByIgnition" SG_ 2621577118 DIA_VIP_HBFS_Resp_FD_Data 0;
BA_ "GenSigSendType" SG_ 2549880720 DIA_VIP_HFS_Req_Data 3;
BA_ "GenSigFuncType" SG_ 2549880720 DIA_VIP_HFS_Req_Data 9;
BA_ "GenSigSwitchedByIgnition" SG_ 2549880720 DIA_VIP_HFS_Req_Data 0;
BA_ "GenSigSendType" SG_ 2621446032 DIA_VIP_HFS_Req_FD_Data 3;
BA_ "GenSigFuncType" SG_ 2621446032 DIA_VIP_HFS_Req_FD_Data 9;
BA_ "GenSigSwitchedByIgnition" SG_ 2621446032 DIA_VIP_HFS_Req_FD_Data 0;
BA_ "GenSigSendType" SG_ 2550011792 DIA_VIP_HFS_Resp_Data 3;
BA_ "GenSigFuncType" SG_ 2550011792 DIA_VIP_HFS_Resp_Data 9;
BA_ "GenSigSwitchedByIgnition" SG_ 2550011792 DIA_VIP_HFS_Resp_Data 0;
BA_REL_ "GenSigTimeoutTime" BU_SG_REL_ BCM SG_ 1635 NVEM_Abschaltstufe 1000;
BA_REL_ "GenSigTimeoutTime" BU_SG_REL_ BCM SG_ 1635 NVEM_Freigabe_ZusBatt_Laden 1000;
BA_REL_ "GenSigTimeoutTime" BU_SG_REL_ BCM SG_ 1635 BEM_Anf_KL15_schalten 1000;
BA_REL_ "GenSigTimeoutTime" BU_SG_REL_ BCM SG_ 1482 BMS_KundenWarnung 5000;
BA_REL_ "GenSigTimeoutTime" BU_SG_REL_ BCM SG_ 902 CHA_Fahrer_Umschaltung 5000;
BA_REL_ "GenSigTimeoutTime" BU_SG_REL_ BCM SG_ 902 CHA_Ziel_FahrPr_AMB 5000;
BA_REL_ "GenSigTimeoutTime" BU_SG_REL_ BCM SG_ 2463978646 CHA_Ziel_FahrPr_AFS 5000;
BA_REL_ "GenSigTimeoutTime" BU_SG_REL_ BCM SG_ 2331595987 CPD_Sensierung_Status 2000;
BA_REL_ "GenSigTimeoutTime" BU_SG_REL_ BCM SG_ 2331595987 CPD_Warnstufe 2000;
BA_REL_ "GenSigTimeoutTime" BU_SG_REL_ BCM SG_ 515 DR_Drehwinkelsensortausch_VL 500;
BA_REL_ "GenSigTimeoutTime" BU_SG_REL_ BCM SG_ 515 DR_Drehwinkelsensortausch_VR 500;
BA_REL_ "GenSigTimeoutTime" BU_SG_REL_ BCM SG_ 515 DR_Drehwinkelsensortausch_HL 500;
BA_REL_ "GenSigTimeoutTime" BU_SG_REL_ BCM SG_ 515 DR_Drehwinkelsensortausch_HR 500;
BA_REL_ "GenSigTimeoutTime" BU_SG_REL_ BCM SG_ 515 DR_Drehwinkel_VL 500;
BA_REL_ "GenSigTimeoutTime" BU_SG_REL_ BCM SG_ 515 DR_Drehwinkel_VR 500;
BA_REL_ "GenSigTimeoutTime" BU_SG_REL_ BCM SG_ 515 DR_Drehwinkel_HL 500;
BA_REL_ "GenSigTimeoutTime" BU_SG_REL_ BCM SG_ 515 DR_Drehwinkel_HR 500;
BA_REL_ "GenSigTimeoutTime" BU_SG_REL_ Gateway_Max SG_ 870 BM_Warnblinken 5000;
BA_REL_ "GenSigTimeoutTime" BU_SG_REL_ TSGGen3_BFS SG_ 1163 NVEM_Last_Anf 1000;
BA_REL_ "GenSigTimeoutTime" BU_SG_REL_ TSGGen3_BFS SG_ 2463978850 NVEM2_VerbrZustandsAnf 1000;
BA_REL_ "GenSigTimeoutTime" BU_SG_REL_ TSGGen3_BFS SG_ 1635 NVEM_Abschaltstufe 1000;
BA_REL_ "GenSigTimeoutTime" BU_SG_REL_ TSGGen3_BFS SG_ 1635 NVEM_Freigabe_OnlineUpdate 1000;
BA_REL_ "GenSigTimeoutTime" BU_SG_REL_ TSGGen3_BFS SG_ 870 Blinkmodi_02_CRC 5000;
BA_REL_ "GenSigTimeoutTime" BU_SG_REL_ TSGGen3_BFS SG_ 870 Blinkmodi_02_BZ 5000;
BA_REL_ "GenSigTimeoutTime" BU_SG_REL_ TSGGen3_BFS SG_ 870 Blinken_li_Fzg_Takt 5000;
BA_REL_ "GenSigTimeoutTime" BU_SG_REL_ TSGGen3_BFS SG_ 870 Blinken_re_Fzg_Takt 5000;
BA_REL_ "GenSigTimeoutTime" BU_SG_REL_ TSGGen3_BFS SG_ 2331596015 BSIS_LED_Hell_links 5000;
BA_REL_ "GenSigTimeoutTime" BU_SG_REL_ TSGGen3_BFS SG_ 2331596015 BSIS_LED_Ausgabemodus_links 5000;
BA_REL_ "GenSigTimeoutTime" BU_SG_REL_ TSGGen3_BFS SG_ 2331596016 BSIS_LED_Hell_rechts 5000;
BA_REL_ "GenSigTimeoutTime" BU_SG_REL_ TSGGen3_BFS SG_ 2331596016 BSIS_LED_Ausgabemodus_rechts 5000;
BA_REL_ "GenSigTimeoutTime" BU_SG_REL_ TSGGen3_BFS SG_ 2463978792 CentralLocking_01_BZ 2000;
BA_REL_ "GenSigTimeoutTime" BU_SG_REL_ TSGGen3_BFS SG_ 2463978792 ZV_auto_Ansteuerung 2000;
BA_REL_ "GenSigTimeoutTime" BU_SG_REL_ TSGGen3_BFS SG_ 2463978792 ZV_Bedienstelle_auf 2000;
BA_REL_ "GenSigTimeoutTime" BU_SG_REL_ TSGGen3_BFS SG_ 2463978792 ZV_Bedienstelle_zu 2000;
BA_REL_ "GenSigTimeoutTime" BU_SG_REL_ TSGGen3_BFS SG_ 2463978792 ZV_BT_entriegeln 2000;
BA_REL_ "GenSigTimeoutTime" BU_SG_REL_ TSGGen3_BFS SG_ 2463978792 ZV_BT_verriegeln 2000;
BA_REL_ "GenSigTimeoutTime" BU_SG_REL_ TSGGen3_BFS SG_ 2463978792 ZV_Crashfall_erkannt 2000;
BA_REL_ "GenSigTimeoutTime" BU_SG_REL_ TSGGen3_BFS SG_ 2463978792 ZV_gesafet_extern_ist_02 2000;
BA_REL_ "GenSigTimeoutTime" BU_SG_REL_ TSGGen3_BFS SG_ 2463978792 ZV_Schluessel_Zugang 2000;
BA_REL_ "GenSigTimeoutTime" BU_SG_REL_ TSGGen3_BFS SG_ 2463978792 ZV_Signatur 2000;
BA_REL_ "GenSigTimeoutTime" BU_SG_REL_ TSGGen3_BFS SG_ 2463978792 ZV_Spg_Anklappen 2000;
BA_REL_ "GenSigTimeoutTime" BU_SG_REL_ TSGGen3_BFS SG_ 2463978792 ZV_verriegelt_extern_soll_03 2000;
BA_REL_ "GenSigTimeoutTime" BU_SG_REL_ TSGGen3_BFS SG_ 2463978792 ZV_zentral_entsafen 2000;
BA_REL_ "GenSigTimeoutTime" BU_SG_REL_ TSGGen3_BFS SG_ 2463978792 ZV_zentral_safen 2000;
BA_REL_ "GenSigTimeoutTime" BU_SG_REL_ TSGGen3_BFS SG_ 2463978792 ZV_zu_Zeitl_Nachverr 2000;
BA_REL_ "GenSigTimeoutTime" BU_SG_REL_ TSGGen3_BFS SG_ 2463978792 ZV_TAG_BT_verfahren 2000;
BA_REL_ "GenSigTimeoutTime" BU_SG_REL_ TSGGen3_BFS SG_ 2463978792 ZV_verriegelt_intern_soll_02 2000;
BA_REL_ "GenSigTimeoutTime" BU_SG_REL_ TSGGen3_BFS SG_ 2463978792 ZV_Status_eTAG_ist 2000;
BA_REL_ "GenSigTimeoutTime" BU_SG_REL_ TSGGen3_BFS SG_ 2463978792 ZV_Status_eTAG_soll 2000;
BA_REL_ "GenSigTimeoutTime" BU_SG_REL_ TSGGen3_BFS SG_ 2463978792 ZV_verriegelt_extern_ist_02 2000;
BA_REL_ "GenSigTimeoutTime" BU_SG_REL_ TSGGen3_BFS SG_ 2463978792 ZV_gesafet_extern_soll_02 2000;
BA_REL_ "GenSigTimeoutTime" BU_SG_REL_ TSGGen3_BFS SG_ 2463978792 ZV_verriegelt_intern_ist_02 2000;
BA_REL_ "GenSigTimeoutTime" BU_SG_REL_ TSGGen3_BFS SG_ 2463978792 SOK_CentralLocking_01_Signatur 2000;
BA_REL_ "GenSigTimeoutTime" BU_SG_REL_ TSGGen3_FS SG_ 1163 NVEM_Last_Anf 1000;
BA_REL_ "GenSigTimeoutTime" BU_SG_REL_ TSGGen3_FS SG_ 2463978850 NVEM2_VerbrZustandsAnf 1000;
BA_REL_ "GenSigTimeoutTime" BU_SG_REL_ TSGGen3_FS SG_ 1635 NVEM_Abschaltstufe 1000;
BA_REL_ "GenSigTimeoutTime" BU_SG_REL_ TSGGen3_FS SG_ 1635 NVEM_Freigabe_OnlineUpdate 1000;
BA_REL_ "GenSigTimeoutTime" BU_SG_REL_ TSGGen3_FS SG_ 870 Blinkmodi_02_CRC 5000;
BA_REL_ "GenSigTimeoutTime" BU_SG_REL_ TSGGen3_FS SG_ 870 Blinkmodi_02_BZ 5000;
BA_REL_ "GenSigTimeoutTime" BU_SG_REL_ TSGGen3_FS SG_ 870 Blinken_li_Fzg_Takt 5000;
BA_REL_ "GenSigTimeoutTime" BU_SG_REL_ TSGGen3_FS SG_ 870 Blinken_re_Fzg_Takt 5000;
BA_REL_ "GenSigTimeoutTime" BU_SG_REL_ TSGGen3_FS SG_ 2331596015 BSIS_LED_Hell_links 5000;
BA_REL_ "GenSigTimeoutTime" BU_SG_REL_ TSGGen3_FS SG_ 2331596015 BSIS_LED_Ausgabemodus_links 5000;
BA_REL_ "GenSigTimeoutTime" BU_SG_REL_ TSGGen3_FS SG_ 2331596016 BSIS_LED_Hell_rechts 5000;
BA_REL_ "GenSigTimeoutTime" BU_SG_REL_ TSGGen3_FS SG_ 2331596016 BSIS_LED_Ausgabemodus_rechts 5000;
BA_REL_ "GenSigTimeoutTime" BU_SG_REL_ TSGGen3_FS SG_ 2463978792 CentralLocking_01_BZ 2000;
BA_REL_ "GenSigTimeoutTime" BU_SG_REL_ TSGGen3_FS SG_ 2463978792 ZV_auto_Ansteuerung 2000;
BA_REL_ "GenSigTimeoutTime" BU_SG_REL_ TSGGen3_FS SG_ 2463978792 ZV_Bedienstelle_auf 2000;
BA_REL_ "GenSigTimeoutTime" BU_SG_REL_ TSGGen3_FS SG_ 2463978792 ZV_Bedienstelle_zu 2000;
BA_REL_ "GenSigTimeoutTime" BU_SG_REL_ TSGGen3_FS SG_ 2463978792 ZV_Crashfall_erkannt 2000;
BA_REL_ "GenSigTimeoutTime" BU_SG_REL_ TSGGen3_FS SG_ 2463978792 ZV_FT_entriegeln 2000;
BA_REL_ "GenSigTimeoutTime" BU_SG_REL_ TSGGen3_FS SG_ 2463978792 ZV_FT_verriegeln 2000;
BA_REL_ "GenSigTimeoutTime" BU_SG_REL_ TSGGen3_FS SG_ 2463978792 ZV_LED_Steuerung 2000;
BA_REL_ "GenSigTimeoutTime" BU_SG_REL_ TSGGen3_FS SG_ 2463978792 ZV_LED_Uebernahme 2000;
BA_REL_ "GenSigTimeoutTime" BU_SG_REL_ TSGGen3_FS SG_ 2463978792 ZV_gesafet_extern_ist_02 2000;
BA_REL_ "GenSigTimeoutTime" BU_SG_REL_ TSGGen3_FS SG_ 2463978792 ZV_Schluessel_Zugang 2000;
BA_REL_ "GenSigTimeoutTime" BU_SG_REL_ TSGGen3_FS SG_ 2463978792 ZV_Signatur 2000;
BA_REL_ "GenSigTimeoutTime" BU_SG_REL_ TSGGen3_FS SG_ 2463978792 ZV_Spg_Anklappen 2000;
BA_REL_ "GenSigTimeoutTime" BU_SG_REL_ TSGGen3_FS SG_ 2463978792 ZV_verriegelt_extern_soll_03 2000;
BA_REL_ "GenSigTimeoutTime" BU_SG_REL_ TSGGen3_FS SG_ 2463978792 ZV_zentral_entsafen 2000;
BA_REL_ "GenSigTimeoutTime" BU_SG_REL_ TSGGen3_FS SG_ 2463978792 ZV_zentral_safen 2000;
BA_REL_ "GenSigTimeoutTime" BU_SG_REL_ TSGGen3_FS SG_ 2463978792 ZV_zu_Zeitl_Nachverr 2000;
BA_REL_ "GenSigTimeoutTime" BU_SG_REL_ TSGGen3_FS SG_ 2463978792 ZV_TAG_FT_verfahren 2000;
BA_REL_ "GenSigTimeoutTime" BU_SG_REL_ TSGGen3_FS SG_ 2463978792 IRUE_Taster_Fkts_LED 2000;
BA_REL_ "GenSigTimeoutTime" BU_SG_REL_ TSGGen3_FS SG_ 2463978792 ZV_verriegelt_intern_soll_02 2000;
BA_REL_ "GenSigTimeoutTime" BU_SG_REL_ TSGGen3_FS SG_ 2463978792 ZV_Status_eTAG_ist 2000;
BA_REL_ "GenSigTimeoutTime" BU_SG_REL_ TSGGen3_FS SG_ 2463978792 ZV_Status_eTAG_soll 2000;
BA_REL_ "GenSigTimeoutTime" BU_SG_REL_ TSGGen3_FS SG_ 2463978792 ZV_verriegelt_extern_ist_02 2000;
BA_REL_ "GenSigTimeoutTime" BU_SG_REL_ TSGGen3_FS SG_ 2463978792 ZV_gesafet_extern_soll_02 2000;
BA_REL_ "GenSigTimeoutTime" BU_SG_REL_ TSGGen3_FS SG_ 2463978792 ZV_verriegelt_intern_ist_02 2000;
BA_REL_ "GenSigTimeoutTime" BU_SG_REL_ TSGGen3_FS SG_ 2463978792 SOK_CentralLocking_01_Signatur 2000;
BA_REL_ "GenSigTimeoutTime" BU_SG_REL_ TSGGen3_FS SG_ 902 CHA_Ziel_FahrPr_KL 5000;
BA_REL_ "GenSigTimeoutTime" BU_SG_REL_ TSGGen3_HBFS SG_ 1163 NVEM_Last_Anf 1000;
BA_REL_ "GenSigTimeoutTime" BU_SG_REL_ TSGGen3_HBFS SG_ 1635 NVEM_Abschaltstufe 1000;
BA_REL_ "GenSigTimeoutTime" BU_SG_REL_ TSGGen3_HBFS SG_ 1635 NVEM_Freigabe_OnlineUpdate 1000;
BA_REL_ "GenSigTimeoutTime" BU_SG_REL_ TSGGen3_HBFS SG_ 2463978792 CentralLocking_01_BZ 2000;
BA_REL_ "GenSigTimeoutTime" BU_SG_REL_ TSGGen3_HBFS SG_ 2463978792 ZV_auto_Ansteuerung 2000;
BA_REL_ "GenSigTimeoutTime" BU_SG_REL_ TSGGen3_HBFS SG_ 2463978792 ZV_Bedienstelle_auf 2000;
BA_REL_ "GenSigTimeoutTime" BU_SG_REL_ TSGGen3_HBFS SG_ 2463978792 ZV_Bedienstelle_zu 2000;
BA_REL_ "GenSigTimeoutTime" BU_SG_REL_ TSGGen3_HBFS SG_ 2463978792 ZV_Crashfall_erkannt 2000;
BA_REL_ "GenSigTimeoutTime" BU_SG_REL_ TSGGen3_HBFS SG_ 2463978792 ZV_HBFS_entriegeln 2000;
BA_REL_ "GenSigTimeoutTime" BU_SG_REL_ TSGGen3_HBFS SG_ 2463978792 ZV_HBFS_verriegeln 2000;
BA_REL_ "GenSigTimeoutTime" BU_SG_REL_ TSGGen3_HBFS SG_ 2463978792 ZV_gesafet_extern_ist_02 2000;
BA_REL_ "GenSigTimeoutTime" BU_SG_REL_ TSGGen3_HBFS SG_ 2463978792 ZV_Schluessel_Zugang 2000;
BA_REL_ "GenSigTimeoutTime" BU_SG_REL_ TSGGen3_HBFS SG_ 2463978792 ZV_Signatur 2000;
BA_REL_ "GenSigTimeoutTime" BU_SG_REL_ TSGGen3_HBFS SG_ 2463978792 ZV_verriegelt_extern_soll_03 2000;
BA_REL_ "GenSigTimeoutTime" BU_SG_REL_ TSGGen3_HBFS SG_ 2463978792 ZV_zentral_entsafen 2000;
BA_REL_ "GenSigTimeoutTime" BU_SG_REL_ TSGGen3_HBFS SG_ 2463978792 ZV_zentral_safen 2000;
BA_REL_ "GenSigTimeoutTime" BU_SG_REL_ TSGGen3_HBFS SG_ 2463978792 ZV_zu_Zeitl_Nachverr 2000;
BA_REL_ "GenSigTimeoutTime" BU_SG_REL_ TSGGen3_HBFS SG_ 2463978792 ZV_TAG_HBFS_verfahren 2000;
BA_REL_ "GenSigTimeoutTime" BU_SG_REL_ TSGGen3_HBFS SG_ 2463978792 ZV_verriegelt_intern_soll_02 2000;
BA_REL_ "GenSigTimeoutTime" BU_SG_REL_ TSGGen3_HBFS SG_ 2463978792 ZV_Status_eTAG_ist 2000;
BA_REL_ "GenSigTimeoutTime" BU_SG_REL_ TSGGen3_HBFS SG_ 2463978792 ZV_Status_eTAG_soll 2000;
BA_REL_ "GenSigTimeoutTime" BU_SG_REL_ TSGGen3_HBFS SG_ 2463978792 ZV_verriegelt_extern_ist_02 2000;
BA_REL_ "GenSigTimeoutTime" BU_SG_REL_ TSGGen3_HBFS SG_ 2463978792 ZV_gesafet_extern_soll_02 2000;
BA_REL_ "GenSigTimeoutTime" BU_SG_REL_ TSGGen3_HBFS SG_ 2463978792 ZV_verriegelt_intern_ist_02 2000;
BA_REL_ "GenSigTimeoutTime" BU_SG_REL_ TSGGen3_HBFS SG_ 2463978792 SOK_CentralLocking_01_Signatur 2000;
BA_REL_ "GenSigTimeoutTime" BU_SG_REL_ TSGGen3_HFS SG_ 1163 NVEM_Last_Anf 1000;
BA_REL_ "GenSigTimeoutTime" BU_SG_REL_ TSGGen3_HFS SG_ 1635 NVEM_Abschaltstufe 1000;
BA_REL_ "GenSigTimeoutTime" BU_SG_REL_ TSGGen3_HFS SG_ 1635 NVEM_Freigabe_OnlineUpdate 1000;
BA_REL_ "GenSigTimeoutTime" BU_SG_REL_ TSGGen3_HFS SG_ 2463978792 CentralLocking_01_BZ 2000;
BA_REL_ "GenSigTimeoutTime" BU_SG_REL_ TSGGen3_HFS SG_ 2463978792 ZV_auto_Ansteuerung 2000;
BA_REL_ "GenSigTimeoutTime" BU_SG_REL_ TSGGen3_HFS SG_ 2463978792 ZV_Bedienstelle_auf 2000;
BA_REL_ "GenSigTimeoutTime" BU_SG_REL_ TSGGen3_HFS SG_ 2463978792 ZV_Bedienstelle_zu 2000;
BA_REL_ "GenSigTimeoutTime" BU_SG_REL_ TSGGen3_HFS SG_ 2463978792 ZV_Crashfall_erkannt 2000;
BA_REL_ "GenSigTimeoutTime" BU_SG_REL_ TSGGen3_HFS SG_ 2463978792 ZV_HFS_entriegeln 2000;
BA_REL_ "GenSigTimeoutTime" BU_SG_REL_ TSGGen3_HFS SG_ 2463978792 ZV_HFS_verriegeln 2000;
BA_REL_ "GenSigTimeoutTime" BU_SG_REL_ TSGGen3_HFS SG_ 2463978792 ZV_gesafet_extern_ist_02 2000;
BA_REL_ "GenSigTimeoutTime" BU_SG_REL_ TSGGen3_HFS SG_ 2463978792 ZV_Schluessel_Zugang 2000;
BA_REL_ "GenSigTimeoutTime" BU_SG_REL_ TSGGen3_HFS SG_ 2463978792 ZV_Signatur 2000;
BA_REL_ "GenSigTimeoutTime" BU_SG_REL_ TSGGen3_HFS SG_ 2463978792 ZV_verriegelt_extern_soll_03 2000;
BA_REL_ "GenSigTimeoutTime" BU_SG_REL_ TSGGen3_HFS SG_ 2463978792 ZV_zentral_entsafen 2000;
BA_REL_ "GenSigTimeoutTime" BU_SG_REL_ TSGGen3_HFS SG_ 2463978792 ZV_zentral_safen 2000;
BA_REL_ "GenSigTimeoutTime" BU_SG_REL_ TSGGen3_HFS SG_ 2463978792 ZV_zu_Zeitl_Nachverr 2000;
BA_REL_ "GenSigTimeoutTime" BU_SG_REL_ TSGGen3_HFS SG_ 2463978792 ZV_TAG_HFS_verfahren 2000;
BA_REL_ "GenSigTimeoutTime" BU_SG_REL_ TSGGen3_HFS SG_ 2463978792 ZV_verriegelt_intern_soll_02 2000;
BA_REL_ "GenSigTimeoutTime" BU_SG_REL_ TSGGen3_HFS SG_ 2463978792 ZV_Status_eTAG_ist 2000;
BA_REL_ "GenSigTimeoutTime" BU_SG_REL_ TSGGen3_HFS SG_ 2463978792 ZV_Status_eTAG_soll 2000;
BA_REL_ "GenSigTimeoutTime" BU_SG_REL_ TSGGen3_HFS SG_ 2463978792 ZV_verriegelt_extern_ist_02 2000;
BA_REL_ "GenSigTimeoutTime" BU_SG_REL_ TSGGen3_HFS SG_ 2463978792 ZV_gesafet_extern_soll_02 2000;
BA_REL_ "GenSigTimeoutTime" BU_SG_REL_ TSGGen3_HFS SG_ 2463978792 ZV_verriegelt_intern_ist_02 2000;
BA_REL_ "GenSigTimeoutTime" BU_SG_REL_ TSGGen3_HFS SG_ 2463978792 SOK_CentralLocking_01_Signatur 2000;
BA_REL_ "GenSigTimeoutTime" BU_SG_REL_ WLC_01_CFD SG_ 1635 NVEM_Abschaltstufe 1000;
BA_REL_ "GenSigTimeoutTime" BU_SG_REL_ WLC_01_CFD SG_ 1635 NVEM_Freigabe_OnlineUpdate 1000;
VAL_ 1427 KY_IDGeber_1_Status 0 "keine_Antwort" 1 "authentifiziert" 2 "UHV_Antwort_nicht_authentifiziert" ;
VAL_ 1427 KY_IDGeber_2_Status 0 "keine_Antwort" 1 "authentifiziert" 2 "UHV_Antwort_nicht_authentifiziert" ;
VAL_ 1427 KY_Softtouch 0 "inaktiv" 1 "aktiv" ;
VAL_ 1427 KY_HD_Verriegelung_Autorisiert 0 "nicht_autorisiert" 1 "autorisiert" ;
VAL_ 1427 KY_IDGeber_3_Status 0 "keine_Antwort" 1 "authentifiziert" 2 "UHV_Antwort_nicht_authentifiziert" ;
VAL_ 1427 KY_IDGeber_4_Status 0 "keine_Antwort" 1 "authentifiziert" 2 "UHV_Antwort_nicht_authentifiziert" ;
VAL_ 1427 ZV_Anf_Abschaltung_Zuendung 0 "kein_Verriegelungswunsch_Kl_15" 1 "Verriegelungswunsch_Kl_15" ;
VAL_ 1427 KY_FFB_in_LF_Reichw 0 "inaktiv" 1 "aktiv" ;
VAL_ 1427 KY_IDGeber_1_Bat 0 "Batterie_iO" 1 "Entry_Exit_gesperrt" 2 "Go_gesperrt" ;
VAL_ 1427 KY_IDGeber_2_Bat 0 "Batterie_iO" 1 "Entry_Exit_gesperrt" 2 "Go_gesperrt" ;
VAL_ 1427 KY_IDGeber_3_Bat 0 "Batterie_iO" 1 "Entry_Exit_gesperrt" 2 "Go_gesperrt" ;
VAL_ 1427 KY_IDGeber_4_Bat 0 "Batterie_iO" 1 "Entry_Exit_gesperrt" 2 "Go_gesperrt" ;
VAL_ 1427 KY_KessyEntryExit_Akt 0 "inaktiv" 1 "aktiv" ;
VAL_ 1427 KY_Autofunktion_Aktiv 0 "inaktiv" 1 "aktiv" ;
VAL_ 1427 KY_Anf_Reichwbegr 0 "inaktiv" 1 "aktiv" ;
VAL_ 1427 KY_Anf_Reichwbegr_Gesamt 0 "inaktiv" 1 "aktiv" ;
VAL_ 1427 KY_Bedienstelle 1 "SZ_FT" 2 "SZ_BT" 3 "SZ_HD" 4 "FFB_auf_zu" 5 "FFB_HD" 6 "KY_FT" 7 "KY_BT" 8 "KY_HFS" 9 "KY_HBFS" 10 "KY_Softtouch" 11 "LU_Taster_FT" 12 "LU_Taster_BT" 13 "LU_Taster_HFS" 14 "LU_Taster_HBFS" 15 "autom_Wiederentriegelung" 16 "Entsafen_KL15_ein" 17 "Crash_Entriegeln" 18 "Autolock" 19 "AutoUnlock_Abzug_Zuendschluessel" 20 "Abbruch_Airbag_Kommunikation" 21 "Telematik" 22 "Wiederentr_IDGeber_im_Fzg" 23 "ELV_Wiederentriegeln" 24 "KY_Annaeherung_rechts" 25 "KY_Annaeherung_links" 26 "KY_Annaeherung_Heck" 27 "LU_Taster_BCM" 28 "Entsafen_unzul_Schlossstatus_Saf" 29 "KY_verriegeln_Door_Slap_FT" 30 "KY_verriegeln_Door_Slap_BT" 31 "KY_verriegeln_Door_Slap_HFS" 32 "KY_verriegeln_Door_Slap_HBFS" 33 "KY_verriegeln_Door_Slap_Heck" 34 "HDF_Innentaster" 35 "Heck_Security_Lock" 36 "MFG_Tuerentriegelung_hinten" 37 "VIT_Servoheck" 38 "Virtuelles_Pedal_VIP" 39 "Easy_Close_Innentaster_Servoheck" 40 "Taster_Laderaumschliessung" 41 "FFB_NFZ_Schliessung" 42 "KFG_Lock_Unlock_FT" 43 "KFG_Lock_Unlock_BT" 44 "KFG_Lock_Unlock_HFS" 45 "KFG_Lock_Unlock_HBFS" 46 "KFG_Lock_Unlock_Hecktuer" 47 "KFG_Lock_Unlock_Laderaumtueren" 48 "KFG_Lock_Unlock_Gesamt" 49 "Digital_Key_NFC_FT" 50 "Digital_Key_NFC_HD" 51 "Digital_Key_BTLE_Verr_Entr" 52 "Digital_Key_BTLE_HD" 53 "Digital_Key_BTLE_SBT_links" 54 "Digital_Key_BTLE_SBT_rechts" 55 "Digital_Key_BTLE_NFZ_Schliessung" 56 "Kessy_LOL" 57 "Kessy_OOA" 63 "Power_on_Reset" ;
VAL_ 1427 KY_Verriegeln 0 "inaktiv" 1 "aktiv" ;
VAL_ 1427 KY_Entriegeln 0 "inaktiv" 1 "aktiv" ;
VAL_ 1427 KY_Schluesselnr 0 "kein authorisierter Schluessel erkannt " 1 "aktive_Funkschluessel_Nr_01" 2 "aktive_Funkschluessel_Nr_02" 3 "aktive_Funkschluessel_Nr_03" 4 "aktive_Funkschluessel_Nr_04" 5 "aktive_Funkschluessel_Nr_05" 6 "aktive_Funkschluessel_Nr_06" 7 "aktive_Funkschluessel_Nr_07" 8 "aktive_Funkschluessel_Nr_08" 9 "ungueltig_09" 10 "ungueltig_10" 11 "ungueltig_11" 12 "ungueltig_12" 13 "ungueltig_13" 14 "ungueltig_14" 15 "ungueltig_15" ;
VAL_ 1432 LIM_bCall_Taster 0 "nicht_betaetigt" 1 "betaetigt" ;
VAL_ 1432 LIM_iCall_Taster 0 "nicht_betaetigt" 1 "betaetigt" ;
VAL_ 1432 LINDa_Touch_Event 0 "nicht_betaetigt" 1 "Tippen" 2 "Wischen_Slide" 3 "Geste" 4 "Doppeltippen" 5 "Longpress_1" 6 "Longpress_2" 7 "Longpress_3" 8 "Press" 9 "Strongpress" 10 "reserviert" 11 "reserviert" 12 "reserviert" 13 "reserviert" 14 "Taktgeber_Inkrement" 15 "Fehler" ;
VAL_ 1432 BCM_FS_Programmwippe 0 "Taster_unbetaetigt" 1 "Taster_betaetigt" ;
VAL_ 1432 BCM_BFS_Programmwippe 0 "Taster_unbetaetigt" 1 "Taster_betaetigt" ;
VAL_ 1432 BCM_FS_Multif_Taster 0 "Taster_unbetaetigt" 1 "Taster_betaetigt" ;
VAL_ 1432 BCM_BFS_Multif_Taster 0 "Taster_unbetaetigt" 1 "Taster_betaetigt" ;
VAL_ 1432 BCM_FS_Massage_Taster 0 "Taster_unbetaetigt" 1 "Taster_betaetigt" ;
VAL_ 1432 BCM_BFS_Massage_Taster 0 "Taster_unbetaetigt" 1 "Taster_betaetigt" ;
VAL_ 1432 BCM_FS_Pneumatik_Verstellung 0 "keine_Verstellung" 1 "Pneumatikverstellung_aktiv" ;
VAL_ 1432 BCM_BFS_Pneumatik_Verstellung 0 "keine_Verstellung" 1 "Pneumatikverstellung_aktiv" ;
VAL_ 1432 LIM_S_Rollo_vo 0 "nicht_betaetigt" 1 "man_zu" 2 "auto_zu" 3 "man_auf" 4 "auto_auf" 5 "stop" 6 "fehler_schalter_haengt" 7 "fehler_schalter_unplausibel" ;
VAL_ 1432 LIM_S_Rollo_hi 0 "nicht_betaetigt" 1 "man_zu" 2 "auto_zu" 3 "man_auf" 4 "auto_auf" 5 "stop" 6 "fehler_schalter_haengt" 7 "fehler_schalter_unplausibel" ;
VAL_ 1432 LIM_S_SAD_Vo 0 "nicht_betaetigt" 1 "man_sl_zu" 2 "auto_sl_zu" 3 "man_sl_auf" 4 "auto_sl_auf" 5 "man_al_auf" 6 "auto_al_auf" 7 "man_al_zu" 8 "auto_al_zu" 9 "stop" 10 "Toggle_Taster_AL_betaetigt" 14 "fehler_schalter_haengt" 15 "fehler_schalter_unplausibel" ;
VAL_ 1432 LIM_S_SAD_hi 0 "nicht_betaetigt" 1 "man_sl_zu" 2 "auto_sl_zu" 3 "man_sl_auf" 4 "auto_sl_auf" 5 "man_al_auf" 6 "auto_al_auf" 7 "man_al_zu" 8 "auto_al_zu" 14 "fehler_schalter_haengt" 15 "fehler_schalter_unplausibel" ;
VAL_ 2527679781 LINDa_HL_Touch_Event 0 "nicht_betaetigt" 1 "Tippen" 2 "Wischen_Slide" 3 "Geste" 4 "Doppeltippen" 5 "Longpress_1" 6 "Longpress_2" 7 "Longpress_3" 8 "Press" 9 "Strongpress" 10 "reserviert" 11 "reserviert" 12 "reserviert" 13 "reserviert" 14 "Taktgeber_Inkrement" 15 "Fehler" ;
VAL_ 2527679781 LINDa_HR_Touch_Event 0 "nicht_betaetigt" 1 "Tippen" 2 "Wischen_Slide" 3 "Geste" 4 "Doppeltippen" 5 "Longpress_1" 6 "Longpress_2" 7 "Longpress_3" 8 "Press" 9 "Strongpress" 10 "reserviert" 11 "reserviert" 12 "reserviert" 13 "reserviert" 14 "Taktgeber_Inkrement" 15 "Fehler" ;
VAL_ 2527679781 LINDa_HL_SR3_Touch_Event 0 "nicht_betaetigt" 1 "Tippen" 2 "Wischen_Slide" 3 "Geste" 4 "Doppeltippen" 5 "Longpress_1" 6 "Longpress_2" 7 "Longpress_3" 8 "Press" 9 "Strongpress" 10 "reserviert" 11 "reserviert" 12 "reserviert" 13 "reserviert" 14 "Taktgeber_Inkrement" 15 "Fehler" ;
VAL_ 2527679781 LINDa_HR_SR3_Touch_Event 0 "nicht_betaetigt" 1 "Tippen" 2 "Wischen_Slide" 3 "Geste" 4 "Doppeltippen" 5 "Longpress_1" 6 "Longpress_2" 7 "Longpress_3" 8 "Press" 9 "Strongpress" 10 "reserviert" 11 "reserviert" 12 "reserviert" 13 "reserviert" 14 "Taktgeber_Inkrement" 15 "Fehler" ;
VAL_ 2463978855 DML_HMI_FCN_CROSSINGLI_REQUEST 0 "not_requested" 1 "requested" ;
VAL_ 2463978855 DML_HMI_FCN_HAZARDWARN_REQUEST 0 "not_requested" 1 "requested" ;
VAL_ 2463978855 DML_HMI_FCN_LANELIGHT_REQUEST 0 "not_requested" 1 "requested" ;
VAL_ 2463978855 DML_HMI_FCN_LANLEAVELI_REQUEST 0 "not_requested" 1 "requested" ;
VAL_ 2463978855 DML_HMI_FCN_MALI_REQUEST 0 "not_requested" 1 "requested" ;
VAL_ 2463978855 DML_HMI_FCN_ORLI_REQUEST 0 "not_requested" 1 "requested" ;
VAL_ 2463978855 DML_HMI_FCN_RESALLEYHI_REQUEST 0 "not_requested" 1 "requested" ;
VAL_ 2463978855 DML_HMI_FCN_ROADWORKLI_REQUEST 0 "not_requested" 1 "requested" ;
VAL_ 2463978855 DML_HMI_FCN_SAFETYZONE_REQUEST 0 "not_requested" 1 "requested" ;
VAL_ 2463978855 DML_HMI_FCN_TURNLIGHPR_REQUEST 0 "not_requested" 1 "requested" ;
VAL_ 2463978855 DML_ConstructionZone_Enabled 0 "disabled" 1 "enabled" ;
VAL_ 2463978855 DML_CrossingAssist_Enabled 0 "disabled" 1 "enabled" ;
VAL_ 2463978855 DML_GhostDriverWarn_Enabled 0 "disabled" 1 "enabled" ;
VAL_ 2463978855 DML_GlarefreeHB_Enabled 0 "disabled" 1 "enabled" ;
VAL_ 2463978855 DML_HazardWarning_Enabled 0 "disabled" 1 "enabled" ;
VAL_ 2463978855 DML_Indicator_Enabled 0 "disabled" 1 "enabled" ;
VAL_ 2463978855 DML_IntelligentHB_Enabled 0 "disabled" 1 "enabled" ;
VAL_ 2463978855 DML_LaneDepartureWarn_Enabled 0 "disabled" 1 "enabled" ;
VAL_ 2463978855 DML_LaneLight_Enabled 0 "disabled" 1 "enabled" ;
VAL_ 2463978855 DML_MarkingLight_Enabled 0 "disabled" 1 "enabled" ;
VAL_ 2463978855 DML_OrientationLight_Enabled 0 "disabled" 1 "enabled" ;
VAL_ 2463978855 DML_RescueLaneNotice_Enabled 0 "disabled" 1 "enabled" ;
VAL_ 2463978855 DML_SafetyZone_Enabled 0 "disabled" 1 "enabled" ;
VAL_ 2463978855 DML_SaftyDistance_Enabled 0 "disabled" 1 "enabled" ;
VAL_ 2463978855 DML_SideAssist_Enabled 0 "disabled" 1 "enabled" ;
VAL_ 1635 NVEM_Abschaltstufe 0 "Stufe_0_keine_Einschraenkung" 1 "Stufe_1" 2 "Stufe_2" 3 "Stufe_3" ;
VAL_ 1635 BEM_STH_Zielzeit 14 "Init" 15 "Fehler" ;
VAL_ 1635 BEM_MMI_Vorwarnung 0 "keine Anzeige" 1 "Anzeige MMI-Vorwarnung" ;
VAL_ 1635 NVEM_Freigabe_ZusBatt_Laden 0 "keine_Freigabe_Laderelais" 1 "Freigabe_Laderelais_schliessen" ;
VAL_ 1635 NVEM_Anf_SD_schalten 0 "Anf_SD_Nachlauf_nicht_aktiv" 1 "Anf_SD_Nachlauf_aktiv" ;
VAL_ 1635 BEM_Generatordiagnose 0 "keine Anzeige" 1 "Ladekontrollanzeige ein (Vorhalt)" 2 "rotes Batteriesymbol und Text (Generator defekt)" 3 "Hybrid_DCDC_Wandler_defekt" ;
VAL_ 1635 BEM_Red_Innengeblaese 0 "keine Reduzierung" 1 "Reduzierung Stufe 1" 2 "Reduzierung Stufe 2" 3 "Reduzierung Stufe 2 und Abschaltung Kompressor" ;
VAL_ 1635 BEM_STH_Einschaltverbot 0 "volle Verfuegbarkeit Standheizung/-lueftung" 1 "Standheizung/-lueftung nicht aktivierbar" ;
VAL_ 1635 BEM_HL_Regelung_Status 0 "HL_Regelung_inaktiv_(vor_und_waehrend_Motorstart)" 1 "HL_Regelung_Stufe_1" 2 "HL_Regelung_Stufe_2" 3 "HL_Regelung_Stufe_3" 4 "Verbrauchernotabschaltung_(VNA)" 5 "HL_Regelung_Stufe_5" 7 "Default" ;
VAL_ 1635 BEM_Ladezustand 14 "Init" 15 "Fehler" ;
VAL_ 1635 BEM_Batteriediagnose 0 "keine_Anzeige" 1 "nicht_belegt" 2 "Anzeige_aberkannte_Batterie" 3 "Anzeige_schwache_Batterie" 4 "Anzeige_Batterie_OK" 5 "Anzeige_Batterie_Laden" 6 "Anzeige_Batterie_Pruefen" 7 "Fehler" ;
VAL_ 1635 MIB_Stromsparmodus 0 "inaktiv" 1 "aktiv" ;
VAL_ 1635 BEM_REK_aktiv 0 "keine_Rekuperationsfreigabe" 1 "Rekuperationsfreigabe" ;
VAL_ 1635 BEM_EMLIN_ungueltig 0 "Signale_gueltig" 1 "Signale_ungueltig" ;
VAL_ 1635 BEM_Batt_Ab 0 "verbunden" 1 "nicht_verbunden" ;
VAL_ 1635 BEM_UBDM 0 "Init" 255 "Fehler" ;
VAL_ 1635 BEM_Anf_KL15_schalten 0 "Keine_Einschraenkung_Kl15" 1 "Empfehlung_auto_Abschaltung_Kl15" 2 "Veto_auto_Abschaltung_Kl15" 3 "Veto_auto_Abschaltung_Fahrtbetrieb" ;
VAL_ 1635 NVEM_Batterie_Service 0 "kein_Service" 1 "Service_Information1" 2 "Service_Information2" 3 "Service_Information3" ;
VAL_ 1635 NVEM_Freigabe_OnlineUpdate 0 "keine_Freigabe" 1 "Freigabe" ;
VAL_ 1635 NVEM_Freigabe_ORU4 0 "Init" 1 "keine_Freigabe" 2 "Freigabe_erteilt" 3 "Veto_Freigabe" ;
VAL_ 1635 NVEM_Verbraucherabsch_Anz 0 "keine_Anzeige" 1 "Anzeige_aktiv" ;
VAL_ 1163 NVEM_Betriebsart 0 "oKl15_Sing_oVerbr" 1 "oKl15_Red_RedKontingent_oVerbr" 2 "oKl15_Red_HohKontingent_oVerbr" 3 "oKl15_Red_mVerbr" 4 "reserved" 5 "reserved" 6 "reserved" 7 "reserved" 8 "mKl15_Sing_oVerbr" 9 "mKl15_Red_RedKontingent_oVerbr" 10 "mKl15_Red_HohKontingent_oVerbr" 11 "mKl15_Red_mVerbr" 12 "Fahrbereitschaft_mVerbr" 13 "reserved" 14 "reserved" 15 "Fehler" ;
VAL_ 1163 NVEM_Ladezustand 126 "INIT" 127 "Fehler" ;
VAL_ 1163 NVEM2_Status_FuSiFahrt 0 "Init" 1 "Keine_FuSi_Fahrt" 2 "Qualifikation_FuSi_Fahrt" 3 "FuSi_Fahrt_Aktiv" 4 "Qualifikation_Ende_FuSi_Fahrt" 5 "FuSi_Stand" 6 "FuSi_Nachlauf" 7 "Fehler" ;
VAL_ 1163 NVEM_Energienetz_Status 0 "QM" 1 "ASIL_A" 2 "ASIL_B" 3 "ASIL_C" 6 "InitWert" 7 "Fehler" ;
VAL_ 1163 NVEM_Vorgabe_Leistungsstufe 0 "Init" 1 "Leistungsstufe_0" 2 "Leistungsstufe_1" 3 "Leistungsstufe_2" 4 "Leistungsstufe_3" 5 "Leistungsstufe_4" 6 "Leistungsstufe_5" 7 "Fehler" ;
VAL_ 1163 NVEM2_Typ_EnergieNetz 0 "Sp12V_Gen_ICE" 1 "Sp12V_BEV" 2 "Sp12V_PHEV" 3 "Sp12V_MHEV" 4 "Sp12V_HEV" 5 "Sp12V_Sp48V_Gen_Insel" 6 "Sp12V_Sp12V_RSG_MHEV12V" 7 "Sp12V_BEV_ASILC" 14 "Fehler" 15 "Init" ;
VAL_ 1163 NVEM_Energie_Klima_Vorgabe 254 "Init" 255 "Fehler" ;
VAL_ 1163 NVEM_Last_Anf 0 "keine Anforderung" 1 "Verbraucher_Anforderung_Stufe_1" 2 "Verbraucher_Anforderung_Stufe_2" 3 "Verbraucher_Anforderung_Stufe_3" ;
VAL_ 1163 NVEM_STH_ZielzeitLang 14 "Init" 15 "Fehler" ;
VAL_ 1163 NVEM_Red_KomfortVerbrauch 0 "keine_Einschraenkung" 1 "Einschraenkung_Stufe_1" 2 "Einschraenkung_Stufe_2" 3 "Einschraenkung_Stufe_3" 4 "Einschraenkung_Stufe_4" 5 "Einschraenkung_Stufe_5" 6 "Einschraenkung_Stufe_6" 7 "Einschraenkung_Stufe_7" 8 "Einschraenkung_Stufe_8" 15 "Fehler" ;
VAL_ 1163 NVEM_PTC_Sollstufe 0 "Aus" 1 "Stufe_1" 2 "Stufe_2" 3 "Stufe_3" ;
VAL_ 1163 NVEM_Bordnetzdiagnose 0 "kein_Fehler" 1 "Warnung_1" 2 "Warnung_2" 3 "Warnung_3" ;
VAL_ 1163 HLR_PTC_linear_Freigabe 63 "Fehler" ;
VAL_ 2463978850 NVEM_Bordnetz_Information 0 "keine_Anzeige" 1 "NV_Batterie_iO" 2 "NV_Batterie_laden" 3 "NV_Batterie_pruefen" 4 "NV_Batterie_schwach" 5 "NV_Batterie_Ab" 6 "NV_Batterie_Service" 7 "NV_Energiesystem_unplausibel" 8 "Ladekontrollleuchte" 9 "Generator_defekt" 10 "reserviert" 11 "reserviert" 12 "reserviert" 13 "reserviert" 14 "Init" 15 "Fehler" ;
VAL_ 2463978850 NVEM_Verbraucher_Information 0 "Keine_Anzeige" 1 "MMI_Vorwarnung" 2 "Anzeige_Verbraucherabschaltung" 3 "reserviert" 4 "reserviert" 5 "reserviert" 6 "Init" 7 "Fehler" ;
VAL_ 2463978850 NVEM2_VerbrZustandsAnf 0 "Freigabe" 1 "Verbraucher_Sperren" 2 "Verbr_Sperren_KL_Red" 3 "reserved" 4 "reserved" 5 "reserved" 6 "Verbr_Sperren_KL_Anf" 7 "Teilweise_Anschalt_Anf" 8 "Anschalt_Anf" 9 "reserved" 10 "reserved" 11 "Abschaltstufe_1" 12 "Abschaltstufe_2" 13 "Abschaltstufe_3" 14 "Init" 15 "Fehler" ;
VAL_ 2463978850 NVEM_NVStuetzungAnf 0 "keine_Anforderung" 1 "Anforderung_sichere_Versorgung" 2 "Anforderung_Abschaltung" 3 "Fehler" ;
VAL_ 2463978850 NVEM3_Absch_SCR 0 "Init" 1 "Abschaltung_SCR" ;
VAL_ 2463978850 NVEM_Batt_Temp_Hinweis 0 "Keine_Anzeige" 1 "Hinweis_Aussenhuelle_zu" 2 "Hinweis_Klima_ein" 3 "Wunsch_Aussenhuelle_zu" 4 "Wunsch_Klima_ein" ;
VAL_ 870 BM_ZV_auf 0 "inaktiv" 1 "aktiv" ;
VAL_ 870 BM_ZV_zu 0 "inaktiv" 1 "aktiv" ;
VAL_ 870 BM_DWA_ein 0 "inaktiv" 1 "aktiv" ;
VAL_ 870 BM_DWA_Alarm 0 "inaktiv" 1 "aktiv" ;
VAL_ 870 BM_Crash 0 "inaktiv" 1 "aktiv" ;
VAL_ 870 BM_Panik 0 "inaktiv" 1 "aktiv" ;
VAL_ 870 BM_Not_Bremsung 0 "kein_blinken" 1 "Notbremswarnblinken_aktiv" ;
VAL_ 870 BM_GDO 0 "inaktiv" 1 "aktiv" ;
VAL_ 870 BM_Warnblinken 0 "inaktiv" 1 "aktiv" ;
VAL_ 870 BM_Taxi_Notalarm 0 "inaktiv" 1 "aktiv" ;
VAL_ 870 BM_Telematik 0 "inaktiv" 1 "aktiv" ;
VAL_ 870 BM_links 0 "inaktiv" 1 "aktiv" ;
VAL_ 870 BM_rechts 0 "inaktiv" 1 "aktiv" ;
VAL_ 870 Blinken_li_Fzg_Takt 0 "Blinker_links_ausgeschaltet" 1 "Blinker_links_eingeschaltet" ;
VAL_ 870 Blinken_re_Fzg_Takt 0 "Blinker_rechts_ausgeschaltet" 1 "Blinker_rechts_eingeschaltet" ;
VAL_ 870 Blinken_li_Kombi_Takt 0 "Blinkerkontrolllampe_links_ausgeschaltet" 1 "Blinkerkontrolllampe_links_eingeschaltet" ;
VAL_ 870 Blinken_re_Kombi_Takt 0 "Blinkerkontrolllampe_rechts_ausgeschaltet" 1 "Blinkerkontrolllampe_rechts_eingeschaltet" ;
VAL_ 870 BM_NBA_n_codiert_n_aktiv 0 "codiert_AND_kein_Fehler" 1 "nicht_codiert_OR_Fehler_erkannt" ;
VAL_ 870 BM_NBA_Status 0 "NBA_nicht_aktiv" 1 "BRL_Dunkelphase" 3 "BRL_Hellphase" ;
VAL_ 870 BM_WBT_Beleuchtung 0 "inaktiv" 1 "aktiv" ;
VAL_ 870 BM_HD_Oeffnung_angelernt 0 "keine_Quittierung" 1 "Quittierung" ;
VAL_ 870 BM_Autobahn 0 "inaktiv" 1 "aktiv" ;
VAL_ 870 BM_Rollenmodus_Blinken 0 "inaktiv" 1 "aktiv" ;
VAL_ 870 BM_Recas 0 "kein_blinken" 1 "Recasblinken_aktiv" ;
VAL_ 870 BM_Wischblinken 0 "inaktiv" 1 "aktiv" ;
VAL_ 870 BM_Telematik_Abbruchgrund 0 "Init" 1 "speed_out_of_range" 2 "defect" 3 "clamp_s_on" 4 "clamp_15_on" 5 "door_open" 6 "engine_hood_open" 7 "trunk_open" 8 "convertible_top_not_locked" 9 "horn_activated_by_user" 10 "Higher_Prioritiy_Function_active" 11 "Central_Lock_status_changed" 12 "Request_Dropped_by_Requester" 13 "Service_Duration_Expired" 14 "not_possible_due_to_coding" 15 "no_reason_or_unknown_timeout" ;
VAL_ 870 BM_PiloPa 0 "PiloPa_Blinkerquittierung_inaktiv" 1 "PiloPa_Blinkerquittierung_aktiv" ;
VAL_ 870 SAL_TA_Blinken_Status 0 "init" 1 "nicht_bereit" 2 "bereit" 3 "aktiv_links" 4 "aktiv_rechts" ;
VAL_ 870 BM_WBA_Warnblinken 0 "WBA_Warnblinken_inaktiv" 1 "WBA_Warnblinken_aktiv" ;
VAL_ 870 SAL_RHP_Blinken_Status 0 "init" 1 "nicht_bereit" 2 "bereit" 3 "aktiv_links" 4 "aktiv_rechts" ;
VAL_ 870 SAL_RHP_Warnblinken 0 "inaktiv" 1 "aktiv" ;
VAL_ 1482 BMS_Energieinhalt 2046 "Init" 2047 "Fehler" ;
VAL_ 1482 BMS_Ladevorgang_aktiv 0 "inaktiv" 1 "aktiv" ;
VAL_ 1482 BMS_Batteriediagnose 1 "Anzeige_Batterie" 4 "Anzeige_Batterie_OK" 5 "Anzeige_Batterie_Laden" 6 "Anzeige_Batterie_Pruefen" 7 "Fehler" ;
VAL_ 1482 BMS_Balancing_Aktiv 0 "Init" 1 "aktiv" 2 "nicht_aktiv" ;
VAL_ 1482 BMS_MaxEnergieinhalt 2046 "Init" 2047 "Fehler" ;
VAL_ 1482 BMS_Ausgleichsladung_Anf 1 "Balancing_Request" ;
VAL_ 1482 BMS_Gesamtst_Spgfreiheit 0 "Funktion_nicht_aktiviert" 1 "HV_System_spannungsfrei" 2 "HV_System_nicht_spannungsfrei" 3 "Fehler_nicht_spannungsfrei" ;
VAL_ 1482 BMS_RIso_Ext 4094 "Init" 4095 "Fehler" ;
VAL_ 1482 BMS_KundenWarnung 0 "keine_Warnung" 1 "Warnung_Temperatur_Level1" 2 "Warnung_Temperatur_Level2" ;
VAL_ 2331596015 BSIS_Anzeigen_links 0 "keine_Anzeige" 1 "BSIS_Systemstoerung" 2 "BSIS_nicht_verfuegbar" 3 "BSIS_Sensor_eingeschraenkt" 4 "BSIS_Sensor_nicht_verfuegbar" 5 "BSIS_Anhaenger_eingeschraenkt" 6 "BSIS_Anhaenger_nicht_verfuegbar" 7 "BSIS_Fkt_deaktiviert" 8 "BSIS_Sound_deaktivert" 9 "BSIS_Warnton" ;
VAL_ 2331596015 BSIS_LED_Hell_links 126 "Init" 127 "Fehler" ;
VAL_ 2331596015 BSIS_LED_Ausgabemodus_links 0 "LED_aus" 1 "Infostufe" 2 "Warnstufe" 3 "Akutwarnstufe" 4 "Aufpruefen_BSIS" 5 "Demolauf_BSIS" ;
VAL_ 2331596016 BSIS_Anzeigen_rechts 0 "keine_Anzeige" 1 "BSIS_Systemstoerung" 2 "BSIS_nicht_verfuegbar" 3 "BSIS_Sensor_eingeschraenkt" 4 "BSIS_Sensor_nicht_verfuegbar" 5 "BSIS_Anhaenger_eingeschraenkt" 6 "BSIS_Anhaenger_nicht_verfuegbar" 7 "BSIS_Fkt_deaktiviert" 8 "BSIS_Sound_deaktivert" 9 "BSIS_Warnton" ;
VAL_ 2331596016 BSIS_LED_Hell_rechts 126 "Init" 127 "Fehler" ;
VAL_ 2331596016 BSIS_LED_Ausgabemodus_rechts 0 "LED_aus" 1 "Infostufe" 2 "Warnstufe" 3 "Akutwarnstufe" 4 "Aufpruefen_BSIS" 5 "Demolauf_BSIS" ;
VAL_ 2463978792 ZV_auto_Ansteuerung 0 "Kein_Autolock_Unlock" 1 "Autolock_Unlock" ;
VAL_ 2463978792 ZV_Bedienstelle_auf 0 "keine ZV Bedienstelle in Richtung auf betaetigt" 1 "Bedienstelle FT betaetigt" 2 "Bedienstelle Kessy erkannt" 3 "Bedienstelle Funk betaetigt" 4 "Bedienstelle NFC erkannt" 5 "Bedienstelle Mobile Device Key erkannt" 6 "Bedienstelle Notentriegelung Transponder erkannt" 7 "Bedienstelle Remote Unlock erkannt" 8 "Bedienstelle Emergency Assist erkannt" 9 "Bedienstelle VIP erkannt" ;
VAL_ 2463978792 ZV_Bedienstelle_zu 0 "keine ZV Bedienstelle in Richtung zu betaetigt" 1 "Bedienstelle FT betaetigt" 2 "Bedienstelle Kessy erkannt" 3 "Bedienstelle Funk betaetigt" 4 "Bedienstelle NFC erkannt" 5 "Bedienstelle Mobile Device Key erkannt" 6 "Bedienstelle Notverriegelung Transponder erkannt" 7 "Bedienstelle Remote Lock erkannt" 8 "Bedienstelle Precrash erkannt" 9 "Bedienstelle VIP erkannt" 10 "Bedienstelle ECL erkannt" 11 "Bedienstelle PiloPa erkannt" ;
VAL_ 2463978792 ZV_BT_entriegeln 0 "BT_nicht_entriegeln" 1 "BT_ist_zu_entriegeln" ;
VAL_ 2463978792 ZV_BT_verriegeln 0 "BT_nicht_verriegeln" 1 "BT_verriegeln" ;
VAL_ 2463978792 ZV_Crashfall_erkannt 0 "kein_Crashfall_erkannt" 1 "Crashfall_erkannt" ;
VAL_ 2463978792 ZV_FT_entriegeln 0 "FT_nicht_entriegeln" 1 "FT_entriegeln" ;
VAL_ 2463978792 ZV_FT_verriegeln 0 "FT_nicht_verriegeln" 1 "FT_verriegeln" ;
VAL_ 2463978792 ZV_HBFS_entriegeln 0 "inaktiv" 1 "aktiv" ;
VAL_ 2463978792 ZV_HBFS_verriegeln 0 "inaktiv" 1 "aktiv" ;
VAL_ 2463978792 ZV_HFS_entriegeln 0 "inaktiv" 1 "aktiv" ;
VAL_ 2463978792 ZV_HFS_verriegeln 0 "inaktiv" 1 "aktiv" ;
VAL_ 2463978792 ZV_LED_Steuerung 0 "LED_aus" 1 "LED_ein" ;
VAL_ 2463978792 ZV_LED_Uebernahme 0 "Init" 1 "TSG_uebernimmt_LED_Steuerung" ;
VAL_ 2463978792 ZV_gesafet_extern_ist_02 0 "Fahrzeug_nicht_gesafet" 1 "Fahrzeug_gesafet_Istzustand" 2 "Init" 3 "Fehler" ;
VAL_ 2463978792 ZV_Schluessel_Zugang 0 "kein_auth_Schluessel_erkannt" 1 "aktive_Funkschluessel_Nr_01" 2 "aktive_Funkschluessel_Nr_02" 3 "aktive_Funkschluessel_Nr_03" 4 "aktive_Funkschluessel_Nr_04" 5 "aktive_Funkschluessel_Nr_05" 6 "aktive_Funkschluessel_Nr_06" 7 "aktive_Funkschluessel_Nr_07" 8 "aktive_Funkschluessel_Nr_08" 9 "aktive_SmartDevice_Nr_09" 10 "ungueltig_10" 11 "ungueltig_11" 12 "ungueltig_12" 13 "ungueltig_13" 14 "ungueltig_14" 15 "ungueltig_15" ;
VAL_ 2463978792 ZV_Spg_Anklappen 0 "inaktiv" 1 "aktiv" ;
VAL_ 2463978792 ZV_verriegelt_extern_soll_03 0 "Fahrzeug_nicht_extern_verriegelt" 1 "Fahrzeug_extern_verriegelt_Sollz" 2 "Init" 3 "Fehler" ;
VAL_ 2463978792 ZV_zentral_entsafen 0 "Init" 1 "Befehl_zentral_entsafen" ;
VAL_ 2463978792 ZV_zentral_safen 0 "nicht_safen" 1 "Befehl_zentral_safen" ;
VAL_ 2463978792 ZV_zu_Zeitl_Nachverr 0 "Init" 1 "Nachverriegeln" ;
VAL_ 2463978792 ZV_TAG_BT_verfahren 0 "Init" 1 "TAG_ausfahren" 2 "TAG_einfahren" ;
VAL_ 2463978792 ZV_TAG_HBFS_verfahren 0 "Init" 1 "TAG_ausfahren" 2 "TAG_einfahren" ;
VAL_ 2463978792 ZV_TAG_FT_verfahren 0 "Init" 1 "TAG_ausfahren" 2 "TAG_einfahren" 3 "Fehler" ;
VAL_ 2463978792 ZV_TAG_HFS_verfahren 0 "Init" 1 "TAG_ausfahren" 2 "TAG_einfahren" ;
VAL_ 2463978792 IRUE_Taster_Fkts_LED 0 "LED_aus" 1 "LED_ein" ;
VAL_ 2463978792 DWA_aktiv 0 "unscharf" 1 "scharf" ;
VAL_ 2463978792 ZV_verriegelt_intern_soll_02 0 "Fahrzeug_nicht_innen_verriegelt" 1 "Fahrzeug_innen_verriegelt_Sollzu" 2 "Init" 3 "Fehler" ;
VAL_ 2463978792 ZV_Status_eTAG_ist 0 "Init" 1 "Türaussengriff._eingefahren (Istzustand)" 2 "Türaussengriff._ausgefahren ( (Istzustand)" ;
VAL_ 2463978792 ZV_Status_eTAG_soll 0 "Init" 1 "Türaussengriff._eingefahren (Sollzustand)" 2 "Türaussengriff._ausgefahren (Sollzustand)" ;
VAL_ 2463978792 ZV_verriegelt_extern_ist_02 0 "Fahrzeug_nicht_extern_verriegelt" 1 "Fahrzeug_extern_verriegelt_Ist" 2 "Init" 3 "Fehler" ;
VAL_ 2463978792 ZV_gesafet_extern_soll_02 0 "Fahrzeug_nicht_gesafet" 1 "Fahrzeug_gesafet_Sollzustand" 2 "Init" 3 "Fehler" ;
VAL_ 2463978792 ZV_verriegelt_intern_ist_02 0 "Fahrzeug_nicht_innen_verriegelt" 1 "Fahrzeug_innen_verriegelt_Istzus" 2 "Init" 3 "Fehler" ;
VAL_ 2463978792 ZV_Frontschloss_Vorraste 0 "geschlossen" 1 "offen" 2 "Init_oder_nicht_verbaut" 3 "Fehler" ;
VAL_ 902 CHA_Charisma_Taste2_LED 0 "LED_aus" 1 "LED_ein" 2 "LED_blinken" 3 "Fehler" ;
VAL_ 902 CHA_ReqPrgDispSetup 0 "init" 1 "layout_comfort" 2 "layout_eco" 3 "layout_sport" 4 "layout_offroad" 5 "layout_sportplus" 6 "program_6" 7 "program_7" 8 "program_8" 9 "program_9" 10 "program_10" 11 "program_11" 12 "program_12" 13 "program_13" 14 "program_14" 15 "program_15" ;
VAL_ 902 CHA_Current_Mode_FPA 0 "keine_Funktion" 1 "Programm_1" 2 "Programm_2" 3 "Programm_3" 4 "Programm_4" 5 "Programm_5" 6 "Programm_6" 7 "Programm_7" 8 "Programm_8" 9 "Programm_9" 10 "Programm_10" 11 "Programm_11" 12 "Programm_12" 13 "Programm_13" 14 "Programm_14" 15 "Programm_15" 16 "Programm_16" 17 "Programm_17" 18 "Programm_18" 19 "Programm_19" 20 "Programm_20" 21 "Programm_21" 22 "Programm_22" 23 "Programm_23" 24 "Programm_24" 25 "Programm_25" 26 "Programm_26" 27 "Programm_27" 28 "Programm_28" 29 "Programm_29" 30 "Programm_30" 31 "Programm_31" 32 "Programm_32" ;
VAL_ 902 CHA_Eco_Charisma_LED 0 "LED_aus_und_Blinken_aus" 1 "LED_ein_und_Blinken_aus" 2 "LED_ein_und_Blinken_ein_50_percent" 3 "reserviert" ;
VAL_ 902 CHA_Fahrer_Umschaltung 0 "keine_oder_automatische_Umschaltung" 1 "manuelle_Umschaltung" ;
VAL_ 902 CHA_EV_LED 0 "LED_aus" 1 "LED_an" ;
VAL_ 902 CHA_Ziel_FahrPr_AMB 0 "keine_Funktion" 1 "Programm_1" 2 "Programm_2" 3 "Programm_3" 4 "Programm_4" 5 "Programm_5" 6 "Programm_6" 7 "Programm_7" 8 "Programm_8" 9 "Programm_9" 10 "Programm_10" 11 "Programm_11" 12 "Programm_12" 13 "Programm_13" 14 "Programm_14" 15 "Programm_15" ;
VAL_ 902 CHA_Ziel_FahrPr_IVB 0 "keine_Funktion" 1 "Programm_1" 2 "Programm_2" 3 "Programm_3" 4 "Programm_4" 5 "Programm_5" 6 "Programm_6" 7 "Programm_7" 8 "Programm_8" 9 "Programm_9" 10 "Programm_10" 11 "Programm_11" 12 "Programm_12" 13 "Programm_13" 14 "Programm_14" 15 "Programm_15" ;
VAL_ 902 CHA_Kombi_Texte 0 "keine_Anzeige" 1 "Text_1" 2 "Text_2" 3 "Text_3" 4 "Text_4" 5 "Text_5" 6 "Text_6" 7 "Text_7" 8 "Text_8" 9 "Text_9" 10 "Text_10" 11 "Text_11" 12 "Text_12" 13 "Text_13" 14 "Text_14" 15 "Text_15" ;
VAL_ 902 CHA_Ziel_FahrPr_KL 0 "keine_Funktion" 1 "Programm_1" 2 "Programm_2" 3 "Programm_3" 4 "Programm_4" 5 "Programm_5" 6 "Programm_6" 7 "Programm_7" 8 "Programm_8" 9 "Programm_9" 10 "Programm_10" 11 "Programm_11" 12 "Programm_12" 13 "Programm_13" 14 "Programm_14" 15 "Programm_15" ;
VAL_ 902 CHA_Ziel_FahrPr_HSP 0 "keine_Funktion" 1 "Programm_1" 2 "Programm_2" 3 "Programm_3" 4 "Programm_4" 5 "Programm_5" 6 "Programm_6" 7 "Programm_7" 8 "Programm_8" 9 "Programm_9" 10 "Programm_10" 11 "Programm_11" 12 "Programm_12" 13 "Programm_13" 14 "Programm_14" 15 "Programm_15" ;
VAL_ 902 CHA_StCurProfDft 0 "Init" 1 "profile_is_not_configurable" 2 "profile_is_default" 3 "profile_is_not_default" ;
VAL_ 902 CHA_Ziel_FahrPr_RWB 0 "keine_Funktion" 1 "Programm_1" 2 "Programm_2" 3 "Programm_3" 4 "Programm_4" 5 "Programm_5" 6 "Programm_6" 7 "Programm_7" 8 "Programm_8" 9 "Programm_9" 10 "Programm_10" 11 "Programm_11" 12 "Programm_12" 13 "Programm_13" 14 "Programm_14" 15 "Programm_15" ;
VAL_ 902 CHA_Ziel_FahrPr_03_01 0 "keine_Funktion" 1 "Programm_1" 2 "Programm_2" 3 "Programm_3" 4 "Programm_4" 5 "Programm_5" 6 "Programm_6" 7 "Programm_7" 8 "Programm_8" 9 "Programm_9" 10 "Programm_10" 11 "Programm_11" 12 "Programm_12" 13 "Programm_13" 14 "Programm_14" 15 "Programm_15" ;
VAL_ 902 CHA_Ziel_FahrPr_03_02 0 "keine_Funktion" 1 "Programm_1" 2 "Programm_2" 3 "Programm_3" 4 "Programm_4" 5 "Programm_5" 6 "Programm_6" 7 "Programm_7" 8 "Programm_8" 9 "Programm_9" 10 "Programm_10" 11 "Programm_11" 12 "Programm_12" 13 "Programm_13" 14 "Programm_14" 15 "Programm_15" ;
VAL_ 902 CHA_Current_Mode 0 "keine_Funktion" 1 "Programm_1" 2 "Programm_2" 3 "Programm_3" 4 "Programm_4" 5 "Programm_5" 6 "Programm_6" 7 "Programm_7" 8 "Programm_8" 9 "Programm_9" 10 "Programm_10" 11 "Programm_11" 12 "Programm_12" 13 "Programm_13" 14 "Programm_14" 15 "Programm_15" ;
VAL_ 902 CHA_Charge_LED 0 "LED_aus" 1 "LED_ein" ;
VAL_ 902 CHA_Offroad_LED 0 "LED_aus" 1 "LED_ein" 2 "LED_blinken" 3 "Fehler" ;
VAL_ 902 CHA_Kombi_Texte_02 0 "Init" 1 "Text_1" 2 "Text_2" 3 "Text_3" 4 "Text_4" 5 "Text_5" 6 "Text_6" 7 "Text_7" 8 "Text_8" 9 "Text_9" 10 "Text_10" 11 "Text_11" 12 "Text_12" 13 "Text_13" 14 "Text_14" 15 "Text_15" ;
VAL_ 2463978646 CHA_Ziel_FahrPr_AGA 0 "keine_Funktion" 1 "Programm_1" 2 "Programm_2" 3 "Programm_3" 4 "Programm_4" 5 "Programm_5" 6 "Programm_6" 7 "Programm_7" 8 "Programm_8" 9 "Programm_9" 10 "Programm_10" 11 "Programm_11" 12 "Programm_12" 13 "Programm_13" 14 "Programm_14" 15 "Programm_15" ;
VAL_ 2463978646 CHA_Ziel_FahrPr_ESP 0 "keine_Funktion" 1 "Programm_1" 2 "Programm_2" 3 "Programm_3" 4 "Programm_4" 5 "Programm_5" 6 "Programm_6" 7 "Programm_7" 8 "Programm_8" 9 "Programm_9" 10 "Programm_10" 11 "Programm_11" 12 "Programm_12" 13 "Programm_13" 14 "Programm_14" 15 "Programm_15" ;
VAL_ 2463978646 CHA_Ziel_FahrPr_Freilauf 0 "keine_Funktion" 1 "Programm_1" 2 "Programm_2" 3 "Programm_3" 4 "Programm_4" 5 "Programm_5" 6 "Programm_6" 7 "Programm_7" 8 "Programm_8" 9 "Programm_9" 10 "Programm_10" 11 "Programm_11" 12 "Programm_12" 13 "Programm_13" 14 "Programm_14" 15 "Programm_15" ;
VAL_ 2463978646 CHA_Fahrer_Umschaltung 0 "keine_oder_automatische_Umschaltung" 1 "manuelle_Umschaltung" ;
VAL_ 2463978646 CHA_Fahrer_Umschaltung_BMA 0 "keine_oder_autom_Umschaltung" 1 "manuelle_Umschaltung" ;
VAL_ 2463978646 CHA_Ziel_FahrPr_MO 0 "keine_Funktion" 1 "Programm_1" 2 "Programm_2" 3 "Programm_3" 4 "Programm_4" 5 "Programm_5" 6 "Programm_6" 7 "Programm_7" 8 "Programm_8" 9 "Programm_9" 10 "Programm_10" 11 "Programm_11" 12 "Programm_12" 13 "Programm_13" 14 "Programm_14" 15 "Programm_15" ;
VAL_ 2463978646 CHA_Ziel_FahrPr_GE 0 "keine_Funktion" 1 "Programm_1" 2 "Programm_2" 3 "Programm_3" 4 "Programm_4" 5 "Programm_5" 6 "Programm_6" 7 "Programm_7" 8 "Programm_8" 9 "Programm_9" 10 "Programm_10" 11 "Programm_11" 12 "Programm_12" 13 "Programm_13" 14 "Programm_14" 15 "Programm_15" ;
VAL_ 2463978646 CHA_Ziel_FahrPr_ALR 0 "keine_Funktion" 1 "Programm_1" 2 "Programm_2" 3 "Programm_3" 4 "Programm_4" 5 "Programm_5" 6 "Programm_6" 7 "Programm_7" 8 "Programm_8" 9 "Programm_9" 10 "Programm_10" 11 "Programm_11" 12 "Programm_12" 13 "Programm_13" 14 "Programm_14" 15 "Programm_15" ;
VAL_ 2463978646 CHA_Ziel_FahrPr_MO_BZS 0 "keine_Funktion" 1 "Programm_1" 2 "Programm_2" 3 "Programm_3" 4 "Programm_4" 5 "Programm_5" 6 "Programm_6" 7 "Programm_7" 8 "Programm_8" 9 "Programm_9" 10 "Programm_10" 11 "Programm_11" 12 "Programm_12" 13 "Programm_13" 14 "Programm_14" 15 "Programm_15" ;
VAL_ 2463978646 CHA_Ziel_FahrPr_DR 0 "keine_Funktion" 1 "Programm_1" 2 "Programm_2" 3 "Programm_3" 4 "Programm_4" 5 "Programm_5" 6 "Programm_6" 7 "Programm_7" 8 "Programm_8" 9 "Programm_9" 10 "Programm_10" 11 "Programm_11" 12 "Programm_12" 13 "Programm_13" 14 "Programm_14" 15 "Programm_15" ;
VAL_ 2463978646 CHA_Ziel_FahrPr_VAQ 0 "keine_Funktion" 1 "Programm_1" 2 "Programm_2" 3 "Programm_3" 4 "Programm_4" 5 "Programm_5" 6 "Programm_6" 7 "Programm_7" 8 "Programm_8" 9 "Programm_9" 10 "Programm_10" 11 "Programm_11" 12 "Programm_12" 13 "Programm_13" 14 "Programm_14" 15 "Programm_15" ;
VAL_ 2463978646 CHA_Ziel_FahrPr_AFS 0 "keine_Funktion" 1 "Programm_1" 2 "Programm_2" 3 "Programm_3" 4 "Programm_4" 5 "Programm_5" 6 "Programm_6" 7 "Programm_7" 8 "Programm_8" 9 "Programm_9" 10 "Programm_10" 11 "Programm_11" 12 "Programm_12" 13 "Programm_13" 14 "Programm_14" 15 "Programm_15" ;
VAL_ 2463978646 CHA_Ziel_FahrPr_PreCrash 0 "keine_Funktion" 1 "Programm_1" 2 "Programm_2" 3 "Programm_3" 4 "Programm_4" 5 "Programm_5" 6 "Programm_6" 7 "Programm_7" 8 "Programm_8" 9 "Programm_9" 10 "Programm_10" 11 "Programm_11" 12 "Programm_12" 13 "Programm_13" 14 "Programm_14" 15 "Programm_15" ;
VAL_ 2463978646 CHA_Ziel_FahrPr_EPS 0 "keine_Funktion" 1 "Programm_1" 2 "Programm_2" 3 "Programm_3" 4 "Programm_4" 5 "Programm_5" 6 "Programm_6" 7 "Programm_7" 8 "Programm_8" 9 "Programm_9" 10 "Programm_10" 11 "Programm_11" 12 "Programm_12" 13 "Programm_13" 14 "Programm_14" 15 "Programm_15" ;
VAL_ 2463978646 CHA_Ziel_FahrPr_ACC 0 "keine_Funktion" 1 "Programm_1" 2 "Programm_2" 3 "Programm_3" 4 "Programm_4" 5 "Programm_5" 6 "Programm_6" 7 "Programm_7" 8 "Programm_8" 9 "Programm_9" 10 "Programm_10" 11 "Programm_11" 12 "Programm_12" 13 "Programm_13" 14 "Programm_14" 15 "Programm_15" ;
VAL_ 2463978646 CHA_Ziel_FahrPr_SAK 0 "keine_Funktion" 1 "Programm_1" 2 "Programm_2" 3 "Programm_3" 4 "Programm_4" 5 "Programm_5" 6 "Programm_6" 7 "Programm_7" 8 "Programm_8" 9 "Programm_9" 10 "Programm_10" 11 "Programm_11" 12 "Programm_12" 13 "Programm_13" 14 "Programm_14" 15 "Programm_15" ;
VAL_ 2463978646 CHA_Ziel_FahrPr_MO_StSt 0 "keine_Funktion" 1 "Programm_1" 2 "Programm_2" 3 "Programm_3" 4 "Programm_4" 5 "Programm_5" 6 "Programm_6" 7 "Programm_7" 8 "Programm_8" 9 "Programm_9" 10 "Programm_10" 11 "Programm_11" 12 "Programm_12" 13 "Programm_13" 14 "Programm_14" 15 "Programm_15" ;
VAL_ 2463978646 CHA_Ziel_FahrPr_EBKV 0 "keine_Funktion" 1 "Programm_1" 2 "Programm_2" 3 "Programm_3" 4 "Programm_4" 5 "Programm_5" 6 "Programm_6" 7 "Programm_7" 8 "Programm_8" 9 "Programm_9" 10 "Programm_10" 11 "Programm_11" 12 "Programm_12" 13 "Programm_13" 14 "Programm_14" 15 "Programm_15" ;
VAL_ 2463978646 CHA_Ziel_FahrPr_IL 0 "keine_Funktion" 1 "Programm_1" 2 "Programm_2" 3 "Programm_3" 4 "Programm_4" 5 "Programm_5" 6 "Programm_6" 7 "Programm_7" 8 "Programm_8" 9 "Programm_9" 10 "Programm_10" 11 "Programm_11" 12 "Programm_12" 13 "Programm_13" 14 "Programm_14" 15 "Programm_15" ;
VAL_ 2463978646 CHA_Current_Mode 0 "keine_Funktion" 1 "Programm_1" 2 "Programm_2" 3 "Programm_3" 4 "Programm_4" 5 "Programm_5" 6 "Programm_6" 7 "Programm_7" 8 "Programm_8" 9 "Programm_9" 10 "Programm_10" 11 "Programm_11" 12 "Programm_12" 13 "Programm_13" 14 "Programm_14" 15 "Programm_15" ;
VAL_ 2463978646 CHA_Ziel_FahrPr_QS 0 "keine_Funktion" 1 "Programm_1" 2 "Programm_2" 3 "Programm_3" 4 "Programm_4" 5 "Programm_5" 6 "Programm_6" 7 "Programm_7" 8 "Programm_8" 9 "Programm_9" 10 "Programm_10" 11 "Programm_11" 12 "Programm_12" 13 "Programm_13" 14 "Programm_14" 15 "Programm_15" ;
VAL_ 2463978646 CHA_Ziel_FahrPr_SCU 0 "keine_Funktion" 1 "Programm_1" 2 "Programm_2" 3 "Programm_3" 4 "Programm_4" 5 "Programm_5" 6 "Programm_6" 7 "Programm_7" 8 "Programm_8" 9 "Programm_9" 10 "Programm_10" 11 "Programm_11" 12 "Programm_12" 13 "Programm_13" 14 "Programm_14" 15 "Programm_15" ;
VAL_ 2463978646 CHA_Ziel_FahrPr_HAL 0 "keine_Funktion" 1 "Programm_1" 2 "Programm_2" 3 "Programm_3" 4 "Programm_4" 5 "Programm_5" 6 "Programm_6" 7 "Programm_7" 8 "Programm_8" 9 "Programm_9" 10 "Programm_10" 11 "Programm_11" 12 "Programm_12" 13 "Programm_13" 14 "Programm_14" 15 "Programm_15" ;
VAL_ 2463978646 CHA_Ziel_FahrPr_NR 0 "keine_Funktion" 1 "Programm_1" 2 "Programm_2" 3 "Programm_3" 4 "Programm_4" 5 "Programm_5" 6 "Programm_6" 7 "Programm_7" 8 "Programm_8" 9 "Programm_9" 10 "Programm_10" 11 "Programm_11" 12 "Programm_12" 13 "Programm_13" 14 "Programm_14" 15 "Programm_15" ;
VAL_ 2463978646 CHA_Ziel_FahrPr_AV 0 "keine_Funktion" 1 "Programm_1" 2 "Programm_2" 3 "Programm_3" 4 "Programm_4" 5 "Programm_5" 6 "Programm_6" 7 "Programm_7" 8 "Programm_8" 9 "Programm_9" 10 "Programm_10" 11 "Programm_11" 12 "Programm_12" 13 "Programm_13" 14 "Programm_14" 15 "Programm_15" ;
VAL_ 2463978646 CHA_Ziel_FahrPr_MXB 0 "keine_Funktion" 1 "Programm_1" 2 "Programm_2" 3 "Programm_3" 4 "Programm_4" 5 "Programm_5" 6 "Programm_6" 7 "Programm_7" 8 "Programm_8" 9 "Programm_9" 10 "Programm_10" 11 "Programm_11" 12 "Programm_12" 13 "Programm_13" 14 "Programm_14" 15 "Programm_15" ;
VAL_ 2463978646 CHA_Ziel_FahrPr_AFR 0 "keine_Funktion" 1 "Programm_1" 2 "Programm_2" 3 "Programm_3" 4 "Programm_4" 5 "Programm_5" 6 "Programm_6" 7 "Programm_7" 8 "Programm_8" 9 "Programm_9" 10 "Programm_10" 11 "Programm_11" 12 "Programm_12" 13 "Programm_13" 14 "Programm_14" 15 "Programm_15" ;
VAL_ 2463978646 CHA_Ziel_FahrPr_HDC 0 "keine_Funktion" 1 "Programm_1" 2 "Programm_2" 3 "Programm_3" 4 "Programm_4" 5 "Programm_5" 6 "Programm_6" 7 "Programm_7" 8 "Programm_8" 9 "Programm_9" 10 "Programm_10" 11 "Programm_11" 12 "Programm_12" 13 "Programm_13" 14 "Programm_14" 15 "Programm_15" ;
VAL_ 2463978646 CHA_Ziel_FahrPr_EAR 0 "keine_Funktion" 1 "Programm_1" 2 "Programm_2" 3 "Programm_3" 4 "Programm_4" 5 "Programm_5" 6 "Programm_6" 7 "Programm_7" 8 "Programm_8" 9 "Programm_9" 10 "Programm_10" 11 "Programm_11" 12 "Programm_12" 13 "Programm_13" 14 "Programm_14" 15 "Programm_15" ;
VAL_ 2463978646 CHA_Ziel_FahrPr_AEB 0 "keine_Funktion" 1 "Programm_1" 2 "Programm_2" 3 "Programm_3" 4 "Programm_4" 5 "Programm_5" 6 "Programm_6" 7 "Programm_7" 8 "Programm_8" 9 "Programm_9" 10 "Programm_10" 11 "Programm_11" 12 "Programm_12" 13 "Programm_13" 14 "Programm_14" 15 "Programm_15" ;
VAL_ 2463978646 CHA_Ziel_FahrPr_FCWO 0 "keine_Funktion" 1 "Programm_1" 2 "Programm_2" 3 "Programm_3" 4 "Programm_4" 5 "Programm_5" 6 "Programm_6" 7 "Programm_7" 8 "Programm_8" 9 "Programm_9" 10 "Programm_10" 11 "Programm_11" 12 "Programm_12" 13 "Programm_13" 14 "Programm_14" 15 "Programm_15" ;
VAL_ 2463978646 CHA_Ziel_FahrPr_FCWP 0 "keine_Funktion" 1 "Programm_1" 2 "Programm_2" 3 "Programm_3" 4 "Programm_4" 5 "Programm_5" 6 "Programm_6" 7 "Programm_7" 8 "Programm_8" 9 "Programm_9" 10 "Programm_10" 11 "Programm_11" 12 "Programm_12" 13 "Programm_13" 14 "Programm_14" 15 "Programm_15" ;
VAL_ 2463978646 CHA_Ziel_FahrPr_eSound 0 "keine_Funktion" 1 "Programm_1" 2 "Programm_2" 3 "Programm_3" 4 "Programm_4" 5 "Programm_5" 6 "Programm_6" 7 "Programm_7" 8 "Programm_8" 9 "Programm_9" 10 "Programm_10" 11 "Programm_11" 12 "Programm_12" 13 "Programm_13" 14 "Programm_14" 15 "Programm_15" ;
VAL_ 2463978646 CHA_Ziel_FahrPr_RHP 0 "keine_Funktion" 1 "Programm_1" 2 "Programm_2" 3 "Programm_3" 4 "Programm_4" 5 "Programm_5" 6 "Programm_6" 7 "Programm_7" 8 "Programm_8" 9 "Programm_9" 10 "Programm_10" 11 "Programm_11" 12 "Programm_12" 13 "Programm_13" 14 "Programm_14" 15 "Programm_15" ;
VAL_ 2463978646 CHA_Ziel_FahrPr_ToS_laengs 0 "keine_Funktion" 1 "Programm_1" 2 "Programm_2" 3 "Programm_3" 4 "Programm_4" 5 "Programm_5" 6 "Programm_6" 7 "Programm_7" 8 "Programm_8" 9 "Programm_9" 10 "Programm_10" 11 "Programm_11" 12 "Programm_12" 13 "Programm_13" 14 "Programm_14" 15 "Programm_15" ;
VAL_ 2463978646 CHA_Ziel_FahrPr_ToS_quer 0 "keine_Funktion" 1 "Programm_1" 2 "Programm_2" 3 "Programm_3" 4 "Programm_4" 5 "Programm_5" 6 "Programm_6" 7 "Programm_7" 8 "Programm_8" 9 "Programm_9" 10 "Programm_10" 11 "Programm_11" 12 "Programm_12" 13 "Programm_13" 14 "Programm_14" 15 "Programm_15" ;
VAL_ 2463978646 CHA_Ziel_FahrPr_mFDR 0 "keine_Funktion" 1 "Programm_1" 2 "Programm_2" 3 "Programm_3" 4 "Programm_4" 5 "Programm_5" 6 "Programm_6" 7 "Programm_7" 8 "Programm_8" 9 "Programm_9" 10 "Programm_10" 11 "Programm_11" 12 "Programm_12" 13 "Programm_13" 14 "Programm_14" 15 "Programm_15" ;
VAL_ 2463978646 CHA_Ziel_FahrPr_Reku_ZwGas 0 "kein_Funktion" 1 "Programm_1" 2 "Programm_2" 3 "Programm_3" 4 "Programm_4" 5 "Programm_5" 6 "Programm_6" 7 "Programm_7" 8 "Programm_8" 9 "Programm_9" 10 "Programm_10" 11 "Programm_11" 12 "Programm_12" 13 "Programm_13" 14 "Programm_14" 15 "Programm_15" ;
VAL_ 2463978646 CHA_Ziel_FahrPr_MO_Freilauf 0 "keine_Funktion" 1 "Programm_1" 2 "Programm_2" 3 "Programm_3" 4 "Programm_4" 5 "Programm_5" 6 "Programm_6" 7 "Programm_7" 8 "Programm_8" 9 "Programm_9" 10 "Programm_10" 11 "Programm_11" 12 "Programm_12" 13 "Programm_13" 14 "Programm_14" 15 "Programm_15" ;
VAL_ 2463978646 CHA_Ziel_FahrPr_BMS 0 "keine_Funktion" 1 "Programm_1" 2 "Programm_2" 3 "Programm_3" 4 "Programm_4" 5 "Programm_5" 6 "Programm_6" 7 "Programm_7" 8 "Programm_8" 9 "Programm_9" 10 "Programm_10" 11 "Programm_11" 12 "Programm_12" 13 "Programm_13" 14 "Programm_14" 15 "Programm_15" ;
VAL_ 2463978646 CHA_Ziel_FahrPr_PDC 0 "keine_Funktion" 1 "Programm_1" 2 "Programm_2" 3 "Programm_3" 4 "Programm_4" 5 "Programm_5" 6 "Programm_6" 7 "Programm_7" 8 "Programm_8" 9 "Programm_9" 10 "Programm_10" 11 "Programm_11" 12 "Programm_12" 13 "Programm_13" 14 "Programm_14" 15 "Programm_15" ;
VAL_ 2463978646 CHA_Ziel_FahrPr_HHC 0 "keine_Funktion" 1 "Programm_1" 2 "Programm_2" 3 "Programm_3" 4 "Programm_4" 5 "Programm_5" 6 "Programm_6" 7 "Programm_7" 8 "Programm_8" 9 "Programm_9" 10 "Programm_10" 11 "Programm_11" 12 "Programm_12" 13 "Programm_13" 14 "Programm_14" 15 "Programm_15" ;
VAL_ 2463978646 CHA_Ziel_FahrPr_EDS 0 "keine_Funktion" 1 "Programm_1" 2 "Programm_2" 3 "Programm_3" 4 "Programm_4" 5 "Programm_5" 6 "Programm_6" 7 "Programm_7" 8 "Programm_8" 9 "Programm_9" 10 "Programm_10" 11 "Programm_11" 12 "Programm_12" 13 "Programm_13" 14 "Programm_14" 15 "Programm_15" ;
VAL_ 2463978646 CHA_Ziel_FahrPr_PACC 0 "keine_Funktion" 1 "Programm_1" 2 "Programm_2" 3 "Programm_3" 4 "Programm_4" 5 "Programm_5" 6 "Programm_6" 7 "Programm_7" 8 "Programm_8" 9 "Programm_9" 10 "Programm_10" 11 "Programm_11" 12 "Programm_12" 13 "Programm_13" 14 "Programm_14" 15 "Programm_15" ;
VAL_ 2463978646 CHA_Ziel_FahrPr_AGK 0 "keine_Funktion" 1 "Programm_1" 2 "Programm_2" 3 "Programm_3" 4 "Programm_4" 5 "Programm_5" 6 "Programm_6" 7 "Programm_7" 8 "Programm_8" 9 "Programm_9" 10 "Programm_10" 11 "Programm_11" 12 "Programm_12" 13 "Programm_13" 14 "Programm_14" 15 "Programm_15" ;
VAL_ 2527679921 CPD_CallCenter 0 "Init_keine_Alarmierung_CallCenter" 1 "CPD_Alarmierung_CallCenter" 2 "CPD_Abbruch_CallCenter" 3 "reserved" ;
VAL_ 2527679921 CPD_Deaktivierung_Temp 0 "InitWert" 1 "keine_Deaktivierung_Temp" 2 "CPD_Deaktivierung_Temp" ;
VAL_ 2527679921 CPD_Deaktivierung_Permanent 0 "InitWert" 1 "keine_Deaktivierung_Permanent" 2 "CPD_Deaktivierung_Permanent" ;
VAL_ 2527679921 CPD_Mobiltelefon_GSM 0 "Init_keine_Warnung_GSM" 1 "CPD_Warnung_GSM" 2 "reserved" 3 "reserved" ;
VAL_ 2527679921 CPD_Mobiltelefon_BLE 0 "Init_keine_Warnung_BT" 1 "CPD_Warnung_BT" ;
VAL_ 2527679921 CPDFct_Warnung 0 "keine_Anzeige" 1 "Warnung_mit_Ton" 2 "Warnung_ohne_Ton" 3 "Anzeige_Funktion_deaktiviert" 4 "Anzeige_Systemfehler" ;
VAL_ 2527679921 CPDFct_Symbol 0 "Keine_Anzeige" 1 "aktiv" ;
VAL_ 2527679921 CPDFct_Deakt 0 "keine_Anzeige" 1 "Anzeige_Funktion_deaktiviert" ;
VAL_ 2331595987 CPD_Sensierung_Status 0 "Init" 1 "kein_Fehler" 2 "Lebewesen_sensiert" 3 "Sensorsicht_blockiert" 4 "Sensierung_aktiv" 7 "Fehler" ;
VAL_ 2331595987 CPD_Warnstufe 0 "Keine_Warnstufe" 1 "Warnstufe_1" 2 "Warnstufe_2" 3 "Warnstufe_3" 4 "Warnstufe_4" 5 "Warnstufe_5" 6 "Warnstufe_6" 7 "Warnstufe_Abbruch" ;
VAL_ 515 DR_Drehwinkelsensortausch_VL 0 "Init" ;
VAL_ 515 DR_Drehwinkelsensortausch_VR 0 "Init" ;
VAL_ 515 DR_Drehwinkelsensortausch_HL 0 "Init" ;
VAL_ 515 DR_Drehwinkelsensortausch_HR 0 "Init" ;
VAL_ 515 DR_Drehwinkel_VL 4091 "nicht_verwendet" 4092 "nicht_verwendet" 4093 "Sensor_nicht_verbaut" 4094 "Init" 4095 "Fehler" ;
VAL_ 515 DR_Drehwinkel_VR 4091 "nicht_verwendet" 4092 "nicht_verwendet" 4093 "Sensor_nicht_verbaut" 4094 "Init" 4095 "Fehler" ;
VAL_ 515 DR_Drehwinkel_HL 4091 "nicht_verwendet" 4092 "nicht_verwendet" 4093 "Sensor_nicht_verbaut" 4094 "Init" 4095 "Fehler" ;
VAL_ 515 DR_Drehwinkel_HR 4091 "nicht_verwendet" 4092 "nicht_verwendet" 4093 "Sensor_nicht_verbaut" 4094 "Init" 4095 "Fehler" ;
